VERSION ""

NS_ :

BS_:

BU_: WCM VPM VLM VKM UVM TIM TEST_TOOL_2 TEST_TOOL_1 TCP TCM TCCM3 TCCM STC SRR_SRR SRR_SLR SRR_RR SRR_RF SRR_LR_CR SRR_LF SIB SDM SCL SBZA_R SBZA_L SBM SADS RadioLow RSC RDCM PTM PDR PA NVM MTCM_R MTCM_L MSM_RR MSM_P MSM_LR MSM_D MSB2 MSB1 MRCM_R MRCM_L MFC LRR_HC LRR LIB1 IPC ICS_Info ICCM HVAC_FP_R HVAC_FP_F HUD_CAN HDLM FCM_LC FCM EPS EOCM_HCP2 EOCM_HCP1 EOCM ELM ECP_X1 ECP_MC ECP_E ECM EBCM DMS DEFC DCM CSM CMMb CMMa CGM BSM_MH BSM BCM ARS ARB APA AOS AMP ALC AHS AHL_AFL AGC
VAL_TABLE_ SRRSRRODPB1P_POTk1DynPrpAuth 0 "Has Never Moved" 1 "Has Moved But Currently Stopped" 2 "Moving In Same Direction As Host" 3 "Moving In Opposite Direction As Host" 4 "Crossing Path" ;
VAL_TABLE_ SRRSRRODPB1P_POTk1CnfdStsAuth 0 "Highly Speculative" 1 "Speculative" 2 "Confident" 3 "Highly Confident" ;
VAL_TABLE_ SRRSRRODPB1P_MdCmdStsAuth 0 "Not Radiating" 1 "Reporting Object Data" 2 "Not Reporting Object Data" ;
VAL_TABLE_ SRRSRRODPB1P_CnstrArDtnStsAuth 0 "Not Detected" 1 "Detected" 2 "Unknown" ;
VAL_TABLE_ SRRSRRODPB1P_POTk1MStsAuth 0 "No Object" 1 "New Object" 2 "Latent Track Not Detected this Cycle" 3 "Measured this Cycle" ;
VAL_TABLE_ SRRSRRODPB1P_POTk2CnfdStsAuth 0 "Highly Speculative" 1 "Speculative" 2 "Confident" 3 "Highly Confident" ;
VAL_TABLE_ SRRSRRODPB1P_POTk1TypCnfdAuth 0 "Highly Speculative" 1 "Speculative" 2 "Confident" 3 "Highly Confident" ;
VAL_TABLE_ SRRSRRODPB1P_POTk1TypAuth 0 "Unknown" 1 "Pedestrian" 2 "Bicycle" ;
VAL_TABLE_ SRRSRRODPB1P_POTk2DynPrpAuth 0 "Has Never Moved" 1 "Has Moved But Currently Stopped" 2 "Moving In Same Direction As Host" 3 "Moving In Opposite Direction As Host" 4 "Crossing Path" ;
VAL_TABLE_ SRRSRRODPB1P_POTk2MStsAuth 0 "No Object" 1 "New Object" 2 "Latent Track Not Detected this Cycle" 3 "Measured this Cycle" ;
VAL_TABLE_ SRRSRRODPB1P_POTk2TypCnfdAuth 0 "Highly Speculative" 1 "Speculative" 2 "Confident" 3 "Highly Confident" ;
VAL_TABLE_ SRRSRRODPB1P_POTk2TypAuth 0 "Unknown" 1 "Pedestrian" 2 "Bicycle" ;
VAL_TABLE_ SRRSRRODPB1P_SnsrUnvAuth 0 "FALSE" 1 "TRUE" ;
VAL_TABLE_ SRRSRRODPB1P_SnsrBlckdAuth 0 "FALSE" 1 "TRUE" ;
VAL_TABLE_ SRRSRRODPB1P_ServRqrdAuth 0 "FALSE" 1 "TRUE" ;
VAL_TABLE_ SRRSRRODPB1P_RdTypCnfdAuth 0 "Highly Speculative" 1 "Speculative" 2 "Confident" 3 "Highly Confident" ;
VAL_TABLE_ SRRSRRODPB1P_RdTypAuth 0 "Unknown" 1 "City" 2 "Secondary Road" 3 "Highway" 4 "Construction" 5 "Zone Entry" 6 "Construction" 7 "Zone Exit" ;
VAL_TABLE_ SRRSRRODPB1P_SwpBndwdthStsAuth 0 "Mode A" 1 "Mode B" 2 "Mode C" 3 "Mode D" ;
VAL_TABLE_ SRRSRRODPB1P_VOTk1DynPrpStsAuth 0 "Stopped" 1 "Not Stopped" ;
VAL_TABLE_ SRRSRRODPB1P_VOTk1DynPrpAuth 0 "Has Never Moved" 1 "Moving In Same Direction As Host" 2 "Moving In Opposite Direction As Host" 3 "Crossing From Left To Right" 4 "Crossing From Right To Left" ;
VAL_TABLE_ SRRSRRODPB1P_VOTk1CnfdStsAuth 0 "Highly Speculative" 1 "Speculative" 2 "Confident" 3 "Highly Confident" ;
VAL_TABLE_ SRRSRRODPB1P_VOTk1MStsAuth 0 "No Object" 1 "New Object" 2 "Latent Track Not Detected this Cycle" 3 "Measured this Cycle" ;
VAL_TABLE_ SRRSRRODPB1P_VOTk1TypCnfdAuth 0 "Highly Speculative" 1 "Speculative" 2 "Confident" 3 "Highly Confident" ;
VAL_TABLE_ SRRSRRODPB6P_REOTk1CnfdStsAuth 0 "Highly Speculative" 1 "Speculative" 2 "Confident" 3 "Highly Confident" ;
VAL_TABLE_ SRRSRRODPB6P_REOTk2CnfdStsAuth 0 "Highly Speculative" 1 "Speculative" 2 "Confident" 3 "Highly Confident" ;
VAL_TABLE_ SRRSRRODPB6P_REOTk1TypCnfdAuth 0 "Highly Speculative" 1 "Speculative" 2 "Confident" 3 "Highly Confident" ;
VAL_TABLE_ SRRSRRODPB6P_REOTk1TypAuth 0 "Unknown" 1 "Barriers" 2 "Guard Rails" 3 "Bridge Abutments" 4 "Edge of Road" 5 "Open Area" ;
VAL_TABLE_ SRRSRRODPB6P_REOTk3CnfdStsAuth 0 "Highly Speculative" 1 "Speculative" 2 "Confident" 3 "Highly Confident" ;
VAL_TABLE_ SRRSRRODPB6P_REOTk2TypCnfdAuth 0 "Highly Speculative" 1 "Speculative" 2 "Confident" 3 "Highly Confident" ;
VAL_TABLE_ SRRSRRODPB6P_REOTk2TypAuth 0 "Unknown" 1 "Barriers" 2 "Guard Rails" 3 "Bridge Abutments" 4 "Edge of Road" 5 "Open Area" ;
VAL_TABLE_ SRRSRRODPB6P_REOTk3TypCnfdAuth 0 "Highly Speculative" 1 "Speculative" 2 "Confident" 3 "Highly Confident" ;
VAL_TABLE_ SRRSRRODPB6P_REOTk3TypAuth 0 "Unknown" 1 "Barriers" 2 "Guard Rails" 3 "Bridge Abutments" 4 "Edge of Road" 5 "Open Area" ;
VAL_TABLE_ YRP_YawRateAuth_Inv 0 "FALSE" 1 "TRUE" ;
VAL_TABLE_ SWIP_StrgWhlAngAuth_Inv 0 "FALSE" 1 "TRUE" ;
VAL_TABLE_ SWIP_StrgWhlAngAuth_DuD 0 "FALSE" 1 "TRUE" ;
VAL_TABLE_ DRCDNDP_DRCAvgDrvnAuth_Inv 0 "FALSE" 1 "TRUE" ;
VAL_TABLE_ VODVP_VehOdoDispValAuth_Inv 0 "FALSE" 1 "TRUE" ;
VAL_TABLE_ OATP_OtsAirTmpCrValAuth_Inv 0 "FALSE" 1 "TRUE" ;
VAL_TABLE_ CldrMth 0 "Unknown" 1 "January" 2 "February" 3 "March" 4 "April" 5 "May" 6 "June" 7 "July" 8 "August" 9 "September" 10 "October" 11 "November" 12 "December" ;
VAL_TABLE_ ELWWIP_WprFrtFtrReqAuth 0 "Wiper Front Stop" 1 "Wiper Front Crank Suspend" 2 "Wiper Front Depressed Park" 3 "Wiper Front Park" 4 "Wiper Front Winter Park" 5 "Wiper Front Service Park" 6 "Wiper Front Intermittent 5" 7 "Wiper Front Intermittent 4" 8 "Wiper Front Intermittent 3" 9 "Wiper Front Intermittent 2" 10 "Wiper Front Intermittent 1" 11 "Wiper Front Low Wipe" 12 "Wiper Front High Wipe" ;
VAL_TABLE_ VMMP_VehMtnMvmtStatAuth 0 "Parked" 1 "Neutral" 2 "Forward" 3 "Reverse" 4 "Invalid" ;
VAL_TABLE_ SBZVisIndExtrnCktFltPrLtGtd 0 "FALSE" 1 "TRUE" ;
VAL_TABLE_ SBZVisIndExtrnCktFltPrLtGtd_Inv 0 "FALSE" 1 "TRUE" ;
VAL_TABLE_ DrSlctdSpdLmtAutMdSpdLmtStat 0 "No Set Speed Change" 1 "Proposed Speed Limit Change" 2 "Accepted Speed Limit Change" 3 "Declined Speed Limit Change" ;
VAL_TABLE_ AutoBmSlctAllwd 0 "FALSE" 1 "TRUE" ;
VAL_TABLE_ AutoBmSlctAllwd_Inv 0 "FALSE" 1 "TRUE" ;
VAL_TABLE_ TrlrHtchTyp 0 "Unknown" 1 "Conventional" 2 "5th Wheel" 3 "Gooseneck" ;
VAL_TABLE_ DrvrSeltdTrlrPrsnt 0 "Trailer Present" 1 "No Trailer" ;
VAL_TABLE_ FgLmpFrtRtCmd 0 "FALSE" 1 "TRUE" ;
VAL_TABLE_ FgLmpFrtLftCmd 0 "FALSE" 1 "TRUE" ;
VAL_TABLE_ LogisticModeStatus 0 "Off" 1 "Plant" 2 "Transport Mode" 3 "Storage Mode" ;
VAL_TABLE_ SBZVisIndExtrnCktFltPrRtGtd 0 "FALSE" 1 "TRUE" ;
VAL_TABLE_ SBZVisIndExtrnCktFltPrRtGtd_Inv 0 "FALSE" 1 "TRUE" ;
VAL_TABLE_ SBZAlrtCstChngSetReq 0 "NO_ACTION" 1 "OFF" 2 "ON" 3 "RESERVED_3" 4 "RESERVED_4" 5 "RESERVED_5" 6 "RESERVED_6" 7 "RESERVED_7" ;
VAL_TABLE_ LnChgAlrtCstChngSetReq 0 "NO_ACTION" 1 "OFF" 2 "ON" 3 "RESERVED_3" 4 "RESERVED_4" 5 "RESERVED_5" 6 "RESERVED_6" 7 "RESERVED_7" ;
VAL_TABLE_ APASP_APAStsAuth 0 "Off" 1 "Standby" 2 "Search_Phase" 3 "Exit_Park" 4 "Enabled" 5 "Guidance_Phase" 6 "Finished" 7 "Error" ;
VAL_TABLE_ HSP_DrvAlrtTypCstCurrSetValAuth 0 "SETTING_UNKNOWN" 1 "CHIME" 2 "SEAT" ;
VAL_TABLE_ HSP_HptcStOprtlStsAuth 0 "Normal Operation" 1 "Unknown" 2 "Failed" ;
VAL_TABLE_ TrffcLgtAsstCstChgSetReq 0 "NO_ACTION" 1 "OFF" 2 "ALERT" 3 "RESERVED_3" 4 "RESERVED_4" 5 "RESERVED_5" 6 "RESERVED_6" 7 "RESERVED_7" ;
VAL_TABLE_ RrCrsTrfcAlrtCstChngSetReq 0 "NO_ACTION" 1 "OFF" 2 "ALERT" 3 "ALERT AND BRAKE" 4 "RESERVED_4" 5 "RESERVED_5" 6 "RESERVED_6" 7 "RESERVED_7" ;
VAL_TABLE_ GlrFrHgBmRspTypCstChgSetReq 0 "NO_ACTION" 1 "AUTOMATIC_HIGH_BEAM" 2 "GLARE_FREE_HIGH_BEAM" 3 "RESERVED_3" 4 "RESERVED_4" 5 "RESERVED_5" 6 "RESERVED_6" 7 "RESERVED_7" ;
VAL_TABLE_ TSMWrngPopUpSts 0 "TSM Warning Off" 1 "TSM Warning On" ;
VAL_TABLE_ TSMSgnNtfnWrnDispd 0 "FALSE" 1 "TRUE" ;
VAL_TABLE_ TSMPageDispActv 0 "FALSE" 1 "TRUE" ;
VAL_TABLE_ TSMCustRstReq 0 "FALSE" 1 "TRUE" ;
VAL_TABLE_ RstrCstDfltReq 0 "FALSE" 1 "TRUE" ;
VAL_TABLE_ DispMeasSysExtnd 0 "US" 1 "IMPERIAL" 2 "Metric KM/L" 3 "Metric L/100KM" ;
VAL_TABLE_ BGI1P_OutsdAmbtLgtLvlStsAuth 0 "Unknown" 1 "Day" 2 "Night" ;
VAL_TABLE_ LowBmAct 0 "FALSE" 1 "TRUE" ;
VAL_TABLE_ HighBmAct 0 "FALSE" 1 "TRUE" ;
VAL_TABLE_ TrnSigSwRtActv 0 "FALSE" 1 "TRUE" ;
VAL_TABLE_ TrnSigSwLtActv 0 "FALSE" 1 "TRUE" ;
VAL_TABLE_ TrlrConnStat 0 "Not Connected" 1 "Connected" ;
VAL_TABLE_ TimeDispFormat 0 "12 Hour Mode" 1 "24 Hour Mode" ;
VAL_TABLE_ TDAP_TeenDrvrActvAuth 0 "FALSE" 1 "TRUE" ;
VAL_TABLE_ RrCrsTrfcBrkgSysSts 0 "Not Active" 1 "Active" 2 "Failed" ;
VAL_TABLE_ TDAP_DrvrIdfrAuth 0 "Driver 1" 1 "Driver 2" 2 "Driver 3" 3 "Driver 4" 4 "Driver 5" 5 "Driver 6" 6 "Driver 7" 7 "Unknown" ;
VAL_TABLE_ BkUpPwrMdRnCrnkOutSt 0 "FALSE" 1 "TRUE" ;
VAL_TABLE_ DTCI_EOCM_HCP2_CnfrmdDTC 0 "FALSE" 1 "TRUE" ;
VAL_TABLE_ DTCI_EOCM_HCP2_DTCFaultType 0 "Not Supported" 1 "Type A" 2 "Type B" 3 "Type C" ;
VAL_TABLE_ DTCI_EOCM_HCP2_TstNCmpltdOpCyc 0 "FALSE" 1 "TRUE" ;
VAL_TABLE_ DTCI_EOCM_HCP2_TstNCmpltdLstClr 0 "FALSE" 1 "TRUE" ;
VAL_TABLE_ DTCI_EOCM_HCP2_TstFldOpCyc 0 "FALSE" 1 "TRUE" ;
VAL_TABLE_ DTCI_EOCM_HCP2_TstFldLstClr 0 "FALSE" 1 "TRUE" ;
VAL_TABLE_ DTCI_EOCM_HCP2_TstFld 0 "FALSE" 1 "TRUE" ;
VAL_TABLE_ DTCI_EOCM_HCP2_PndngDTC 0 "FALSE" 1 "TRUE" ;
VAL_TABLE_ DTCI_EOCM_HCP2_DTCTriggered 0 "FALSE" 1 "TRUE" ;
VAL_TABLE_ DTCI_EOCM_HCP2_WrnIndTrggrd 0 "FALSE" 1 "TRUE" ;
VAL_TABLE_ DTCI_EOCM_HCP2_WrnIndRqd 0 "FALSE" 1 "TRUE" ;
VAL_TABLE_ DTCI_FCM_LC_CnfrmdDTC 0 "FALSE" 1 "TRUE" ;
VAL_TABLE_ DTCI_FCM_LC_DTCFaultType 0 "Not Supported" 1 "Type A" 2 "Type B" 3 "Type C" ;
VAL_TABLE_ DTCI_FCM_LC_TstNCmpltdOpCyc 0 "FALSE" 1 "TRUE" ;
VAL_TABLE_ DTCI_FCM_LC_TstNCmpltdLstClr 0 "FALSE" 1 "TRUE" ;
VAL_TABLE_ DTCI_FCM_LC_TstFldOpCyc 0 "FALSE" 1 "TRUE" ;
VAL_TABLE_ DTCI_FCM_LC_TstFldLstClr 0 "FALSE" 1 "TRUE" ;
VAL_TABLE_ DTCI_FCM_LC_TstFld 0 "FALSE" 1 "TRUE" ;
VAL_TABLE_ DTCI_FCM_LC_PndngDTC 0 "FALSE" 1 "TRUE" ;
VAL_TABLE_ DTCI_FCM_LC_DTCTriggered 0 "FALSE" 1 "TRUE" ;
VAL_TABLE_ DTCI_FCM_LC_WrnIndTrggrd 0 "FALSE" 1 "TRUE" ;
VAL_TABLE_ DTCI_FCM_LC_WrnIndRqd 0 "FALSE" 1 "TRUE" ;
VAL_TABLE_ DTCI_HDLM_CnfrmdDTC 0 "FALSE" 1 "TRUE" ;
VAL_TABLE_ DTCI_HDLM_DTCFaultType 0 "Not Supported" 1 "Type A" 2 "Type B" 3 "Type C" ;
VAL_TABLE_ DTCI_HDLM_TstNCmpltdOpCyc 0 "FALSE" 1 "TRUE" ;
VAL_TABLE_ DTCI_HDLM_TstNCmpltdLstClr 0 "FALSE" 1 "TRUE" ;
VAL_TABLE_ DTCI_HDLM_TstFldOpCyc 0 "FALSE" 1 "TRUE" ;
VAL_TABLE_ DTCI_HDLM_TstFldLstClr 0 "FALSE" 1 "TRUE" ;
VAL_TABLE_ DTCI_HDLM_TstFld 0 "FALSE" 1 "TRUE" ;
VAL_TABLE_ DTCI_HDLM_PndngDTC 0 "FALSE" 1 "TRUE" ;
VAL_TABLE_ DTCI_HDLM_DTCTriggered 0 "FALSE" 1 "TRUE" ;
VAL_TABLE_ DTCI_HDLM_WrnIndTrggrd 0 "FALSE" 1 "TRUE" ;
VAL_TABLE_ DTCI_HDLM_WrnIndRqd 0 "FALSE" 1 "TRUE" ;
VAL_TABLE_ DTCI_LRR_HC_CnfrmdDTC 0 "FALSE" 1 "TRUE" ;
VAL_TABLE_ DTCI_LRR_HC_DTCFaultType 0 "Not Supported" 1 "Type A" 2 "Type B" 3 "Type C" ;
VAL_TABLE_ DTCI_LRR_HC_TstNCmpltdOpCyc 0 "FALSE" 1 "TRUE" ;
VAL_TABLE_ DTCI_LRR_HC_TstNCmpltdLstClr 0 "FALSE" 1 "TRUE" ;
VAL_TABLE_ DTCI_LRR_HC_TstFldOpCyc 0 "FALSE" 1 "TRUE" ;
VAL_TABLE_ DTCI_LRR_HC_TstFldLstClr 0 "FALSE" 1 "TRUE" ;
VAL_TABLE_ DTCI_LRR_HC_TstFld 0 "FALSE" 1 "TRUE" ;
VAL_TABLE_ DTCI_LRR_HC_PndngDTC 0 "FALSE" 1 "TRUE" ;
VAL_TABLE_ DTCI_LRR_HC_DTCTriggered 0 "FALSE" 1 "TRUE" ;
VAL_TABLE_ DTCI_LRR_HC_WrnIndTrggrd 0 "FALSE" 1 "TRUE" ;
VAL_TABLE_ DTCI_LRR_HC_WrnIndRqd 0 "FALSE" 1 "TRUE" ;
VAL_TABLE_ DTCI_LRR_CnfrmdDTC 0 "FALSE" 1 "TRUE" ;
VAL_TABLE_ DTCI_LRR_DTCFaultType 0 "Not Supported" 1 "Type A" 2 "Type B" 3 "Type C" ;
VAL_TABLE_ DTCI_LRR_TstNCmpltdOpCyc 0 "FALSE" 1 "TRUE" ;
VAL_TABLE_ DTCI_LRR_TstNCmpltdLstClr 0 "FALSE" 1 "TRUE" ;
VAL_TABLE_ DTCI_LRR_TstFldOpCyc 0 "FALSE" 1 "TRUE" ;
VAL_TABLE_ DTCI_LRR_TstFldLstClr 0 "FALSE" 1 "TRUE" ;
VAL_TABLE_ DTCI_LRR_TstFld 0 "FALSE" 1 "TRUE" ;
VAL_TABLE_ DTCI_LRR_PndngDTC 0 "FALSE" 1 "TRUE" ;
VAL_TABLE_ DTCI_LRR_DTCTriggered 0 "FALSE" 1 "TRUE" ;
VAL_TABLE_ DTCI_LRR_WrnIndTrggrd 0 "FALSE" 1 "TRUE" ;
VAL_TABLE_ DTCI_LRR_WrnIndRqd 0 "FALSE" 1 "TRUE" ;
VAL_TABLE_ DTCI_SRR_LF_CnfrmdDTC 0 "FALSE" 1 "TRUE" ;
VAL_TABLE_ DTCI_SRR_LF_DTCFaultType 0 "Not Supported" 1 "Type A" 2 "Type B" 3 "Type C" ;
VAL_TABLE_ DTCI_SRR_LF_TstNCmpltdOpCyc 0 "FALSE" 1 "TRUE" ;
VAL_TABLE_ DTCI_SRR_LF_TstNCmpltdLstClr 0 "FALSE" 1 "TRUE" ;
VAL_TABLE_ DTCI_SRR_LF_TstFldOpCyc 0 "FALSE" 1 "TRUE" ;
VAL_TABLE_ DTCI_SRR_LF_TstFldLstClr 0 "FALSE" 1 "TRUE" ;
VAL_TABLE_ DTCI_SRR_LF_TstFld 0 "FALSE" 1 "TRUE" ;
VAL_TABLE_ DTCI_SRR_LF_PndngDTC 0 "FALSE" 1 "TRUE" ;
VAL_TABLE_ DTCI_SRR_LF_DTCTriggered 0 "FALSE" 1 "TRUE" ;
VAL_TABLE_ DTCI_SRR_LF_WrnIndTrggrd 0 "FALSE" 1 "TRUE" ;
VAL_TABLE_ DTCI_SRR_LF_WrnIndRqd 0 "FALSE" 1 "TRUE" ;
VAL_TABLE_ DTCI_SRR_LR_CR_CnfrmdDTC 0 "FALSE" 1 "TRUE" ;
VAL_TABLE_ DTCI_SRR_LR_CR_DTCFaultType 0 "Not Supported" 1 "Type A" 2 "Type B" 3 "Type C" ;
VAL_TABLE_ DTCI_SRR_LR_CR_TstNCmpltdOpCyc 0 "FALSE" 1 "TRUE" ;
VAL_TABLE_ DTCI_SRR_LR_CR_TstNCmpltdLstClr 0 "FALSE" 1 "TRUE" ;
VAL_TABLE_ DTCI_SRR_LR_CR_TstFldOpCyc 0 "FALSE" 1 "TRUE" ;
VAL_TABLE_ DTCI_SRR_LR_CR_TstFldLstClr 0 "FALSE" 1 "TRUE" ;
VAL_TABLE_ DTCI_SRR_LR_CR_TstFld 0 "FALSE" 1 "TRUE" ;
VAL_TABLE_ DTCI_SRR_LR_CR_PndngDTC 0 "FALSE" 1 "TRUE" ;
VAL_TABLE_ DTCI_SRR_LR_CR_DTCTriggered 0 "FALSE" 1 "TRUE" ;
VAL_TABLE_ DTCI_SRR_LR_CR_WrnIndTrggrd 0 "FALSE" 1 "TRUE" ;
VAL_TABLE_ DTCI_SRR_LR_CR_WrnIndRqd 0 "FALSE" 1 "TRUE" ;
VAL_TABLE_ DTCI_SRR_RF_CnfrmdDTC 0 "FALSE" 1 "TRUE" ;
VAL_TABLE_ DTCI_SRR_RF_DTCFaultType 0 "Not Supported" 1 "Type A" 2 "Type B" 3 "Type C" ;
VAL_TABLE_ DTCI_SRR_RF_TstNCmpltdOpCyc 0 "FALSE" 1 "TRUE" ;
VAL_TABLE_ DTCI_SRR_RF_TstNCmpltdLstClr 0 "FALSE" 1 "TRUE" ;
VAL_TABLE_ DTCI_SRR_RF_TstFldOpCyc 0 "FALSE" 1 "TRUE" ;
VAL_TABLE_ DTCI_SRR_RF_TstFldLstClr 0 "FALSE" 1 "TRUE" ;
VAL_TABLE_ DTCI_SRR_RF_TstFld 0 "FALSE" 1 "TRUE" ;
VAL_TABLE_ DTCI_SRR_RF_PndngDTC 0 "FALSE" 1 "TRUE" ;
VAL_TABLE_ DTCI_SRR_RF_DTCTriggered 0 "FALSE" 1 "TRUE" ;
VAL_TABLE_ DTCI_SRR_RF_WrnIndTrggrd 0 "FALSE" 1 "TRUE" ;
VAL_TABLE_ DTCI_SRR_RF_WrnIndRqd 0 "FALSE" 1 "TRUE" ;
VAL_TABLE_ DTCI_SRR_RR_CnfrmdDTC 0 "FALSE" 1 "TRUE" ;
VAL_TABLE_ DTCI_SRR_RR_DTCFaultType 0 "Not Supported" 1 "Type A" 2 "Type B" 3 "Type C" ;
VAL_TABLE_ DTCI_SRR_RR_TstNCmpltdOpCyc 0 "FALSE" 1 "TRUE" ;
VAL_TABLE_ DTCI_SRR_RR_TstNCmpltdLstClr 0 "FALSE" 1 "TRUE" ;
VAL_TABLE_ DTCI_SRR_RR_TstFldOpCyc 0 "FALSE" 1 "TRUE" ;
VAL_TABLE_ DTCI_SRR_RR_TstFldLstClr 0 "FALSE" 1 "TRUE" ;
VAL_TABLE_ DTCI_SRR_RR_TstFld 0 "FALSE" 1 "TRUE" ;
VAL_TABLE_ DTCI_SRR_RR_PndngDTC 0 "FALSE" 1 "TRUE" ;
VAL_TABLE_ DTCI_SRR_RR_DTCTriggered 0 "FALSE" 1 "TRUE" ;
VAL_TABLE_ DTCI_SRR_RR_WrnIndTrggrd 0 "FALSE" 1 "TRUE" ;
VAL_TABLE_ DTCI_SRR_RR_WrnIndRqd 0 "FALSE" 1 "TRUE" ;
VAL_TABLE_ DTCI_SRR_SLR_CnfrmdDTC 0 "FALSE" 1 "TRUE" ;
VAL_TABLE_ DTCI_SRR_SLR_DTCFaultType 0 "Not Supported" 1 "Type A" 2 "Type B" 3 "Type C" ;
VAL_TABLE_ DTCI_SRR_SLR_TstNCmpltdOpCyc 0 "FALSE" 1 "TRUE" ;
VAL_TABLE_ DTCI_SRR_SLR_TstNCmpltdLstClr 0 "FALSE" 1 "TRUE" ;
VAL_TABLE_ DTCI_SRR_SLR_TstFldOpCyc 0 "FALSE" 1 "TRUE" ;
VAL_TABLE_ DTCI_SRR_SLR_TstFldLstClr 0 "FALSE" 1 "TRUE" ;
VAL_TABLE_ DTCI_SRR_SLR_TstFld 0 "FALSE" 1 "TRUE" ;
VAL_TABLE_ DTCI_SRR_SLR_PndngDTC 0 "FALSE" 1 "TRUE" ;
VAL_TABLE_ DTCI_SRR_SLR_DTCTriggered 0 "FALSE" 1 "TRUE" ;
VAL_TABLE_ DTCI_SRR_SLR_WrnIndTrggrd 0 "FALSE" 1 "TRUE" ;
VAL_TABLE_ DTCI_SRR_SLR_WrnIndRqd 0 "FALSE" 1 "TRUE" ;
VAL_TABLE_ DTCI_SRR_SRR_CnfrmdDTC 0 "FALSE" 1 "TRUE" ;
VAL_TABLE_ DTCI_SRR_SRR_DTCFaultType 0 "Not Supported" 1 "Type A" 2 "Type B" 3 "Type C" ;
VAL_TABLE_ DTCI_SRR_SRR_TstNCmpltdOpCyc 0 "FALSE" 1 "TRUE" ;
VAL_TABLE_ DTCI_SRR_SRR_TstNCmpltdLstClr 0 "FALSE" 1 "TRUE" ;
VAL_TABLE_ DTCI_SRR_SRR_TstFldOpCyc 0 "FALSE" 1 "TRUE" ;
VAL_TABLE_ DTCI_SRR_SRR_TstFldLstClr 0 "FALSE" 1 "TRUE" ;
VAL_TABLE_ DTCI_SRR_SRR_TstFld 0 "FALSE" 1 "TRUE" ;
VAL_TABLE_ DTCI_SRR_SRR_PndngDTC 0 "FALSE" 1 "TRUE" ;
VAL_TABLE_ DTCI_SRR_SRR_DTCTriggered 0 "FALSE" 1 "TRUE" ;
VAL_TABLE_ DTCI_SRR_SRR_WrnIndTrggrd 0 "FALSE" 1 "TRUE" ;
VAL_TABLE_ DTCI_SRR_SRR_WrnIndRqd 0 "FALSE" 1 "TRUE" ;
VAL_TABLE_ ACCAutoStSpStat 0 "No_Set_Speed_Change" 1 "Proposed_Speed_Limit_Change" 2 "Accepted_Speed_Limit_Change" 3 "Declined_Speed_Limit_Change" ;
VAL_TABLE_ ACCBRP_ACCActvAuth 0 "FALSE" 1 "TRUE" ;
VAL_TABLE_ LnDprtrWrnCtlSdThrtRtMirIndReq 0 "Off" 1 "Solid" 2 "Flashing" 3 "No Action" ;
VAL_TABLE_ LnDprtrWrnCtlSdThrtLtMirIndReq 0 "Off" 1 "Solid" 2 "Flashing" 3 "No Action" ;
VAL_TABLE_ EPBSP_ElecPrkBrkApplStsAuth 0 "Unknown" 1 "Applied" 2 "Released" 3 "Dynamic Apply" 4 "In-Progress" ;
VAL_TABLE_ TrffcLgtAsstCstAvlFlg1 0 "FALSE" 1 "TRUE" ;
VAL_TABLE_ GlrFrHgBmRspTypCstAvlFlg7 0 "FALSE" 1 "TRUE" ;
VAL_TABLE_ GlrFrHgBmRspTypCstAvlFlg6 0 "FALSE" 1 "TRUE" ;
VAL_TABLE_ GlrFrHgBmRspTypCstAvlFlg5 0 "FALSE" 1 "TRUE" ;
VAL_TABLE_ GlrFrHgBmRspTypCstAvlFlg4 0 "FALSE" 1 "TRUE" ;
VAL_TABLE_ GlrFrHgBmRspTypCstAvlFlg3 0 "FALSE" 1 "TRUE" ;
VAL_TABLE_ GlrFrHgBmRspTypCstAvlFlg2 0 "FALSE" 1 "TRUE" ;
VAL_TABLE_ GlrFrHgBmRspTypCstAvlFlg1 0 "FALSE" 1 "TRUE" ;
VAL_TABLE_ TrffcLgtAsstCstAvlFlg7 0 "FALSE" 1 "TRUE" ;
VAL_TABLE_ TrffcLgtAsstCstAvlFlg6 0 "FALSE" 1 "TRUE" ;
VAL_TABLE_ TrffcLgtAsstCstAvlFlg5 0 "FALSE" 1 "TRUE" ;
VAL_TABLE_ TrffcLgtAsstCstAvlFlg4 0 "FALSE" 1 "TRUE" ;
VAL_TABLE_ TrffcLgtAsstCstAvlFlg3 0 "FALSE" 1 "TRUE" ;
VAL_TABLE_ TrffcLgtAsstCstAvlFlg2 0 "FALSE" 1 "TRUE" ;
VAL_TABLE_ TrffcLgtAsstWrnChmEvntStat 0 "NO_ACTION" 1 "ACTIVE" 2 "CANCEL_CHIME" 3 "RESERVED_1" ;
VAL_TABLE_ AutoHgBmCtrlIO 0 "FALSE" 1 "TRUE" ;
VAL_TABLE_ TrffcLgtAsstCstSetAval 0 "FALSE" 1 "TRUE" ;
VAL_TABLE_ GlrFrHgBmRspTypCstStAvl 0 "FALSE" 1 "TRUE" ;
VAL_TABLE_ TrffcLgtAsstCstCurrSetVal 0 "SETTING_UNKNOWN" 1 "OFF" 2 "ALERT" 3 "RESERVED_3" 4 "RESERVED_4" 5 "RESERVED_5" 6 "RESERVED_6" 7 "RESERVED_7" ;
VAL_TABLE_ GlrFrHgBmRspTypCstCurSetVal 0 "SETTING_UNKNOWN" 1 "AUTOMATIC_HIGH_BEAM" 2 "GLARE_FREE_HIGH_BEAM" 3 "RESERVED_3" 4 "\?? RESERVED_4" 5 "RESERVED_5" 6 "RESERVED_6" 7 "RESERVED_7" ;
VAL_TABLE_ FsdLoclzdRdTyp 0 "Unknown" 1 "Limited Access Road" 2 "Not Limited Access Road" ;
VAL_TABLE_ GPSC_PPSLat_Inv 0 "FALSE" 1 "TRUE" ;
VAL_TABLE_ GPSC_PPSLong_Inv 0 "FALSE" 1 "TRUE" ;
VAL_TABLE_ TSMEurDispSgn2Mn 0 "UnKnown" 1 "No Sign Detected" 2 "End of Speed Limit" 3 "End of All Restrictions" 4 "Begin of Motorway" 5 "End of Motorway" 6 "Begin of Expressway" 7 "End of Expressway" 8 "Begin of Play Street Zone" 9 "End of Play Street Zone" 10 "Begin of Passing Restriction" 11 "End of Passing Restriction" 12 "No Entry" 13 "Begin of City Limits" 14 "End of City Limits" 15 "Speed Limit 5" 16 "Speed Limit 10" 17 "Speed Limit 15" 18 "Speed Limit 20" 19 "Speed Limit 25" 20 "Speed Limit 30" 21 "Speed Limit 35" 22 "Speed Limit 40" 23 "Speed Limit 45" 24 "Speed Limit 50" 25 "Speed Limit 55" 26 "Speed Limit 60" 27 "Speed Limit 65" 28 "Speed Limit 70" 29 "Speed Limit 75" 30 "Speed Limit 80" 31 "Speed Limit 85" 32 "Speed Limit 90" 33 "Speed Limit 95" 34 "Speed Limit 100" 35 "Speed Limit 105" 36 "Speed Limit 110" 37 "Speed Limit 115" 38 "Speed Limit 120" 39 "Speed Limit 125" 40 "Speed Limit 130" 41 "Speed Limit 135" 42 "Speed Limit 140" 43 "Speed Limit 145" 44 "Speed Limit 150" 45 "Speed Limit 155" 46 "Speed Limit 160" 47 "Speed Limit 165" 48 "Speed Limit 170" 49 "Speed Limit 175" 50 "Speed Limit 180" 51 "Speed Limit 185" 52 "Speed Limit 190" 53 "Speed Limit 195" 54 "Speed Limit 200" ;
VAL_TABLE_ TSMEurDispSgn1Mn 0 "UnKnown" 1 "No Sign Detected" 2 "End of Speed Limit" 3 "End of All Restrictions" 4 "Begin of Motorway" 5 "End of Motorway" 6 "Begin of Expressway" 7 "End of Expressway" 8 "Begin of Play Street Zone" 9 "End of Play Street Zone" 10 "Begin of Passing Restriction" 11 "End of Passing Restriction" 12 "No Entry" 13 "Begin of City Limits" 14 "End of City Limits" 15 "Speed Limit 5" 16 "Speed Limit 10" 17 "Speed Limit 15" 18 "Speed Limit 20" 19 "Speed Limit 25" 20 "Speed Limit 30" 21 "Speed Limit 35" 22 "Speed Limit 40" 23 "Speed Limit 45" 24 "Speed Limit 50" 25 "Speed Limit 55" 26 "Speed Limit 60" 27 "Speed Limit 65" 28 "Speed Limit 70" 29 "Speed Limit 75" 30 "Speed Limit 80" 31 "Speed Limit 85" 32 "Speed Limit 90" 33 "Speed Limit 95" 34 "Speed Limit 100" 35 "Speed Limit 105" 36 "Speed Limit 110" 37 "Speed Limit 115" 38 "Speed Limit 120" 39 "Speed Limit 125" 40 "Speed Limit 130" 41 "Speed Limit 135" 42 "Speed Limit 140" 43 "Speed Limit 145" 44 "Speed Limit 150" 45 "Speed Limit 155" 46 "Speed Limit 160" 47 "Speed Limit 165" 48 "Speed Limit 170" 49 "Speed Limit 175" 50 "Speed Limit 180" 51 "Speed Limit 185" 52 "Speed Limit 190" 53 "Speed Limit 195" 54 "Speed Limit 200" ;
VAL_TABLE_ TSMUSAndCADispSgn1Mn 0 "UnKnown" 1 "No Sign Detected" 2 "Begin of Passing Restriction US" 3 "End of Passing Restriction US" 4 "Begin of Passing Restriction Canada" 5 "End of Passing Restriction Canada" 6 "Speed Limit 5" 7 "Speed Limit 10" 8 "Speed Limit 15" 9 "Speed Limit 20" 10 "Speed Limit 25" 11 "Speed Limit 30" 12 "Speed Limit 35" 13 "Speed Limit 40" 14 "Speed Limit 45" 15 "Speed Limit 50" 16 "Speed Limit 55" 17 "Speed Limit 60" 18 "Speed Limit 65" 19 "Speed Limit 70" 20 "Speed Limit 75" 21 "Speed Limit 80" 22 "Speed Limit 85" 23 "Speed Limit 90" 24 "Speed Limit 95" 25 "Speed Limit 100" 26 "Speed Limit 105" 27 "Speed Limit 110" 28 "Speed Limit 115" 29 "Speed Limit 120" 30 "Speed Limit 125" 31 "Speed Limit 130" 32 "Speed Limit 135" 33 "Speed Limit 140" 34 "Speed Limit 145" 35 "Speed Limit 150" 36 "Speed Limit 155" 37 "Speed Limit 160" 38 "Speed Limit 165" 39 "Speed Limit 170" 40 "Speed Limit 175" 41 "Speed Limit 180" 42 "Speed Limit 185" 43 "Speed Limit 190" 44 "Speed Limit 195" 45 "Speed Limit 200" ;
VAL_TABLE_ TSMUSAndCADispSgn2Mn 0 "UnKnown" 1 "No Sign Detected" 2 "Begin of Passing Restriction US" 3 "End of Passing Restriction US" 4 "Begin of Passing Restriction Canada" 5 "End of Passing Restriction Canada" 6 "Speed Limit 5" 7 "Speed Limit 10" 8 "Speed Limit 15" 9 "Speed Limit 20" 10 "Speed Limit 25" 11 "Speed Limit 30" 12 "Speed Limit 35" 13 "Speed Limit 40" 14 "Speed Limit 45" 15 "Speed Limit 50" 16 "Speed Limit 55" 17 "Speed Limit 60" 18 "Speed Limit 65" 19 "Speed Limit 70" 20 "Speed Limit 75" 21 "Speed Limit 80" 22 "Speed Limit 85" 23 "Speed Limit 90" 24 "Speed Limit 95" 25 "Speed Limit 100" 26 "Speed Limit 105" 27 "Speed Limit 110" 28 "Speed Limit 115" 29 "Speed Limit 120" 30 "Speed Limit 125" 31 "Speed Limit 130" 32 "Speed Limit 135" 33 "Speed Limit 140" 34 "Speed Limit 145" 35 "Speed Limit 150" 36 "Speed Limit 155" 37 "Speed Limit 160" 38 "Speed Limit 165" 39 "Speed Limit 170" 40 "Speed Limit 175" 41 "Speed Limit 180" 42 "Speed Limit 185" 43 "Speed Limit 190" 44 "Speed Limit 195" 45 "Speed Limit 200" ;
VAL_TABLE_ TSMEurDispSgn2AddOn 0 "UnKnown" 1 "None" 2 "Supp Sign Generic" 3 "Rain" 4 "Snow" 5 "Snow Rain" 6 "Rain Cloud" 7 "Fog" 8 "Time" 9 "Wet Conditions" 10 "Trailer" 11 "Tractor Passable" 12 "Arrow Left" 13 "Arrow Right" 14 "Distance Arrow" 15 "School" ;
VAL_TABLE_ TSMEurDispSgn1AddOn 0 "UnKnown" 1 "None" 2 "Supp Sign Generic" 3 "Rain" 4 "Snow" 5 "Snow Rain" 6 "Rain Cloud" 7 "Fog" 8 "Time" 9 "Wet Conditions" 10 "Trailer" 11 "Tractor Passable" 12 "Arrow Left" 13 "Arrow Right" 14 "Distance Arrow" 15 "School" ;
VAL_TABLE_ FrwdVsFlDtcnIndOn 0 "FALSE" 1 "TRUE" ;
VAL_TABLE_ FrwdVsAdvWthrIndOn 0 "FALSE" 1 "TRUE" ;
VAL_TABLE_ TSMUSAndCADispSgn2AddOn 0 "None" 1 "Supp Sign Generic" 2 "School" 3 "School When Flashing" 4 "End of Speed Limit" 5 "Where Workers Present" ;
VAL_TABLE_ TSMUSAndCADispSgn1AddOn 0 "None" 1 "Supp Sign Generic" 2 "School" 3 "School When Flashing" 4 "End of Speed Limit" 5 "Where Workers Present" ;
VAL_TABLE_ TrffcLgtAsstHUDWrnIndOn 0 "FALSE" 1 "TRUE" ;
VAL_TABLE_ TrffcLgtAsstClstrWrnIndOn 0 "FALSE" 1 "TRUE" ;
VAL_TABLE_ TSMSgnNtfnIndOn 0 "FALSE" 1 "TRUE" ;
VAL_TABLE_ TSMPDAMnSgnFlshgReq 0 "FALSE" 1 "TRUE" ;
VAL_TABLE_ TSMNoEntryIndOn 0 "FALSE" 1 "TRUE" ;
VAL_TABLE_ TSMIcePsblIndOn 0 "FALSE" 1 "TRUE" ;
VAL_TABLE_ TSMAddTrfSgnAvIndOn 0 "FALSE" 1 "TRUE" ;
VAL_TABLE_ FrwdVsFllBlckIndOn 0 "FALSE" 1 "TRUE" ;
VAL_TABLE_ TrffcLgtAsstRLADWrnIndOn 0 "FALSE" 1 "TRUE" ;
VAL_TABLE_ ADASIS_NAVILINK_DgtlMpEfSpdLm 0 "UNKNOWN" 1 "<= 5 KM/H [MPH]" 2 "7 KM/H [MPH]" 3 "10 KM/H [MPH]" 4 "15 KM/H [MPH]" 5 "20 KM/H [MPH]" 6 "25 KM/H [MPH]" 7 "30 KM/H [MPH]" 8 "35 KM/H [MPH]" 9 "40 KM/H [MPH]" 10 "45 KM/H [MPH]" 11 "50 KM/H [MPH]" 12 "55 KM/H [MPH]" 13 "60 KM/H" 14 "MPH]65 KM/H [MPH]" 15 "70 KM/H [MPH]" 16 "75 KM/H [MPH]" 17 "80 KM/H [MPH]" 18 "85 KM/H [MPH]" 19 "90 KM/H [MPH]" 20 "95 KM/H [MPH]" 21 "100 KM/H [MPH]" 22 "105 KM/H [MPH]" 23 "110 KM/H [MPH]" 24 "115 KM/H [MPH]" 25 "120 KM/H[MPH]" 26 "130 KM/H [MPH]" 27 "140 KM/H [MPH]" 28 "150 KM/H [MPH]" 29 "160 KM/H [MPH]" 30 "UNLIMITED" 31 "NOT AVAILABLE" ;
VAL_TABLE_ ADASIS_NAVILINK_CntryCd 0 "AD" 1 "AT" 2 "BE" 3 "CZ" 4 "DK" 5 "EE" 6 "FR" 7 "DE" 8 "GR" 9 "HU" 10 "IE" 11 "IT" 12 "BY" 13 "BG" 14 "CY" 15 "MT" 16 "HR" 17 "TR" 18 "RS" 19 "ME" 20 "LV" 21 "LT" 22 "LU" 23 "NL" 24 "NO" 25 "PL" 26 "PT" 27 "UK" 28 "SK" 29 "SI" 30 "ES" 31 "SE" 32 "CH" 33 "RO" 34 "RU" 35 "UA" 36 "BA" 37 "AL" 38 "MD" 39 "IS" 40 "MK" 41 "US" 42 "ZA" 43 "AU" 44 "NZ" 45 "KR" 46 "CN" ;
VAL_TABLE_ ADASIS_NAVILINK_DigMpCndlSpdLmt 0 "UNKNOWN" 1 "<= 5 KM/H [MPH]" 2 "7 KM/H [MPH]" 3 "10 KM/H [MPH]" 4 "15 KM/H [MPH]" 5 "20 KM/H [MPH]" 6 "25 KM/H [MPH]" 7 "30 KM/H [MPH]" 8 "35 KM/H [MPH]" 9 "40 KM/H [MPH]" 10 "45 KM/H [MPH]" 11 "50 KM/H [MPH]" 12 "55 KM/H [MPH]" 13 "60 KM/H" 14 "MPH]65 KM/H [MPH]" 15 "70 KM/H [MPH]" 16 "75 KM/H [MPH]" 17 "80 KM/H [MPH]" 18 "85 KM/H [MPH]" 19 "90 KM/H [MPH]" 20 "95 KM/H [MPH]" 21 "100 KM/H [MPH]" 22 "105 KM/H [MPH]" 23 "110 KM/H [MPH]" 24 "115 KM/H [MPH]" 25 "120 KM/H[MPH]" 26 "130 KM/H [MPH]" 27 "140 KM/H [MPH]" 28 "150 KM/H [MPH]" 29 "160 KM/H [MPH]" 30 "UNLIMITED" 31 "NOT AVAILABLE" ;
VAL_TABLE_ ADASIS_NAVILINK_DgtlMpSpdCtgry 0 "> 130 KPH OR > 80 MPH" 1 "101-130 KPH OR 65\???80 MPH" 2 "91-100 KPH OR 55\???64 MPH" 3 "71-90 KPH OR 41\???54 MPH" 4 "51-70 KPH OR 31\???40 MPH" 5 "31-50 KPH OR 21\???30 MPH" 6 "11-30 KPH OR 6 \???20 MPH" 7 "<11 KPH OR < 6 MPH" 8 "UNKNOWN" ;
VAL_TABLE_ ADASIS_NAVILINK_DgtlMpPsngRst 0 "NO PASSING RESTRICTIONS" 1 "GENERAL NO OVERTAKE" 2 "FLUCTUATING (E.G. LED SIGNS)" 3 "CONDITIONAL PASSENGER CAR WITH TRAILER" 4 "CONDITIONAL TRACTORS ARE ALLOWED TO OVERTAKE" 5 "CONDITIONAL WHEN WET" 6 "CONDITIONAL WHEN SNOW" 7 "UNKNOWN CONDITION" ;
VAL_TABLE_ ADASIS_NAVILINK_DigMpEfSpdLmTyp 0 "IMPLICIT" 1 "ON TRAFFIC SIGN" 2 "ONLY BY NIGHT" 3 "ONLY BY DAY" 4 "TIME OF DAY" 5 "ONLY BY RAIN" 6 "ONLY BY SNOW OR FOG" 7 "UNKOWN" ;
VAL_TABLE_ ADASIS_NAVILINK_DgMpCnSpdLmTyp 0 "LANE DEPENDENT" 1 "ONLY BY FOG" 2 "ONLY BY NIGHT" 3 "ONLY BY DAY" 4 "BY TIME OF DAY" 5 "ONLY BY RAIN" 6 "ONLY BY SNOW" 7 "UNKNOWN" ;
VAL_TABLE_ ADASIS_NAVILINK_DigMpPstSpdLmAs 0 "NOT ASSURED" 1 "ASSURED" ;
VAL_TABLE_ ADASIS_NAVILINK_DigMpDrvngSd 0 "DRIVING SIDE LEFT" 1 "DRIVING SIDE RIGHT" ;
VAL_TABLE_ ADASIS_NAVILINK_CntrldAccssRd 0 "ROAD IS NOT CONTROLLED ACCESS ROAD" 1 "ROAD IS CONTROLLED ACCESS ROAD" ;
VAL_TABLE_ ADASIS_NAVILINK_BldUpFlg 0 "NOT VALID" 1 "VALID" ;
VAL_TABLE_ ADASIS_NAVILINK_FncRdClss 0 "LOCAL" 1 "SFREEWAY" 2 "FREEWAY" 3 "PED-MALL" 4 "HIGHWAY" 5 "ARTERIAL" 6 "ALLEY" 7 "COLLECTOR" ;
VAL_TABLE_ ADASIS_NAVILINK_DigMpVerYr 0 "2000" 1 "2001" 2 "2002" 3 "2003" 4 "2004" 5 "2005" 6 "2006" 7 "2007" 8 "2008" 9 "2009" 10 "2010" 11 "2011" 12 "2012" 13 "2013" 14 "2014" 15 "2015" 16 "2016" 17 "2017" 18 "2018" 19 "2019" 20 "2020" 21 "2021" 22 "2022" 23 "2023" 24 "2024" 25 "2025" 26 "2026" 27 "2027" 28 "2028" 29 "2029" 30 "2030" 31 "2031" 32 "2032" 33 "2033" 34 "2034" 35 "2035" 36 "2036" 37 "2037" 38 "2038" 39 "2039" 40 "2040" 41 "2041" 42 "2042" 43 "2043" 44 "2044" 45 "2045" 46 "2046" 47 "2047" 48 "2048" 49 "2049" 50 "2050" 51 "2051" 52 "2052" 53 "2053" 54 "2054" 55 "2055" 56 "2056" 57 "2057" 58 "2058" 59 "2059" 60 "2060" 61 "2061" 62 "2062" 63 "NOT APPLICABLE" ;
VAL_TABLE_ ADASIS_NAVILINK_SpdLmtUnt 0 "MILES/H" 1 "KM/H" ;
VAL_TABLE_ ADASIS_NAVILINK_SpdLmtPsdSpd_DuD 0 "FALSE" 1 "TRUE" ;
VAL_TABLE_ ADASIS_NAVILINK_MpDtAv 0 "NOT VALID" 1 "VALID" ;
VAL_TABLE_ ADASIS_NAVILINK_LnCtgry 0 "NO INFO AVAILABLE" 1 "ONE LANE" 2 "TWO OR THREE LANES" 3 "FOUR OR MORE LANES" ;
VAL_TABLE_ ADASIS_NAVILINK_DigMpVerQtr 0 "QUARTER 1" 1 "QUARTER 2" 2 "QUARTER 3" 3 "QUARTER 4" ;
VAL_TABLE_ ADASIS_NAVILINK_SprtdLnRd 0 "ROAD IS NOT CONTROLLED ACCESS ROAD" 1 "ROAD IS CONTROLLED ACCESS ROAD" ;
VAL_TABLE_ EASSI_StrtStpSt 0 "Engine Off" 1 "Engine Running" 2 "Engine Starting" 3 "Engine Stopping" ;
VAL_TABLE_ HVPPP_ShrtRngRadarModeCmdAuth 0 "Not Radiating" 1 "Not Reporting Object Data" 2 "Reporting Object Data" ;
VAL_TABLE_ HVPPP_LngRngRadarModeCmdAuth 0 "Not Radiating" 1 "Not Reporting Object Data" 2 "Reporting" ;
VAL_TABLE_ HVPPP_HstVehLatVelAuth_Inv 0 "FALSE" 1 "TRUE" ;
VAL_TABLE_ HVPPP_HstVehVelAuth_Inv 0 "FALSE" 1 "TRUE" ;
VAL_TABLE_ HVPPP_ObjsRetndRrwdSnsrsAuth 0 "Unknown" 1 "Objects Reported" 2 "No Objects Reported" ;
VAL_TABLE_ HVPPP_HstVehLngVelAuth_Inv 0 "FALSE" 1 "TRUE" ;
VAL_TABLE_ HVPPP_ObjsRetndFrwdSnsrsAuth 0 "Unknown" 1 "Objects Reported" 2 "No Objects Reported" ;
VAL_TABLE_ HVPPP_HstVehPathModeAuth 0 "Disabled" 1 "Low Speed" 2 "High Speed" ;
VAL_TABLE_ HVPPP_HstVehYawRateAuth_Inv 0 "FALSE" 1 "TRUE" ;
VAL_TABLE_ HVPPP_HstVehTrvlDirAuth 0 "Unknown" 1 "Forward or Stopped on a Forward Gear" 2 "Reversed or Stopped in a Reverse Gear" 3 "Other" ;
VAL_TABLE_ HVPPP_FrwdVsnModeCmdAuth 0 "Not Reporting Object Data" 1 "Reporting Object Data" ;
VAL_TABLE_ LLDP_LatAccelSnsrCorrStsAuth 0 "Unknown" 1 "NA" 2 "Correlated" 3 "Uncorellated" ;
VAL_TABLE_ LLDP_LatAccelAuth_Inv 0 "FALSE" 1 "TRUE" ;
VAL_TABLE_ LLDP_LongAccelAuth_Inv 0 "FALSE" 1 "TRUE" ;
VAL_TABLE_ LLDP_VehAccelCalAuth 0 "FALSE" 1 "TRUE" ;
VAL_TABLE_ LLDP_VehAccelAuth_DuD 0 "FALSE" 1 "TRUE" ;
VAL_TABLE_ LLDP_LongAccelSnsrCorrStsAuth 0 "Unknown" 1 "NA" 2 "Correlated" 3 "Uncorellated" ;
VAL_TABLE_ NodeStsAPA_CAN_2_LcFA 0 "FALSE" 1 "TRUE" ;
VAL_TABLE_ NodeStsAPA_CAN_1_LcFA 0 "FALSE" 1 "TRUE" ;
VAL_TABLE_ NodeStsAOS_LcFA 0 "FALSE" 1 "TRUE" ;
VAL_TABLE_ NodeStsAMP_LcFA 0 "FALSE" 1 "TRUE" ;
VAL_TABLE_ NodeStsALC_LcFA 0 "FALSE" 1 "TRUE" ;
VAL_TABLE_ NodeStsAHL_AFL_LcFA 0 "FALSE" 1 "TRUE" ;
VAL_TABLE_ NodeStsAGC_LcFA 0 "FALSE" 1 "TRUE" ;
VAL_TABLE_ NodeStsDMS_LcFA 0 "FALSE" 1 "TRUE" ;
VAL_TABLE_ NodeStsDEFC_LcFA 0 "FALSE" 1 "TRUE" ;
VAL_TABLE_ NodeStsDCM_LcFA 0 "FALSE" 1 "TRUE" ;
VAL_TABLE_ NodeStsCSM_LcFA 0 "FALSE" 1 "TRUE" ;
VAL_TABLE_ NodeStsBSM_CAN_3_LcFA 0 "FALSE" 1 "TRUE" ;
VAL_TABLE_ NodeStsBSM_CAN_2_LcFA 0 "FALSE" 1 "TRUE" ;
VAL_TABLE_ NodeStsBCM_LcFA 0 "FALSE" 1 "TRUE" ;
VAL_TABLE_ NodeStsARB_LcFA 0 "FALSE" 1 "TRUE" ;
VAL_TABLE_ NodeStsELM_LcFA 0 "FALSE" 1 "TRUE" ;
VAL_TABLE_ NodeStsECP_X1_CAN_3_LcFA 0 "FALSE" 1 "TRUE" ;
VAL_TABLE_ NodeStsECP_X1_CAN_2_LcFA 0 "FALSE" 1 "TRUE" ;
VAL_TABLE_ NodeStsECM_CAN_3_LcFA 0 "FALSE" 1 "TRUE" ;
VAL_TABLE_ NodeStsECM_CAN_2_LcFA 0 "FALSE" 1 "TRUE" ;
VAL_TABLE_ NodeStsEBCM_CAN_2_LcFA 0 "FALSE" 1 "TRUE" ;
VAL_TABLE_ NodeStsEBCM_CAN_1_LcFA 0 "FALSE" 1 "TRUE" ;
VAL_TABLE_ NodeStsEPS_LcFA 0 "FALSE" 1 "TRUE" ;
VAL_TABLE_ NodeStsEOCM_HCP2_LcFA 0 "FALSE" 1 "TRUE" ;
VAL_TABLE_ NodeStsEOCM_HCP1_CAN_8_LcFA 0 "FALSE" 1 "TRUE" ;
VAL_TABLE_ NodeStsEOCM_HCP1_CAN_2_LcFA 0 "FALSE" 1 "TRUE" ;
VAL_TABLE_ NodeStsEOCM_HCP1_CAN_1_LcFA 0 "FALSE" 1 "TRUE" ;
VAL_TABLE_ NodeStsEOCM_CAN_8_LcFA 0 "FALSE" 1 "TRUE" ;
VAL_TABLE_ NodeStsEOCM_CAN_2_LcFA 0 "FALSE" 1 "TRUE" ;
VAL_TABLE_ NodeStsEOCM_CAN_1_LcFA 0 "FALSE" 1 "TRUE" ;
VAL_TABLE_ NodeStsIPC_LcFA 0 "FALSE" 1 "TRUE" ;
VAL_TABLE_ NodeStsICS_Info_LcFA 0 "FALSE" 1 "TRUE" ;
VAL_TABLE_ NodeStsICCM_LcFA 0 "FALSE" 1 "TRUE" ;
VAL_TABLE_ NodeStsHVAC_FP_R_LcFA 0 "FALSE" 1 "TRUE" ;
VAL_TABLE_ NodeStsHVAC_FP_F_LcFA 0 "FALSE" 1 "TRUE" ;
VAL_TABLE_ NodeStsHUD_CAN_LcFA 0 "FALSE" 1 "TRUE" ;
VAL_TABLE_ NodeStsFCM_LcFA 0 "FALSE" 1 "TRUE" ;
VAL_TABLE_ NodeStsFCM_LC_LcFA 0 "FALSE" 1 "TRUE" ;
VAL_TABLE_ NodeStsMSM_D_LcFA 0 "FALSE" 1 "TRUE" ;
VAL_TABLE_ NodeStsMSB2_LcFA 0 "FALSE" 1 "TRUE" ;
VAL_TABLE_ NodeStsMSB1_LcFA 0 "FALSE" 1 "TRUE" ;
VAL_TABLE_ NodeStsMRCM_R_LcFA 0 "FALSE" 1 "TRUE" ;
VAL_TABLE_ NodeStsMRCM_L_LcFA 0 "FALSE" 1 "TRUE" ;
VAL_TABLE_ NodeStsMFC_LcFA 0 "FALSE" 1 "TRUE" ;
VAL_TABLE_ NodeStsLRR_LcFA 0 "FALSE" 1 "TRUE" ;
VAL_TABLE_ NodeStsLRR_HC_LcFA 0 "FALSE" 1 "TRUE" ;
VAL_TABLE_ NodeStsPDR_LcFA 0 "FALSE" 1 "TRUE" ;
VAL_TABLE_ NodeStsPA_LcFA 0 "FALSE" 1 "TRUE" ;
VAL_TABLE_ NodeStsNVM_LcFA 0 "FALSE" 1 "TRUE" ;
VAL_TABLE_ NodeStsMTCM_R_LcFA 0 "FALSE" 1 "TRUE" ;
VAL_TABLE_ NodeStsMTCM_L_LcFA 0 "FALSE" 1 "TRUE" ;
VAL_TABLE_ NodeStsMSM_RR_LcFA 0 "FALSE" 1 "TRUE" ;
VAL_TABLE_ NodeStsMSM_P_LcFA 0 "FALSE" 1 "TRUE" ;
VAL_TABLE_ NodeStsMSM_LR_LcFA 0 "FALSE" 1 "TRUE" ;
VAL_TABLE_ NodeStsSBZA_R_LcFA 0 "FALSE" 1 "TRUE" ;
VAL_TABLE_ NodeStsSBZA_L_LcFA 0 "FALSE" 1 "TRUE" ;
VAL_TABLE_ NodeStsSADS_LcFA 0 "FALSE" 1 "TRUE" ;
VAL_TABLE_ NodeStsAHS_LcFA 0 "FALSE" 1 "TRUE" ;
VAL_TABLE_ NodeStsRSC_LcFA 0 "FALSE" 1 "TRUE" ;
VAL_TABLE_ NodeStsRDCM_LcFA 0 "FALSE" 1 "TRUE" ;
VAL_TABLE_ NodeStsRadioLow_LcFA 0 "FALSE" 1 "TRUE" ;
VAL_TABLE_ NodeStsPTM_LcFA 0 "FALSE" 1 "TRUE" ;
VAL_TABLE_ NodeStsSRR_SLR_LcFA 0 "FALSE" 1 "TRUE" ;
VAL_TABLE_ NodeStsSRR_RR_LcFA 0 "FALSE" 1 "TRUE" ;
VAL_TABLE_ NodeStsSRR_RF_LcFA 0 "FALSE" 1 "TRUE" ;
VAL_TABLE_ NodeStsSRR_LR_CR_LcFA 0 "FALSE" 1 "TRUE" ;
VAL_TABLE_ NodeStsSRR_LF_LcFA 0 "FALSE" 1 "TRUE" ;
VAL_TABLE_ NodeStsSIB_LcFA 0 "FALSE" 1 "TRUE" ;
VAL_TABLE_ NodeStsSDM_LcFA 0 "FALSE" 1 "TRUE" ;
VAL_TABLE_ NodeStsSCL_LcFA 0 "FALSE" 1 "TRUE" ;
VAL_TABLE_ NodeStsTIM_LcFA 0 "FALSE" 1 "TRUE" ;
VAL_TABLE_ NodeStsTCP_LcFA 0 "FALSE" 1 "TRUE" ;
VAL_TABLE_ NodeStsTCM_LcFA 0 "FALSE" 1 "TRUE" ;
VAL_TABLE_ NodeStsTCCM3_LcFA 0 "FALSE" 1 "TRUE" ;
VAL_TABLE_ NodeStsTCCM_LcFA 0 "FALSE" 1 "TRUE" ;
VAL_TABLE_ NodeStsSTC_LcFA 0 "FALSE" 1 "TRUE" ;
VAL_TABLE_ NodeStsSRR_SRR_LcFA 0 "FALSE" 1 "TRUE" ;
VAL_TABLE_ NodeStsECP_E_CAN_9_LcFA 0 "FALSE" 1 "TRUE" ;
VAL_TABLE_ NodeStsCMMb_CAN_2_LcFA 0 "FALSE" 1 "TRUE" ;
VAL_TABLE_ NodeStsCMMa_CAN_2_LcFA 0 "FALSE" 1 "TRUE" ;
VAL_TABLE_ NodeStsARS_LcFA 0 "FALSE" 1 "TRUE" ;
VAL_TABLE_ NodeStsVLM_LcFA 0 "FALSE" 1 "TRUE" ;
VAL_TABLE_ NodeStsWCM_LcFA 0 "FALSE" 1 "TRUE" ;
VAL_TABLE_ NodeStsVPM_LcFA 0 "FALSE" 1 "TRUE" ;
VAL_TABLE_ NodeStsVKM_LcFA 0 "FALSE" 1 "TRUE" ;
VAL_TABLE_ NodeStsECP_E_CAN_2_LcFA 0 "FALSE" 1 "TRUE" ;
VAL_TABLE_ NodeStsECP_MC_LcFA 0 "FALSE" 1 "TRUE" ;
VAL_TABLE_ NodeStsCMMb_CAN_9_LcFA 0 "FALSE" 1 "TRUE" ;
VAL_TABLE_ NodeStsCMMa_CAN_9_LcFA 0 "FALSE" 1 "TRUE" ;
VAL_TABLE_ NodeStsBSM_MH_LcFA 0 "FALSE" 1 "TRUE" ;
VAL_TABLE_ NodeStsSBM_CAN_9_LcFA 0 "FALSE" 1 "TRUE" ;
VAL_TABLE_ NodeStsSBM_CAN_10_LcFA 0 "FALSE" 1 "TRUE" ;
VAL_TABLE_ NodeStsLIB1_LcFA 0 "FALSE" 1 "TRUE" ;
VAL_TABLE_ NodeStsHDLM_LcFA 0 "FALSE" 1 "TRUE" ;
VAL_TABLE_ PSP_VehTheftImbChlgRespStsAuth 0 "Undetermined" 1 "Pass" 2 "Fail" ;
VAL_TABLE_ PSP_RmtVehStrtEngRnngAuth 0 "FALSE" 1 "TRUE" ;
VAL_TABLE_ PSP_PwrtrnCrnkAbrtdAuth 0 "FALSE" 1 "TRUE" ;
VAL_TABLE_ PSP_PrplSysStlActvAuth 0 "FALSE" 1 "TRUE" ;
VAL_TABLE_ PSP_PrplSysActvAuth 0 "FALSE" 1 "TRUE" ;
VAL_TABLE_ PSP_EngRnngAuth 0 "FALSE" 1 "TRUE" ;
VAL_TABLE_ PSP_ClchBtmTrvlAchvdAuth_Inv 0 "FALSE" 1 "TRUE" ;
VAL_TABLE_ PSP_ClchBtmTrvlAchvdAuth 0 "FALSE" 1 "TRUE" ;
VAL_TABLE_ PSP_PrkNeutSwStatAuth_Inv 0 "FALSE" 1 "TRUE" ;
VAL_TABLE_ PSP_PrkNeutSwStatAuth 0 "Park/Neutral" 1 "Not Park/Neutral" ;
VAL_TABLE_ RrCrsTrfcBrkgAutoBrkgRelIndOn 0 "FALSE" 1 "TRUE" ;
VAL_TABLE_ RrCrsTrfcBrkgAutoBrkgReqdRt 0 "FALSE" 1 "TRUE" ;
VAL_TABLE_ RCTBAD_BrkgReqd 0 "FALSE" 1 "TRUE" ;
VAL_TABLE_ RCTBAD_BrkgReqTyp 0 "None" 1 "Hold" ;
VAL_TABLE_ LtFstAprchgVehObjDtd 0 "FALSE" 1 "TRUE" ;
VAL_TABLE_ RtFstAprchgVehObjDtd 0 "FALSE" 1 "TRUE" ;
VAL_TABLE_ RtSdObjDtdAdjTrlr 0 "FALSE" 1 "TRUE" ;
VAL_TABLE_ SRRLRCODPGI1P_TrlrDtdAuth 0 "FALSE" 1 "TRUE" ;
VAL_TABLE_ SRRRRODPGI1P_TrlrDtdAuth 0 "FALSE" 1 "TRUE" ;
VAL_TABLE_ SRRSLRODPGI1P_TrlrDtdAuth 0 "FALSE" 1 "TRUE" ;
VAL_TABLE_ SRRSRRODPGI1P_TrlrDtdAuth 0 "FALSE" 1 "TRUE" ;
VAL_TABLE_ SBZALCACRrActv 0 "FALSE" 1 "TRUE" ;
VAL_TABLE_ SBZALCACRrOprtlSts 0 "Normal Operation" 1 "Needs Service" 2 "Temporary Unavailable" ;
VAL_TABLE_ LtSdObjDtdAdjTrlr 0 "FALSE" 1 "TRUE" ;
VAL_TABLE_ SBZALCARRActv 0 "FALSE" 1 "TRUE" ;
VAL_TABLE_ SBZALCARROprtlSts 0 "Normal Operation" 1 "Needs Service" 2 "Temporary Unavailable" ;
VAL_TABLE_ RrCrsTrfcAlrtCstAvlFlg1 0 "FALSE" 1 "TRUE" ;
VAL_TABLE_ LnChgAlrtCstAvlFlg7 0 "FALSE" 1 "TRUE" ;
VAL_TABLE_ LnChgAlrtCstAvlFlg6 0 "FALSE" 1 "TRUE" ;
VAL_TABLE_ LnChgAlrtCstAvlFlg5 0 "FALSE" 1 "TRUE" ;
VAL_TABLE_ LnChgAlrtCstAvlFlg4 0 "FALSE" 1 "TRUE" ;
VAL_TABLE_ LnChgAlrtCstAvlFlg3 0 "FALSE" 1 "TRUE" ;
VAL_TABLE_ LnChgAlrtCstAvlFlg2 0 "FALSE" 1 "TRUE" ;
VAL_TABLE_ LnChgAlrtCstAvlFlg1 0 "FALSE" 1 "TRUE" ;
VAL_TABLE_ RrCrsTrfcAlrtCstAvlFlg7 0 "FALSE" 1 "TRUE" ;
VAL_TABLE_ RrCrsTrfcAlrtCstAvlFlg6 0 "FALSE" 1 "TRUE" ;
VAL_TABLE_ RrCrsTrfcAlrtCstAvlFlg5 0 "FALSE" 1 "TRUE" ;
VAL_TABLE_ RrCrsTrfcAlrtCstAvlFlg4 0 "FALSE" 1 "TRUE" ;
VAL_TABLE_ RrCrsTrfcAlrtCstAvlFlg3 0 "FALSE" 1 "TRUE" ;
VAL_TABLE_ RrCrsTrfcAlrtCstAvlFlg2 0 "FALSE" 1 "TRUE" ;
VAL_TABLE_ RrCrsTrfcAlrtLtSdChmEvntStat 0 "NO_ACTION" 1 "ACTIVE" 2 "CANCEL_CHIME" ;
VAL_TABLE_ RrCrsTrfcAlrtLftIndCtrl 0 "ON" 1 "OFF" 2 "FLASH" ;
VAL_TABLE_ RrCrsTrfcAutoBrkgOffIndOn 0 "FALSE" 1 "TRUE" ;
VAL_TABLE_ SBZALCAOvrllSts 0 "FALSE" 1 "TRUE" ;
VAL_TABLE_ RrCrsTrfcAlrtOffIndOn 0 "FALSE" 1 "TRUE" ;
VAL_TABLE_ RCTAOvrllSts 0 "FALSE" 1 "TRUE" ;
VAL_TABLE_ LtSdVehObjDtd 0 "FALSE" 1 "TRUE" ;
VAL_TABLE_ RrCrsTrfcAlrtCstStAvl 0 "FALSE" 1 "TRUE" ;
VAL_TABLE_ LnChgAlrtCstStAvl 0 "FALSE" 1 "TRUE" ;
VAL_TABLE_ RrCrsTrfcAlrtCstCrStVal 0 "SETTING_UNKNOWN" 1 "OFF" 2 "ALERT" 3 "ALERT and BRAKE" 4 "RESERVED_4" 5 "RESERVED_5" 6 "RESERVED_6" 7 "RESERVED_7" ;
VAL_TABLE_ LnChgAlrtCstCrStVal 0 "SETTING_UNKNOWN" 1 "OFF" 2 "ON" 3 "RESERVED_3" 4 "RESERVED_4" 5 "RESERVED_5" 6 "RESERVED_6" 7 "RESERVED_7" ;
VAL_TABLE_ RrCrsTrfcAlrtRtSdChmEvntStat 0 "NO_ACTION" 1 "ACTIVE" 2 "CANCEL_CHIME" ;
VAL_TABLE_ RrCrsTrfcAlrtRgIndCtrl 0 "ON" 1 "OFF" 2 "FLASH" ;
VAL_TABLE_ SBZALCARtSts 0 "FALSE" 1 "TRUE" ;
VAL_TABLE_ RtSdVehObjDtd 0 "FALSE" 1 "TRUE" ;
VAL_TABLE_ RCTARtSts 0 "FALSE" 1 "TRUE" ;
VAL_TABLE_ SBZALCAROpStat 0 "NORMAL OPERATION" 1 "NEEDS SERVICE" 2 "TEMPORARY UNAVAILABLE" ;
VAL_TABLE_ SBZALCAOvrllOplSts 0 "NORMAL OPERATION" 1 "NEEDS SERVICE" 2 "TEMPORARY UNAVAILABLE" ;
VAL_TABLE_ SBZAlrtCstAvlFlg1 0 "FALSE" 1 "TRUE" ;
VAL_TABLE_ LnChgAlrtSysOffIndOn 0 "FALSE" 1 "TRUE" ;
VAL_TABLE_ LnChgAlrtLmtdTrlrIndOn 0 "FALSE" 1 "TRUE" ;
VAL_TABLE_ SBZALCAVisIndStatLt 0 "FLASHING" 1 "SOLID" 2 "OFF" ;
VAL_TABLE_ SBZAlrtCstCrStVal 0 "SETTING_UNKNOWN" 1 "OFF" 2 "ON" 3 "RESERVED_3" 4 "RESERVED_4" 5 "RESERVED_5" 6 "RESERVED_6" 7 "RESERVED_7" ;
VAL_TABLE_ SBZAlrtOffIndOn 0 "FALSE" 1 "TRUE" ;
VAL_TABLE_ SBZAlrtCstStAvl 0 "FALSE" 1 "TRUE" ;
VAL_TABLE_ SBZAlrtCstAvlFlg7 0 "FALSE" 1 "TRUE" ;
VAL_TABLE_ SBZAlrtCstAvlFlg6 0 "FALSE" 1 "TRUE" ;
VAL_TABLE_ SBZAlrtCstAvlFlg5 0 "FALSE" 1 "TRUE" ;
VAL_TABLE_ SBZAlrtCstAvlFlg4 0 "FALSE" 1 "TRUE" ;
VAL_TABLE_ SBZAlrtCstAvlFlg3 0 "FALSE" 1 "TRUE" ;
VAL_TABLE_ SBZAlrtCstAvlFlg2 0 "FALSE" 1 "TRUE" ;
VAL_TABLE_ ServSdDtcSysIndOn 0 "FALSE" 1 "TRUE" ;
VAL_TABLE_ SdDtcTempUnvIndOn 0 "FALSE" 1 "TRUE" ;
VAL_TABLE_ SBZALCAVisIndStatRt 0 "FLASHING" 1 "SOLID" 2 "OFF" ;
VAL_TABLE_ SLVFSP_SpdLimVsnFsdSpdUntAuth 0 "km/h" 1 "mph" ;
VAL_TABLE_ SLVFSP_SpdLimVsnFsdSpdNwDtdAuth 0 "FALSE" 1 "TRUE" ;
VAL_TABLE_ SLVFSP_SpdLimVsnFsdSpdAuth_DuD 0 "FALSE" 1 "TRUE" ;
VAL_TABLE_ SGI2P_AirSpnsnRdHghtLwrActnAuth 0 "None" 1 "Slow" 2 "Medium (Exhaust)" 3 "Fast" ;
VAL_TABLE_ SGI2P_AirSpnsnRdHghtActvAxlAuth 0 "None" 1 "Front" 2 "Rear" 3 "Both" 4 "Pending" ;
VAL_TABLE_ SGI2P_AirSpnsnRdHghtActlStsAuth 0 "Faulted" 1 "Entry/Exit" 2 "Lowered 3(Stability)" 3 "Lowered 2 (Sport)" 4 "Lowered 1 (Aero)" 5 "Showroom" 6 "Normal" 7 "Raised 1" 8 "Raised 2" 9 "Raised 3" ;
VAL_TABLE_ SGI2P_AirSpnsnRdHghtTgtStsAuth 0 "Faulted" 1 "Entry/Exit" 2 "Lowered 3(Stability)" 3 "Lowered 2 (Sport)" 4 "Lowered 1 (Aero)" 5 "Showroom" 6 "Normal" 7 "Raised 1" 8 "Raised 2" 9 "Raised 3" ;
VAL_TABLE_ SGI2P_AirSpnsnRdHghtRseActnAuth 0 "None" 1 "Slow(i.e. compressor)" 2 "Medium (i.e. Boost)" 3 "Fast (i.e. Reservoir)" ;
VAL_TABLE_ SPMP_SysPwrModeAuth_Inv 0 "FALSE" 1 "TRUE" ;
VAL_TABLE_ SPMP_SysPwrModeAuth 0 "Off" 1 "Accessory" 2 "Run" 3 "Start Request" 4 "Propulsion" ;
VAL_TABLE_ SPMP_PriRunCrnkCmdActvAuth_Inv 0 "FALSE" 1 "TRUE" ;
VAL_TABLE_ SPMP_PriRunCrnkCmdActvAuth 0 "FALSE" 1 "TRUE" ;
VAL_TABLE_ TEGP_TrnsEstGrAuth 0 "Not Supported" 1 "First Gear" 2 "Second Gear" 3 "Third Gear" 4 "Fourth Gear" 5 "Fifth Gear" 6 "Sixth Gear" 7 "Seventh Gear" 8 "Eighth Gear" 9 "Ninth Gear" 10 "Tenth Gear" 11 "Unused and Reserved" 12 "CVT Forward Gear" 13 "Neutral Gear" 14 "Reverse Gear" 15 "Park Gear" ;
VAL_TABLE_ TEGP_TransCmndGrAuth 0 "Not Supported" 1 "First Gear" 2 "Second Gear" 3 "Third Gear" 4 "Fourth Gear" 5 "Fifth Gear" 6 "Sixth Gear" 7 "Seventh Gear" 8 "Eighth Gear" 9 "Ninth Gear" 10 "Tenth Gear" 11 "Unused and Reserved" 12 "CVT Forward Gear" 13 "Neutral Gear" 14 "Reverse Gear" 15 "Park Gear" ;
VAL_TABLE_ TEGP_TrnsEngdStAuth_Inv 0 "FALSE" 1 "TRUE" ;
VAL_TABLE_ TEGP_TrnsShftLvrPstnAuth 0 "Between Ranges" 1 "Park Range" 2 "Reverse Range" 3 "Neutral Range" 4 "Forward Range A" 5 "Forward Range B" 6 "Forward Range C" 7 "Forward Range D" 8 "Forward Range E" 9 "Forward Range F" 10 "Forward Range G" 11 "Forward Range H" 12 "Forward Range I" 13 "Forward Range J" 14 "Lever Position Unknown" ;
VAL_TABLE_ TEGP_TrnsEngdStAuth 0 "Transmission Not Engaged" 1 "Transmission Engaged in Forward" 2 "Transmission Engaged in Reverse" 3 "Operating State Not Reached" ;
VAL_TABLE_ TEGP_TrnsEstGrAuth_Inv 0 "FALSE" 1 "TRUE" ;
VAL_TABLE_ TEGP_TrnsShftLvrPstnAuth_Inv 0 "FALSE" 1 "TRUE" ;
VAL_TABLE_ VMI1P_AccelPedOvrrdActvAuth 0 "FALSE" 1 "TRUE" ;
VAL_TABLE_ VMI1P_VehTopSpdLimModeActvAuth 0 "FALSE" 1 "TRUE" ;
VAL_TABLE_ VMI1P_AccelActlPstnAuth_Inv 0 "FALSE" 1 "TRUE" ;
VAL_TABLE_ VSADP_VehSpdAvgDrvnAuth_Inv 0 "FALSE" 1 "TRUE" ;
VAL_TABLE_ VSADP_FuelModeStsAuth 0 "Unknown" 1 "Gasoline Mode" 2 "Natural Gas Mode" 3 "Liquified Petroleum Gas Mode" 4 "Alternative Fuel Cut-off Active" ;
VAL_TABLE_ VSADP_RdcdPwrIndOnAuth 0 "FALSE" 1 "TRUE" ;
VAL_TABLE_ VSADP_VehSpdAvgDrvnSrcAuth 0 "Transmission Output Speed" 1 "Wheel Speed" ;

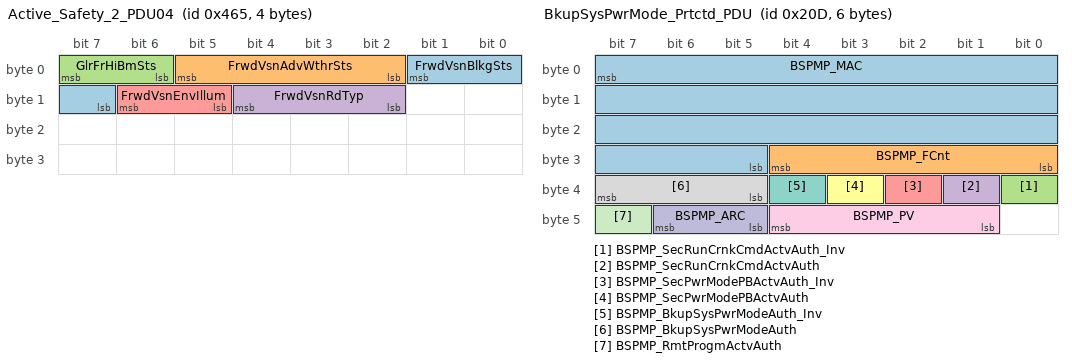
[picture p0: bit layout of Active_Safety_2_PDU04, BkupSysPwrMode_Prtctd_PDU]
BO_ 1125 Active_Safety_2_PDU04: 4 FCM_LC
 SG_ FrwdVsnBlkgSts : 1|3@0+ (1,0) [0|7] "" CGM
 SG_ FrwdVsnAdvWthrSts : 5|4@0+ (1,0) [0|9] "" CGM
 SG_ GlrFrHiBmSts : 7|2@0+ (1,0) [0|2] "" CGM
 SG_ FrwdVsnRdTyp : 12|3@0+ (1,0) [0|7] "" CGM
 SG_ FrwdVsnEnvIllum : 14|2@0+ (1,0) [0|3] "" CGM

BO_ 1127 Active_Safety_2_PDU05: 4 FCM_LC
 SG_ AutoHgBmActReq : 7|1@0+ (1,0) [0|1] "" CGM

BO_ 1130 Active_Safety_2_PDU06: 4 FCM_LC
 SG_ TLAHSR_HptcStRqstPls : 5|6@0+ (1,0) [0|63] "pulses" CGM
 SG_ TLAHSR_HptcStRqstSeqNmb : 7|2@0+ (1,0) [0|3] "counts" CGM

BO_ 131 AdpLgtObjInfo_PDU01: 64 FCM_LC
 SG_ ALOI1_PV : 7|136@0+ (1,0) [0|1.3938e+042] "" Vector__XXX
 SG_ ALOI1_RngTk1 : 139|16@0+ (0.02,0) [0|1310.7] "m" Vector__XXX
 SG_ ALOI1_RngTk2 : 155|16@0+ (0.02,0) [0|1310.7] "m" Vector__XXX
 SG_ ALOI1_RngTk3 : 171|16@0+ (0.02,0) [0|1310.7] "m" Vector__XXX
 SG_ ALOI1_RngTk4 : 187|16@0+ (0.02,0) [0|1310.7] "m" Vector__XXX
 SG_ ALOI1_AcqTmStm : 203|11@0+ (1,0) [0|2047] "ms" Vector__XXX
 SG_ ALOI1_AzmRateTk1 : 208|11@0+ (0.125,-128) [-128|127.875] "deg/s" Vector__XXX
 SG_ ALOI1_AzmRateTk2 : 229|11@0+ (0.125,-128) [-128|127.875] "deg/s" Vector__XXX
 SG_ ALOI1_AzmRateTk3 : 234|11@0+ (0.125,-128) [-128|127.875] "deg/s" Vector__XXX
 SG_ ALOI1_AzmRateTk4 : 255|11@0+ (0.125,-128) [-128|127.875] "deg/s" Vector__XXX
 SG_ ALOI1_AzmTk1 : 260|11@0+ (0.05,-51.2) [-51.2|51.15] "deg" Vector__XXX
 SG_ ALOI1_AzmTk2 : 265|11@0+ (0.05,-51.2) [-51.2|51.15] "deg" Vector__XXX
 SG_ ALOI1_AzmTk3 : 286|11@0+ (0.05,-51.2) [-51.2|51.15] "deg" Vector__XXX
 SG_ ALOI1_AzmTk4 : 291|11@0+ (0.05,-51.2) [-51.2|51.15] "deg" Vector__XXX
 SG_ ALOI1_WdthTk1 : 296|11@0+ (0.1,0) [0|204.7] "deg" Vector__XXX
 SG_ ALOI1_WdthTk2 : 317|11@0+ (0.1,0) [0|204.7] "deg" Vector__XXX
 SG_ ALOI1_WdthTk3 : 322|11@0+ (0.1,0) [0|204.7] "deg" Vector__XXX
 SG_ ALOI1_WdthTk4 : 343|11@0+ (0.1,0) [0|204.7] "deg" Vector__XXX
 SG_ ALOI1_RdSigGlrngTk1 : 348|7@0+ (1,0) [0|127] "%" Vector__XXX
 SG_ ALOI1_RdSigGlrngTk2 : 357|7@0+ (1,0) [0|127] "%" Vector__XXX
 SG_ ALOI1_RdSigGlrngTk3 : 366|7@0+ (1,0) [0|127] "%" Vector__XXX
 SG_ ALOI1_IDTk1 : 368|6@0+ (1,0) [0|63] "" Vector__XXX
 SG_ ALOI1_RdSigGlrngTk4 : 375|7@0+ (1,0) [0|127] "%" Vector__XXX
 SG_ ALOI1_IDTk2 : 378|6@0+ (1,0) [0|63] "" Vector__XXX
 SG_ ALOI1_IDTk3 : 388|6@0+ (1,0) [0|63] "" Vector__XXX
 SG_ ALOI1_VertPstnTk1 : 392|6@0+ (0.25,-3) [-3|12.75] "deg" Vector__XXX
 SG_ ALOI1_IDTk4 : 398|6@0+ (1,0) [0|63] "" Vector__XXX
 SG_ ALOI1_VertPstnTk2 : 402|6@0+ (0.25,-3) [-3|12.75] "deg" Vector__XXX
 SG_ ALOI1_VertPstnTk3 : 412|6@0+ (0.25,-3) [-3|12.75] "deg" Vector__XXX
 SG_ ALOI1_TypTk1 : 416|4@0+ (1,0) [0|12] "" Vector__XXX
 SG_ ALOI1_VertPstnTk4 : 422|6@0+ (0.25,-3) [-3|12.75] "deg" Vector__XXX
 SG_ ALOI1_TypTk3 : 424|4@0+ (1,0) [0|12] "" Vector__XXX
 SG_ ALOI1_TypTk2 : 428|4@0+ (1,0) [0|12] "" Vector__XXX
 SG_ ALOI1_DirTk1 : 432|3@0+ (1,0) [0|4] "" Vector__XXX
 SG_ ALOI1_TypTk4 : 436|4@0+ (1,0) [0|12] "" Vector__XXX
 SG_ ALOI1_DirTk3 : 442|3@0+ (1,0) [0|4] "" Vector__XXX
 SG_ ALOI1_DirTk2 : 445|3@0+ (1,0) [0|4] "" Vector__XXX
 SG_ ALOI1_CnfdTk2 : 448|2@0+ (1,0) [0|3] "" Vector__XXX
 SG_ ALOI1_CnfdTk1 : 450|2@0+ (1,0) [0|3] "" Vector__XXX
 SG_ ALOI1_ARC : 452|2@0+ (1,0) [0|3] "" Vector__XXX
 SG_ ALOI1_DirTk4 : 455|3@0+ (1,0) [0|4] "" Vector__XXX
 SG_ ALOI1_MeasStsTk2 : 456|2@0+ (1,0) [0|3] "" Vector__XXX
 SG_ ALOI1_MeasStsTk1 : 458|2@0+ (1,0) [0|3] "" Vector__XXX
 SG_ ALOI1_CnfdTk4 : 460|2@0+ (1,0) [0|3] "" Vector__XXX
 SG_ ALOI1_CnfdTk3 : 462|2@0+ (1,0) [0|3] "" Vector__XXX
 SG_ ALOI1_RltvLnTk2 : 464|2@0+ (1,0) [0|3] "" Vector__XXX
 SG_ ALOI1_RltvLnTk1 : 466|2@0+ (1,0) [0|3] "" Vector__XXX
 SG_ ALOI1_MeasStsTk4 : 468|2@0+ (1,0) [0|3] "" Vector__XXX
 SG_ ALOI1_MeasStsTk3 : 470|2@0+ (1,0) [0|3] "" Vector__XXX
 SG_ ALOI1_RngTk2_Inv : 472|1@0+ (1,0) [0|1] "" Vector__XXX
 SG_ ALOI1_RngTk1_Inv : 473|1@0+ (1,0) [0|1] "" Vector__XXX
 SG_ ALOI1_AcqTmStm_Inv : 474|1@0+ (1,0) [0|1] "" Vector__XXX
 SG_ ALOI1_RltvLnTk4 : 476|2@0+ (1,0) [0|3] "" Vector__XXX
 SG_ ALOI1_RltvLnTk3 : 478|2@0+ (1,0) [0|3] "" Vector__XXX
 SG_ ALOI1_RngTk4_Inv : 486|1@0+ (1,0) [0|1] "" Vector__XXX
 SG_ ALOI1_RngTk3_Inv : 487|1@0+ (1,0) [0|1] "" Vector__XXX

BO_ 136 AdpLgtObjInfo_PDU02: 64 FCM_LC
 SG_ ALOI2_PV : 7|136@0+ (1,0) [0|1.3938e+042] "" Vector__XXX
 SG_ ALOI2_RngTk5 : 139|16@0+ (0.02,0) [0|1310.7] "m" Vector__XXX
 SG_ ALOI2_RngTk6 : 155|16@0+ (0.02,0) [0|1310.7] "m" Vector__XXX
 SG_ ALOI2_RngTk7 : 171|16@0+ (0.02,0) [0|1310.7] "m" Vector__XXX
 SG_ ALOI2_RngTk8 : 187|16@0+ (0.02,0) [0|1310.7] "m" Vector__XXX
 SG_ ALOI2_AcqTmStm : 203|11@0+ (1,0) [0|2047] "ms" Vector__XXX
 SG_ ALOI2_AzmRateTk5 : 208|11@0+ (0.125,-128) [-128|127.875] "deg/s" Vector__XXX
 SG_ ALOI2_AzmRateTk6 : 229|11@0+ (0.125,-128) [-128|127.875] "deg/s" Vector__XXX
 SG_ ALOI2_AzmRateTk7 : 234|11@0+ (0.125,-128) [-128|127.875] "deg/s" Vector__XXX
 SG_ ALOI2_AzmRateTk8 : 255|11@0+ (0.125,-128) [-128|127.875] "deg/s" Vector__XXX
 SG_ ALOI2_AzmTk5 : 260|11@0+ (0.05,-51.2) [-51.2|51.15] "deg" Vector__XXX
 SG_ ALOI2_AzmTk6 : 265|11@0+ (0.05,-51.2) [-51.2|51.15] "deg" Vector__XXX
 SG_ ALOI2_AzmTk7 : 286|11@0+ (0.05,-51.2) [-51.2|51.15] "deg" Vector__XXX
 SG_ ALOI2_AzmTk8 : 291|11@0+ (0.05,-51.2) [-51.2|51.15] "deg" Vector__XXX
 SG_ ALOI2_WdthTk5 : 296|11@0+ (0.1,0) [0|204.7] "deg" Vector__XXX
 SG_ ALOI2_WdthTk6 : 317|11@0+ (0.1,0) [0|204.7] "deg" Vector__XXX
 SG_ ALOI2_WdthTk7 : 322|11@0+ (0.1,0) [0|204.7] "deg" Vector__XXX
 SG_ ALOI2_WdthTk8 : 343|11@0+ (0.1,0) [0|204.7] "deg" Vector__XXX
 SG_ ALOI2_RdSigGlrngTk5 : 348|7@0+ (1,0) [0|127] "%" Vector__XXX
 SG_ ALOI2_RdSigGlrngTk6 : 357|7@0+ (1,0) [0|127] "%" Vector__XXX
 SG_ ALOI2_RdSigGlrngTk7 : 366|7@0+ (1,0) [0|127] "%" Vector__XXX
 SG_ ALOI2_IDTk5 : 368|6@0+ (1,0) [0|63] "" Vector__XXX
 SG_ ALOI2_RdSigGlrngTk8 : 375|7@0+ (1,0) [0|127] "%" Vector__XXX
 SG_ ALOI2_IDTk6 : 378|6@0+ (1,0) [0|63] "" Vector__XXX
 SG_ ALOI2_IDTk7 : 388|6@0+ (1,0) [0|63] "" Vector__XXX
 SG_ ALOI2_VertPstnTk5 : 392|6@0+ (0.25,-3) [-3|12.75] "deg" Vector__XXX
 SG_ ALOI2_IDTk8 : 398|6@0+ (1,0) [0|63] "" Vector__XXX
 SG_ ALOI2_VertPstnTk6 : 402|6@0+ (0.25,-3) [-3|12.75] "deg" Vector__XXX
 SG_ ALOI2_VertPstnTk7 : 412|6@0+ (0.25,-3) [-3|12.75] "deg" Vector__XXX
 SG_ ALOI2_TypTk5 : 416|4@0+ (1,0) [0|12] "" Vector__XXX
 SG_ ALOI2_VertPstnTk8 : 422|6@0+ (0.25,-3) [-3|12.75] "deg" Vector__XXX
 SG_ ALOI2_TypTk7 : 424|4@0+ (1,0) [0|12] "" Vector__XXX
 SG_ ALOI2_TypTk6 : 428|4@0+ (1,0) [0|12] "" Vector__XXX
 SG_ ALOI2_DirTk5 : 432|3@0+ (1,0) [0|4] "" Vector__XXX
 SG_ ALOI2_TypTk8 : 436|4@0+ (1,0) [0|12] "" Vector__XXX
 SG_ ALOI2_DirTk7 : 442|3@0+ (1,0) [0|4] "" Vector__XXX
 SG_ ALOI2_DirTk6 : 445|3@0+ (1,0) [0|4] "" Vector__XXX
 SG_ ALOI2_CnfdTk6 : 448|2@0+ (1,0) [0|3] "" Vector__XXX
 SG_ ALOI2_CnfdTk5 : 450|2@0+ (1,0) [0|3] "" Vector__XXX
 SG_ ALOI2_ARC : 452|2@0+ (1,0) [0|3] "" Vector__XXX
 SG_ ALOI2_DirTk8 : 455|3@0+ (1,0) [0|4] "" Vector__XXX
 SG_ ALOI2_MeasStsTk6 : 456|2@0+ (1,0) [0|3] "" Vector__XXX
 SG_ ALOI2_MeasStsTk5 : 458|2@0+ (1,0) [0|3] "" Vector__XXX
 SG_ ALOI2_CnfdTk8 : 460|2@0+ (1,0) [0|3] "" Vector__XXX
 SG_ ALOI2_CnfdTk7 : 462|2@0+ (1,0) [0|3] "" Vector__XXX
 SG_ ALOI2_RltvLnTk6 : 464|2@0+ (1,0) [0|3] "" Vector__XXX
 SG_ ALOI2_RltvLnTk5 : 466|2@0+ (1,0) [0|3] "" Vector__XXX
 SG_ ALOI2_MeasStsTk8 : 468|2@0+ (1,0) [0|3] "" Vector__XXX
 SG_ ALOI2_MeasStsTk7 : 470|2@0+ (1,0) [0|3] "" Vector__XXX
 SG_ ALOI2_RngTk6_Inv : 472|1@0+ (1,0) [0|1] "" Vector__XXX
 SG_ ALOI2_RngTk5_Inv : 473|1@0+ (1,0) [0|1] "" Vector__XXX
 SG_ ALOI2_AcqTmStm_Inv : 474|1@0+ (1,0) [0|1] "" Vector__XXX
 SG_ ALOI2_RltvLnTk8 : 476|2@0+ (1,0) [0|3] "" Vector__XXX
 SG_ ALOI2_RltvLnTk7 : 478|2@0+ (1,0) [0|3] "" Vector__XXX
 SG_ ALOI2_RngTk8_Inv : 486|1@0+ (1,0) [0|1] "" Vector__XXX
 SG_ ALOI2_RngTk7_Inv : 487|1@0+ (1,0) [0|1] "" Vector__XXX

BO_ 41 AugRltyDatGrp_PDU01: 64 FCM_LC
 SG_ ARDG1_FrmTmStm1 : 5|32@0+ (1,0) [0|4.29497e+009] "msec" Vector__XXX
 SG_ ARDG1_ARC : 7|2@0+ (1,0) [0|3] "" Vector__XXX
 SG_ ARDG1_HstLnLtCrv : 37|16@0- (9.77e-07,0) [-0.0320143|0.0320134] "1/m" Vector__XXX
 SG_ ARDG1_HstLnLtCrvDrvt : 53|16@0- (3.73e-09,0) [-0.000122225|0.000122221] "1/m^2" Vector__XXX
 SG_ ARDG1_HstLnLtHdg : 69|10@0- (0.000977,0) [-0.500224|0.499247] "rad" Vector__XXX
 SG_ ARDG1_HstLnLtOfst : 75|13@0- (0.003906,0) [-15.999|15.9951] "m" Vector__XXX
 SG_ ARDG1_HstLnLtVwRngLngDist : 89|7@0+ (1,0) [0|127] "m" Vector__XXX
 SG_ ARDG1_HstLnLtTyp : 92|3@0+ (1,0) [0|7] "" Vector__XXX
 SG_ ARDG1_HstLnLtQlty : 94|2@0+ (1,0) [0|3] "" Vector__XXX
 SG_ ARDG1_HstLnLtVwStrtLngDist : 98|7@0+ (1,0) [0|127] "m" Vector__XXX
 SG_ ARDG1_HstLnLtWdth : 107|6@0+ (0.01,0) [0|0.63] "m" Vector__XXX
 SG_ ARDG1_HstNxtLnLtCrv : 117|16@0- (9.77e-07,0) [-0.0320143|0.0320134] "1/m" Vector__XXX
 SG_ ARDG1_HstNxtLnLtCrvDrvt : 133|16@0- (3.73e-09,0) [-0.000122225|0.000122221] "1/m^2" Vector__XXX
 SG_ ARDG1_HstNxtLnLtHdg : 149|10@0- (0.000977,0) [-0.500224|0.499247] "rad" Vector__XXX
 SG_ ARDG1_HstNxtLnLtOfst : 155|13@0- (0.003906,0) [-15.999|15.9951] "m" Vector__XXX
 SG_ ARDG1_HstNxtLnLtVwRngLngDist : 169|7@0+ (1,0) [0|127] "m" Vector__XXX
 SG_ ARDG1_HstNxtLnLtTyp : 172|3@0+ (1,0) [0|7] "" Vector__XXX
 SG_ ARDG1_HstNxtLnLtQlty : 174|2@0+ (1,0) [0|3] "" Vector__XXX
 SG_ ARDG1_HstNxtLnLtVwStrtLngDist : 178|7@0+ (1,0) [0|127] "m" Vector__XXX
 SG_ ARDG1_HstNxtLnLtWdth : 187|6@0+ (0.01,0) [0|0.63] "m" Vector__XXX
 SG_ ARDG1_LtVehAhdPoILatAccel : 195|9@0- (0.125,0) [-32|31.875] "m/s^2" Vector__XXX
 SG_ ARDG1_LtVehAhdMeasSts : 197|2@0+ (1,0) [0|3] "" Vector__XXX
 SG_ ARDG1_LtVehAhdPoILatPstn : 202|10@0- (0.125,0) [-64|63.875] "m" Vector__XXX
 SG_ ARDG1_LtVehAhdPoILatVel : 208|9@0- (0.125,0) [-32|31.875] "m/s" Vector__XXX
 SG_ ARDG1_LtVehAhdPoILngAccel : 231|9@0- (0.125,0) [-32|31.875] "m/s^2" Vector__XXX
 SG_ ARDG1_LtVehAhdPoILngPstn : 238|11@0+ (0.125,0) [0|255.875] "m" Vector__XXX
 SG_ ARDG1_LtVehAhdPoILngVel : 243|11@0- (0.125,0) [-128|127.875] "m/s" Vector__XXX
 SG_ ARDG1_LtVehAhdPoIWdth : 248|7@0+ (0.125,0) [0|15.875] "m" Vector__XXX
 SG_ ARDG2_ARC : 257|2@0+ (1,0) [0|3] "" Vector__XXX
 SG_ ARDG2_AutfxOutOfCal : 264|2@0+ (1,0) [0|3] "" Vector__XXX
 SG_ ARDG2_AutfxHrzn : 271|7@0- (1,0) [-64|63] "pixel" Vector__XXX
 SG_ ARDG2_AutfxYaw : 278|7@0- (1,0) [-64|63] "pixel" Vector__XXX
 SG_ ARDG2_FrmTmStm2 : 287|32@0+ (1,0) [0|4.29497e+009] "msec" Vector__XXX
 SG_ ARDG2_FrwdCamAlgnLivePtch : 312|12@0- (0.0001,0) [-0.2048|0.2047] "radians" Vector__XXX
 SG_ ARDG2_FrwdCamAlgnHrzn : 319|7@0+ (1,-40) [-40|87] "pixel" Vector__XXX
 SG_ ARDG2_FrwdCamAlgnRoll : 332|7@0- (0.001,0) [-0.064|0.063] "radians" Vector__XXX
 SG_ ARDG2_FrwdCamAlgnYaw : 341|7@0- (1,0) [-64|63] "pixel" Vector__XXX
 SG_ ARDG2_FrwdVsnTmStm : 347|32@0+ (1,0) [0|4.29497e+009] "ms" Vector__XXX
 SG_ ARDG2_FrwdCamSysOprtgSts : 350|3@0+ (1,0) [0|7] "" Vector__XXX
 SG_ ARDG2_HstVehAhdMeasSts : 377|2@0+ (1,0) [0|3] "" Vector__XXX
 SG_ ARDG2_FrwdVsnUnv : 378|1@0+ (1,0) [0|1] "" Vector__XXX
 SG_ ARDG2_FrwdVsnTmStm_Inv : 379|1@0+ (1,0) [0|1] "" Vector__XXX
 SG_ ARDG2_HstVehAhdPoILatAccel : 391|9@0- (0.125,0) [-32|31.875] "m/s^2" Vector__XXX
 SG_ ARDG2_HstVehAhdPoILatPstn : 398|10@0- (0.125,0) [-64|63.875] "m" Vector__XXX
 SG_ ARDG2_HstVehAhdPoILatVel : 404|9@0- (0.125,0) [-32|31.875] "m/s" Vector__XXX
 SG_ ARDG2_HstVehAhdPoILngAccel : 411|9@0- (0.125,0) [-32|31.875] "m/s^2" Vector__XXX
 SG_ ARDG2_HstVehAhdPoILngPstn : 418|11@0+ (0.125,0) [0|255.875] "m" Vector__XXX
 SG_ ARDG2_HstVehAhdPoILngVel : 439|11@0- (0.125,0) [-128|127.875] "m/s" Vector__XXX
 SG_ ARDG2_HstVehAhdPoIWdth : 444|7@0+ (0.125,0) [0|15.875] "m" Vector__XXX

BO_ 42 AugRltyDatGrp_PDU02: 48 FCM_LC
 SG_ ARDG3_FrmTmStm3 : 5|32@0+ (1,0) [0|4.29497e+009] "msec" Vector__XXX
 SG_ ARDG3_ARC : 7|2@0+ (1,0) [0|3] "" Vector__XXX
 SG_ ARDG3_HstLnRtCrv : 37|16@0- (9.77e-07,0) [-0.0320143|0.0320134] "1/m" Vector__XXX
 SG_ ARDG3_HstLnRtCrvDrvt : 53|16@0- (3.73e-09,0) [-0.000122225|0.000122221] "1/m^2" Vector__XXX
 SG_ ARDG3_HstLnRtHdg : 69|10@0- (0.000977,0) [-0.500224|0.499247] "rad" Vector__XXX
 SG_ ARDG3_HstLnRtOfst : 75|13@0- (0.003906,0) [-15.999|15.9951] "m" Vector__XXX
 SG_ ARDG3_HstLnRtVwRngLngDist : 89|7@0+ (1,0) [0|127] "m" Vector__XXX
 SG_ ARDG3_HstLnRtTyp : 92|3@0+ (1,0) [0|7] "" Vector__XXX
 SG_ ARDG3_HstLnRtQlty : 94|2@0+ (1,0) [0|3] "" Vector__XXX
 SG_ ARDG3_HstLnRtVwStrtLngDist : 98|7@0+ (1,0) [0|127] "m" Vector__XXX
 SG_ ARDG3_HstLnRtWdth : 107|6@0+ (0.01,0) [0|0.63] "m" Vector__XXX
 SG_ ARDG3_HstNxtLnRtCrv : 117|16@0- (9.77e-07,0) [-0.0320143|0.0320134] "1/m" Vector__XXX
 SG_ ARDG3_HstNxtLnRtCrvDrvt : 133|16@0- (3.73e-09,0) [-0.000122225|0.000122221] "1/m^2" Vector__XXX
 SG_ ARDG3_HstNxtLnRtHdg : 149|10@0- (0.000977,0) [-0.500224|0.499247] "rad" Vector__XXX
 SG_ ARDG3_HstNxtLnRtOfst : 155|13@0- (0.003906,0) [-15.999|15.9951] "m" Vector__XXX
 SG_ ARDG3_HstNxtLnRtVwRngLngDist : 169|7@0+ (1,0) [0|127] "m" Vector__XXX
 SG_ ARDG3_HstNxtLnRtTyp : 172|3@0+ (1,0) [0|7] "" Vector__XXX
 SG_ ARDG3_HstNxtLnRtQlty : 174|2@0+ (1,0) [0|3] "" Vector__XXX
 SG_ ARDG3_HstNxtLnRtVwStrtLngDist : 178|7@0+ (1,0) [0|127] "m" Vector__XXX
 SG_ ARDG3_HstNxtLnRtWdth : 187|6@0+ (0.01,0) [0|0.63] "m" Vector__XXX
 SG_ ARDG3_RtVehAhdPoILatAccel : 195|9@0- (0.125,0) [-32|31.875] "m/s^2" Vector__XXX
 SG_ ARDG3_RtVehAhdMeasSts : 197|2@0+ (1,0) [0|3] "" Vector__XXX
 SG_ ARDG3_RtVehAhdPoILatPstn : 202|10@0- (0.125,0) [-64|63.875] "m" Vector__XXX
 SG_ ARDG3_RtVehAhdPoILatVel : 208|9@0- (0.125,0) [-32|31.875] "m/s" Vector__XXX
 SG_ ARDG3_RtVehAhdPoILngAccel : 231|9@0- (0.125,0) [-32|31.875] "m/s^2" Vector__XXX
 SG_ ARDG3_RtVehAhdPoILngPstn : 238|11@0+ (0.125,0) [0|255.875] "m" Vector__XXX
 SG_ ARDG3_RtVehAhdPoILngVel : 243|11@0- (0.125,0) [-128|127.875] "m/s" Vector__XXX
 SG_ ARDG3_RtVehAhdPoIWdth : 248|7@0+ (0.125,0) [0|15.875] "m" Vector__XXX

BO_ 526 BkupSysPwrMode_PCSM_PDU: 8 CGM
 SG_ BkupSysPwrMode_PCSM : 0|64@1+ (1,0) [0|1.84467e+019] "" EOCM_HCP2,FCM_LC,HDLM,LRR,LRR_HC,SRR_LF,SRR_LR_CR,SRR_RF,SRR_RR,SRR_SLR,SRR_SRR

BO_ 525 BkupSysPwrMode_Prtctd_PDU: 6 CGM
 SG_ BSPMP_MAC : 7|27@0+ (1,0) [0|1.34218e+008] "" EOCM_HCP2,FCM_LC,HDLM,LRR,LRR_HC,SRR_LF,SRR_LR_CR,SRR_RF,SRR_RR,SRR_SLR,SRR_SRR
 SG_ BSPMP_FCnt : 28|5@0+ (1,0) [0|31] "" EOCM_HCP2,FCM_LC,HDLM,LRR,LRR_HC,SRR_LF,SRR_LR_CR,SRR_RF,SRR_RR,SRR_SLR,SRR_SRR
 SG_ BSPMP_SecRunCrnkCmdActvAuth_Inv : 32|1@0+ (1,0) [0|1] "" EOCM_HCP2,FCM_LC,HDLM,LRR,LRR_HC,SRR_LF,SRR_LR_CR,SRR_RF,SRR_RR,SRR_SLR,SRR_SRR
 SG_ BSPMP_SecRunCrnkCmdActvAuth : 33|1@0+ (1,0) [0|1] "" EOCM_HCP2,FCM_LC,HDLM,LRR,LRR_HC,SRR_LF,SRR_LR_CR,SRR_RF,SRR_RR,SRR_SLR,SRR_SRR
 SG_ BSPMP_SecPwrModePBActvAuth_Inv : 34|1@0+ (1,0) [0|1] "" EOCM_HCP2,FCM_LC,HDLM,LRR,LRR_HC,SRR_LF,SRR_LR_CR,SRR_RF,SRR_RR,SRR_SLR,SRR_SRR
 SG_ BSPMP_SecPwrModePBActvAuth : 35|1@0+ (1,0) [0|1] "" EOCM_HCP2,FCM_LC,HDLM,LRR,LRR_HC,SRR_LF,SRR_LR_CR,SRR_RF,SRR_RR,SRR_SLR,SRR_SRR
 SG_ BSPMP_BkupSysPwrModeAuth_Inv : 36|1@0+ (1,0) [0|1] "" EOCM_HCP2,FCM_LC,HDLM,LRR,LRR_HC,SRR_LF,SRR_LR_CR,SRR_RF,SRR_RR,SRR_SLR,SRR_SRR
 SG_ BSPMP_BkupSysPwrModeAuth : 39|3@0+ (1,0) [0|4] "" EOCM_HCP2,FCM_LC,HDLM,LRR,LRR_HC,SRR_LF,SRR_LR_CR,SRR_RF,SRR_RR,SRR_SLR,SRR_SRR
 SG_ BSPMP_PV : 44|4@0+ (1,0) [0|15] "" EOCM_HCP2,FCM_LC,HDLM,LRR,LRR_HC,SRR_LF,SRR_LR_CR,SRR_RF,SRR_RR,SRR_SLR,SRR_SRR
 SG_ BSPMP_ARC : 46|2@0+ (1,0) [0|3] "" EOCM_HCP2,FCM_LC,HDLM,LRR,LRR_HC,SRR_LF,SRR_LR_CR,SRR_RF,SRR_RR,SRR_SLR,SRR_SRR
 SG_ BSPMP_RmtProgmActvAuth : 47|1@0+ (1,0) [0|1] "" EOCM_HCP2,FCM_LC,HDLM,LRR,LRR_HC,SRR_LF,SRR_LR_CR,SRR_RF,SRR_RR,SRR_SLR,SRR_SRR

BO_ 227 C8_FCODP_Consecutive_Frame_Numbe: 64 FCM_LC
 SG_ FCODPB11P_FVVOTk10PoI4LgPsAuth : 5|11@0+ (0.125,0) [0|255.875] "m" EOCM,EOCM_HCP1,EOCM_HCP2,HDLM
 SG_ FCODPB11P_BrstID : 7|2@0+ (1,0) [0|3] "" EOCM,EOCM_HCP1,EOCM_HCP2,HDLM
 SG_ FCODPB11P_FVVOTk10PoI4LPsAuth : 10|10@0+ (0.125,-64) [-64|63.875] "m" EOCM,EOCM_HCP1,EOCM_HCP2,HDLM
 SG_ FCODPB11P_FVVOTk10PoI4PsVisAuth : 16|2@0+ (1,0) [0|2] "" EOCM,EOCM_HCP1,EOCM_HCP2,HDLM
 SG_ FCODPB11P_FVVOTk1PoI4LgPsAuth : 30|11@0+ (0.125,0) [0|255.875] "m" EOCM,EOCM_HCP1,EOCM_HCP2,HDLM
 SG_ FCODPB11P_FVVOTk1PoI4LPsAuth : 35|10@0+ (0.125,-64) [-64|63.875] "m" EOCM,EOCM_HCP1,EOCM_HCP2,HDLM
 SG_ FCODPB11P_FVVOTk1PoI4PsVisAuth : 41|2@0+ (1,0) [0|2] "" EOCM,EOCM_HCP1,EOCM_HCP2,HDLM
 SG_ FCODPB11P_FVVOTk2PoI4LgPsAuth : 55|11@0+ (0.125,0) [0|255.875] "m" EOCM,EOCM_HCP1,EOCM_HCP2,HDLM
 SG_ FCODPB11P_FVVOTk2PoI4LPsAuth : 60|10@0+ (0.125,-64) [-64|63.875] "m" EOCM,EOCM_HCP1,EOCM_HCP2,HDLM
 SG_ FCODPB11P_FVVOTk3PoI4LgPsAuth : 64|11@0+ (0.125,0) [0|255.875] "m" EOCM,EOCM_HCP1,EOCM_HCP2,HDLM
 SG_ FCODPB11P_FVVOTk2PoI4PsVisAuth : 66|2@0+ (1,0) [0|2] "" EOCM,EOCM_HCP1,EOCM_HCP2,HDLM
 SG_ FCODPB11P_FVVOTk3PoI4LPsAuth : 85|10@0+ (0.125,-64) [-64|63.875] "m" EOCM,EOCM_HCP1,EOCM_HCP2,HDLM
 SG_ FCODPB11P_FVVOTk4PoI4LgPsAuth : 89|11@0+ (0.125,0) [0|255.875] "m" EOCM,EOCM_HCP1,EOCM_HCP2,HDLM
 SG_ FCODPB11P_FVVOTk3PoI4PsVisAuth : 91|2@0+ (1,0) [0|2] "" EOCM,EOCM_HCP1,EOCM_HCP2,HDLM
 SG_ FCODPB11P_FVVOTk4PoI4LPsAuth : 110|10@0+ (0.125,-64) [-64|63.875] "m" EOCM,EOCM_HCP1,EOCM_HCP2,HDLM
 SG_ FCODPB11P_FVVOTk5PoI4LgPsAuth : 114|11@0+ (0.125,0) [0|255.875] "m" EOCM,EOCM_HCP1,EOCM_HCP2,HDLM
 SG_ FCODPB11P_FVVOTk4PoI4PsVisAuth : 116|2@0+ (1,0) [0|2] "" EOCM,EOCM_HCP1,EOCM_HCP2,HDLM
 SG_ FCODPB11P_FVVOTk5PoI4LPsAuth : 135|10@0+ (0.125,-64) [-64|63.875] "m" EOCM,EOCM_HCP1,EOCM_HCP2,HDLM
 SG_ FCODPB11P_FVVOTk6PoI4LgPsAuth : 139|11@0+ (0.125,0) [0|255.875] "m" EOCM,EOCM_HCP1,EOCM_HCP2,HDLM
 SG_ FCODPB11P_FVVOTk5PoI4PsVisAuth : 141|2@0+ (1,0) [0|2] "" EOCM,EOCM_HCP1,EOCM_HCP2,HDLM
 SG_ FCODPB11P_FVVOTk6PoI4LPsAuth : 144|10@0+ (0.125,-64) [-64|63.875] "m" EOCM,EOCM_HCP1,EOCM_HCP2,HDLM
 SG_ FCODPB11P_FVVOTk7PoI4LgPsAuth : 164|11@0+ (0.125,0) [0|255.875] "m" EOCM,EOCM_HCP1,EOCM_HCP2,HDLM
 SG_ FCODPB11P_FVVOTk6PoI4PsVisAuth : 166|2@0+ (1,0) [0|2] "" EOCM,EOCM_HCP1,EOCM_HCP2,HDLM
 SG_ FCODPB11P_FVVOTk7PoI4LPsAuth : 169|10@0+ (0.125,-64) [-64|63.875] "m" EOCM,EOCM_HCP1,EOCM_HCP2,HDLM
 SG_ FCODPB11P_FVVOTk8PoI4LgPsAuth : 189|11@0+ (0.125,0) [0|255.875] "m" EOCM,EOCM_HCP1,EOCM_HCP2,HDLM
 SG_ FCODPB11P_FVVOTk7PoI4PsVisAuth : 191|2@0+ (1,0) [0|2] "" EOCM,EOCM_HCP1,EOCM_HCP2,HDLM
 SG_ FCODPB11P_FVVOTk8PoI4LPsAuth : 194|10@0+ (0.125,-64) [-64|63.875] "m" EOCM,EOCM_HCP1,EOCM_HCP2,HDLM
 SG_ FCODPB11P_FVVOTk8PoI4PsVisAuth : 200|2@0+ (1,0) [0|2] "" EOCM,EOCM_HCP1,EOCM_HCP2,HDLM
 SG_ FCODPB11P_FVVOTk9PoI4LgPsAuth : 214|11@0+ (0.125,0) [0|255.875] "m" EOCM,EOCM_HCP1,EOCM_HCP2,HDLM
 SG_ FCODPB11P_FVVOTk9PoI4LPsAuth : 219|10@0+ (0.125,-64) [-64|63.875] "m" EOCM,EOCM_HCP1,EOCM_HCP2,HDLM
 SG_ FCODPB11P_FVVOTk9PoI4PsVisAuth : 225|2@0+ (1,0) [0|2] "" EOCM,EOCM_HCP1,EOCM_HCP2,HDLM
 SG_ FCODPB11P_LnTrPtEndLatDistAuth : 239|12@0- (0.01,0) [-20.48|20.47] "m" EOCM,EOCM_HCP1,EOCM_HCP2,HDLM
 SG_ FCODPB11P_LnTrPtEndLngDistAuth : 243|14@0+ (0.01,0) [0|163.83] "m" EOCM,EOCM_HCP1,EOCM_HCP2,HDLM
 SG_ FCODPB11P_LnTrPtStrtLatDistAuth : 259|12@0- (0.01,0) [-20.48|20.47] "m" EOCM,EOCM_HCP1,EOCM_HCP2,HDLM
 SG_ FCODPB11P_LnTrPtEndTypAuth : 261|2@0+ (1,0) [0|2] "" EOCM,EOCM_HCP1,EOCM_HCP2,HDLM
 SG_ FCODPB11P_LnTrPtStrtLngDistAuth : 279|14@0+ (0.01,0) [0|163.83] "m" EOCM,EOCM_HCP1,EOCM_HCP2,HDLM
 SG_ FCODPB11P_LnTrPtStrtTypAuth : 281|2@0+ (1,0) [0|2] "" EOCM,EOCM_HCP1,EOCM_HCP2,HDLM
 SG_ FCODPB11P_RdVertPP10LngDistAuth : 292|10@0+ (0.125,0) [0|127.875] "m" EOCM,EOCM_HCP1,EOCM_HCP2,HDLM
 SG_ FCODPB11P_FrwdVsnModeCmdStsAuth : 293|1@0+ (1,0) [0|1] "" EOCM,EOCM_HCP1,EOCM_HCP2,HDLM
 SG_ FCODPB11P_LnTrPtSyncIdxAuth : 295|2@0+ (1,0) [0|3] "" EOCM,EOCM_HCP1,EOCM_HCP2,HDLM
 SG_ FCODPB11P_RdVertPP11LngDistAuth : 298|10@0+ (0.125,0) [0|127.875] "m" EOCM,EOCM_HCP1,EOCM_HCP2,HDLM
 SG_ FCODPB11P_RdVertPP12LngDistAuth : 304|10@0+ (0.125,0) [0|127.875] "m" EOCM,EOCM_HCP1,EOCM_HCP2,HDLM
 SG_ FCODPB11P_RdVertPP13LngDistAuth : 326|10@0+ (0.125,0) [0|127.875] "m" EOCM,EOCM_HCP1,EOCM_HCP2,HDLM
 SG_ FCODPB11P_RdVertPP14LngDistAuth : 332|10@0+ (0.125,0) [0|127.875] "m" EOCM,EOCM_HCP1,EOCM_HCP2,HDLM
 SG_ FCODPB11P_RdVertPP15LngDistAuth : 338|10@0+ (0.125,0) [0|127.875] "m" EOCM,EOCM_HCP1,EOCM_HCP2,HDLM
 SG_ FCODPB11P_RdVertPP1LngDistAuth : 344|10@0+ (0.125,0) [0|127.875] "m" EOCM,EOCM_HCP1,EOCM_HCP2,HDLM
 SG_ FCODPB11P_RdVertPP2LngDistAuth : 366|10@0+ (0.125,0) [0|127.875] "m" EOCM,EOCM_HCP1,EOCM_HCP2,HDLM
 SG_ FCODPB11P_RdVertPP3LngDistAuth : 372|10@0+ (0.125,0) [0|127.875] "m" EOCM,EOCM_HCP1,EOCM_HCP2,HDLM
 SG_ FCODPB11P_RdVertPP4LngDistAuth : 378|10@0+ (0.125,0) [0|127.875] "m" EOCM,EOCM_HCP1,EOCM_HCP2,HDLM
 SG_ FCODPB11P_RdVertPP5LngDistAuth : 384|10@0+ (0.125,0) [0|127.875] "m" EOCM,EOCM_HCP1,EOCM_HCP2,HDLM
 SG_ FCODPB11P_RdVertPP6LngDistAuth : 406|10@0+ (0.125,0) [0|127.875] "m" EOCM,EOCM_HCP1,EOCM_HCP2,HDLM
 SG_ FCODPB11P_RdVertPP7LngDistAuth : 412|10@0+ (0.125,0) [0|127.875] "m" EOCM,EOCM_HCP1,EOCM_HCP2,HDLM
 SG_ FCODPB11P_RdVertPP8LngDistAuth : 418|10@0+ (0.125,0) [0|127.875] "m" EOCM,EOCM_HCP1,EOCM_HCP2,HDLM
 SG_ FCODPB11P_RdVertPP9LngDistAuth : 424|10@0+ (0.125,0) [0|127.875] "m" EOCM,EOCM_HCP1,EOCM_HCP2,HDLM
 SG_ FCODPB11P_ShldrDtnRtofVehAuth : 444|2@0+ (1,0) [0|3] "" EOCM,EOCM_HCP1,EOCM_HCP2,HDLM
 SG_ FCODPB11P_ShldrDtnLtofVehAuth : 446|2@0+ (1,0) [0|3] "" EOCM,EOCM_HCP1,EOCM_HCP2,HDLM

BO_ 236 C8_FCODP_Consecutive_Frame_Num01: 64 FCM_LC
 SG_ FCODPB12P_FVTS1AgeAuth : 5|8@0+ (1,0) [0|255] "Frames" EOCM,EOCM_HCP1,EOCM_HCP2,HDLM
 SG_ FCODPB12P_BrstID : 7|2@0+ (1,0) [0|3] "" EOCM,EOCM_HCP1,EOCM_HCP2,HDLM
 SG_ FCODPB12P_FVTS1PsdbyHstVehAuth : 8|1@0+ (1,0) [0|1] "" EOCM,EOCM_HCP1,EOCM_HCP2,HDLM
 SG_ FCODPB12P_FVTS1PhysTypAuth : 10|2@0+ (1,0) [0|2] "" EOCM,EOCM_HCP1,EOCM_HCP2,HDLM
 SG_ FCODPB12P_FVTS1MeasVldAuth : 11|1@0+ (1,0) [0|1] "" EOCM,EOCM_HCP1,EOCM_HCP2,HDLM
 SG_ FCODPB12P_FVTS1FiltTypAuth : 13|2@0+ (1,0) [0|3] "" EOCM,EOCM_HCP1,EOCM_HCP2,HDLM
 SG_ FCODPB12P_FVTS2AgeAuth : 22|8@0+ (1,0) [0|255] "Frames" EOCM,EOCM_HCP1,EOCM_HCP2,HDLM
 SG_ FCODPB12P_FVTS1ZnDtdAuth : 23|1@0+ (1,0) [0|1] "" EOCM,EOCM_HCP1,EOCM_HCP2,HDLM
 SG_ FCODPB12P_FVTS2ZnDtdAuth : 24|1@0+ (1,0) [0|1] "" EOCM,EOCM_HCP1,EOCM_HCP2,HDLM
 SG_ FCODPB12P_FVTS2PsdbyHstVehAuth : 25|1@0+ (1,0) [0|1] "" EOCM,EOCM_HCP1,EOCM_HCP2,HDLM
 SG_ FCODPB12P_FVTS2PhysTypAuth : 27|2@0+ (1,0) [0|2] "" EOCM,EOCM_HCP1,EOCM_HCP2,HDLM
 SG_ FCODPB12P_FVTS2MeasVldAuth : 28|1@0+ (1,0) [0|1] "" EOCM,EOCM_HCP1,EOCM_HCP2,HDLM
 SG_ FCODPB12P_FVTS2FiltTypAuth : 30|2@0+ (1,0) [0|3] "" EOCM,EOCM_HCP1,EOCM_HCP2,HDLM
 SG_ FCODPB12P_FVTS3AgeAuth : 39|8@0+ (1,0) [0|255] "Frames" EOCM,EOCM_HCP1,EOCM_HCP2,HDLM
 SG_ FCODPB12P_FVTS4AgeAuth : 40|8@0+ (1,0) [0|255] "Frames" EOCM,EOCM_HCP1,EOCM_HCP2,HDLM
 SG_ FCODPB12P_FVTS3ZnDtdAuth : 41|1@0+ (1,0) [0|1] "" EOCM,EOCM_HCP1,EOCM_HCP2,HDLM
 SG_ FCODPB12P_FVTS3PsdbyHstVehAuth : 42|1@0+ (1,0) [0|1] "" EOCM,EOCM_HCP1,EOCM_HCP2,HDLM
 SG_ FCODPB12P_FVTS3PhysTypAuth : 44|2@0+ (1,0) [0|2] "" EOCM,EOCM_HCP1,EOCM_HCP2,HDLM
 SG_ FCODPB12P_FVTS3MeasVldAuth : 45|1@0+ (1,0) [0|1] "" EOCM,EOCM_HCP1,EOCM_HCP2,HDLM
 SG_ FCODPB12P_FVTS3FiltTypAuth : 47|2@0+ (1,0) [0|3] "" EOCM,EOCM_HCP1,EOCM_HCP2,HDLM
 SG_ FCODPB12P_FVTS4FiltTypAuth : 48|2@0+ (1,0) [0|3] "" EOCM,EOCM_HCP1,EOCM_HCP2,HDLM
 SG_ FCODPB12P_FVTS5AgeAuth : 57|8@0+ (1,0) [0|255] "Frames" EOCM,EOCM_HCP1,EOCM_HCP2,HDLM
 SG_ FCODPB12P_FVTS4ZnDtdAuth : 58|1@0+ (1,0) [0|1] "" EOCM,EOCM_HCP1,EOCM_HCP2,HDLM
 SG_ FCODPB12P_FVTS4PsdbyHstVehAuth : 59|1@0+ (1,0) [0|1] "" EOCM,EOCM_HCP1,EOCM_HCP2,HDLM
 SG_ FCODPB12P_FVTS4PhysTypAuth : 61|2@0+ (1,0) [0|2] "" EOCM,EOCM_HCP1,EOCM_HCP2,HDLM
 SG_ FCODPB12P_FVTS4MeasVldAuth : 62|1@0+ (1,0) [0|1] "" EOCM,EOCM_HCP1,EOCM_HCP2,HDLM
 SG_ FCODPB12P_FVTS5FiltTypAuth : 65|2@0+ (1,0) [0|3] "" EOCM,EOCM_HCP1,EOCM_HCP2,HDLM
 SG_ FCODPB12P_FVTS6AgeAuth : 74|8@0+ (1,0) [0|255] "Frames" EOCM,EOCM_HCP1,EOCM_HCP2,HDLM
 SG_ FCODPB12P_FVTS5ZnDtdAuth : 75|1@0+ (1,0) [0|1] "" EOCM,EOCM_HCP1,EOCM_HCP2,HDLM
 SG_ FCODPB12P_FVTS5PsdbyHstVehAuth : 76|1@0+ (1,0) [0|1] "" EOCM,EOCM_HCP1,EOCM_HCP2,HDLM
 SG_ FCODPB12P_FVTS5PhysTypAuth : 78|2@0+ (1,0) [0|2] "" EOCM,EOCM_HCP1,EOCM_HCP2,HDLM
 SG_ FCODPB12P_FVTS5MeasVldAuth : 79|1@0+ (1,0) [0|1] "" EOCM,EOCM_HCP1,EOCM_HCP2,HDLM
 SG_ FCODPB12P_FVTS6MeasVldAuth : 80|1@0+ (1,0) [0|1] "" EOCM,EOCM_HCP1,EOCM_HCP2,HDLM
 SG_ FCODPB12P_FVTS6FiltTypAuth : 82|2@0+ (1,0) [0|3] "" EOCM,EOCM_HCP1,EOCM_HCP2,HDLM
 SG_ FCODPB12P_RdBnkCrv1CrvAuth : 89|16@0- (9.77e-07,0) [-0.0320143|0.0320134] "1/m" EOCM,EOCM_HCP1,EOCM_HCP2,HDLM
 SG_ FCODPB12P_RdBnkCrv1CnfdStsAuth : 91|2@0+ (1,0) [0|3] "" EOCM,EOCM_HCP1,EOCM_HCP2,HDLM
 SG_ FCODPB12P_FVTS6ZnDtdAuth : 92|1@0+ (1,0) [0|1] "" EOCM,EOCM_HCP1,EOCM_HCP2,HDLM
 SG_ FCODPB12P_FVTS6PsdbyHstVehAuth : 93|1@0+ (1,0) [0|1] "" EOCM,EOCM_HCP1,EOCM_HCP2,HDLM
 SG_ FCODPB12P_FVTS6PhysTypAuth : 95|2@0+ (1,0) [0|2] "" EOCM,EOCM_HCP1,EOCM_HCP2,HDLM
 SG_ FCODPB12P_RdBnkCrv1CrvDrvtAuth : 105|16@0- (3.73e-09,0) [-0.000122225|0.000122221] "1/m2" EOCM,EOCM_HCP1,EOCM_HCP2,HDLM
 SG_ FCODPB12P_RdBnkCrv1HdgAuth : 121|10@0- (0.000977,0) [-0.500224|0.499247] "rad" EOCM,EOCM_HCP1,EOCM_HCP2,HDLM
 SG_ FCODPB12P_RdBnkCrv1LatOfstAuth : 143|8@0- (0.125,0) [-16|15.875] "m" EOCM,EOCM_HCP1,EOCM_HCP2,HDLM
 SG_ FCODPB12P_RdBnkCrv1LngOfstAuth : 151|10@0+ (0.125,0) [0|127.875] "m" EOCM,EOCM_HCP1,EOCM_HCP2,HDLM
 SG_ FCODPB12P_RdBnkCrv1PsEndAuth : 157|8@0- (0.125,0) [-16|15.875] "m" EOCM,EOCM_HCP1,EOCM_HCP2,HDLM
 SG_ FCODPB12P_RdBnkCrv1PsStrtAuth : 165|8@0- (0.125,0) [-16|15.875] "m" EOCM,EOCM_HCP1,EOCM_HCP2,HDLM
 SG_ FCODPB12P_RdBnkCrv2CrvAuth : 171|16@0- (9.77e-07,0) [-0.0320143|0.0320134] "1/m" EOCM,EOCM_HCP1,EOCM_HCP2,HDLM
 SG_ FCODPB12P_RdBnkCrv2CnfdStsAuth : 173|2@0+ (1,0) [0|3] "" EOCM,EOCM_HCP1,EOCM_HCP2,HDLM
 SG_ FCODPB12P_RdBnkCrv2CrvDrvtAuth : 187|16@0- (3.73e-09,0) [-0.000122225|0.000122221] "1/m2" EOCM,EOCM_HCP1,EOCM_HCP2,HDLM
 SG_ FCODPB12P_RdBnkCrv2HdgAuth : 203|10@0- (0.000977,0) [-0.500224|0.499247] "rad" EOCM,EOCM_HCP1,EOCM_HCP2,HDLM
 SG_ FCODPB12P_RdBnkCrv2LatOfstAuth : 209|8@0- (0.125,0) [-16|15.875] "m" EOCM,EOCM_HCP1,EOCM_HCP2,HDLM
 SG_ FCODPB12P_RdBnkCrv2LngOfstAuth : 217|10@0+ (0.125,0) [0|127.875] "m" EOCM,EOCM_HCP1,EOCM_HCP2,HDLM
 SG_ FCODPB12P_RdBnkCrv2PsEndAuth : 239|8@0- (0.125,0) [-16|15.875] "m" EOCM,EOCM_HCP1,EOCM_HCP2,HDLM
 SG_ FCODPB12P_RdBnkCrv2PsStrtAuth : 247|8@0- (0.125,0) [-16|15.875] "m" EOCM,EOCM_HCP1,EOCM_HCP2,HDLM
 SG_ FCODPB12P_RdBnkCrv3CrvAuth : 253|16@0- (9.77e-07,0) [-0.0320143|0.0320134] "1/m" EOCM,EOCM_HCP1,EOCM_HCP2,HDLM
 SG_ FCODPB12P_RdBnkCrv3CnfdStsAuth : 255|2@0+ (1,0) [0|3] "" EOCM,EOCM_HCP1,EOCM_HCP2,HDLM
 SG_ FCODPB12P_RdBnkCrv3CrvDrvtAuth : 269|16@0- (3.73e-09,0) [-0.000122225|0.000122221] "1/m2" EOCM,EOCM_HCP1,EOCM_HCP2,HDLM
 SG_ FCODPB12P_RdBnkCrv3HdgAuth : 285|10@0- (0.000977,0) [-0.500224|0.499247] "rad" EOCM,EOCM_HCP1,EOCM_HCP2,HDLM
 SG_ FCODPB12P_RdBnkCrv3LatOfstAuth : 291|8@0- (0.125,0) [-16|15.875] "m" EOCM,EOCM_HCP1,EOCM_HCP2,HDLM
 SG_ FCODPB12P_RdBnkCrv3LngOfstAuth : 299|10@0+ (0.125,0) [0|127.875] "m" EOCM,EOCM_HCP1,EOCM_HCP2,HDLM
 SG_ FCODPB12P_RdBnkCrv3PsEndAuth : 305|8@0- (0.125,0) [-16|15.875] "m" EOCM,EOCM_HCP1,EOCM_HCP2,HDLM
 SG_ FCODPB12P_RdBnkCrv3PsStrtAuth : 313|8@0- (0.125,0) [-16|15.875] "m" EOCM,EOCM_HCP1,EOCM_HCP2,HDLM
 SG_ FCODPB12P_RdVertPP10ElvtnAuth : 321|10@0- (0.125,0) [-64|63.875] "m" EOCM,EOCM_HCP1,EOCM_HCP2,HDLM
 SG_ FCODPB12P_RdVertPP11ElvtnAuth : 343|10@0- (0.125,0) [-64|63.875] "m" EOCM,EOCM_HCP1,EOCM_HCP2,HDLM
 SG_ FCODPB12P_RdVertPP12ElvtnAuth : 349|10@0- (0.125,0) [-64|63.875] "m" EOCM,EOCM_HCP1,EOCM_HCP2,HDLM
 SG_ FCODPB12P_RdVertPP13ElvtnAuth : 355|10@0- (0.125,0) [-64|63.875] "m" EOCM,EOCM_HCP1,EOCM_HCP2,HDLM
 SG_ FCODPB12P_RdVertPP14ElvtnAuth : 361|10@0- (0.125,0) [-64|63.875] "m" EOCM,EOCM_HCP1,EOCM_HCP2,HDLM
 SG_ FCODPB12P_RdVertPP15ElvtnAuth : 383|10@0- (0.125,0) [-64|63.875] "m" EOCM,EOCM_HCP1,EOCM_HCP2,HDLM
 SG_ FCODPB12P_RdVertPP1ElvtnAuth : 389|10@0- (0.125,0) [-64|63.875] "m" EOCM,EOCM_HCP1,EOCM_HCP2,HDLM
 SG_ FCODPB12P_RdVertPP2ElvtnAuth : 395|10@0- (0.125,0) [-64|63.875] "m" EOCM,EOCM_HCP1,EOCM_HCP2,HDLM
 SG_ FCODPB12P_RdVertPP3ElvtnAuth : 401|10@0- (0.125,0) [-64|63.875] "m" EOCM,EOCM_HCP1,EOCM_HCP2,HDLM
 SG_ FCODPB12P_RdVertPP4ElvtnAuth : 423|10@0- (0.125,0) [-64|63.875] "m" EOCM,EOCM_HCP1,EOCM_HCP2,HDLM
 SG_ FCODPB12P_RdVertPP5ElvtnAuth : 429|10@0- (0.125,0) [-64|63.875] "m" EOCM,EOCM_HCP1,EOCM_HCP2,HDLM
 SG_ FCODPB12P_RdVertPP6ElvtnAuth : 435|10@0- (0.125,0) [-64|63.875] "m" EOCM,EOCM_HCP1,EOCM_HCP2,HDLM
 SG_ FCODPB12P_RdVertPP7ElvtnAuth : 441|10@0- (0.125,0) [-64|63.875] "m" EOCM,EOCM_HCP1,EOCM_HCP2,HDLM
 SG_ FCODPB12P_RdVertPP8ElvtnAuth : 463|10@0- (0.125,0) [-64|63.875] "m" EOCM,EOCM_HCP1,EOCM_HCP2,HDLM
 SG_ FCODPB12P_RdVertPP9ElvtnAuth : 469|10@0- (0.125,0) [-64|63.875] "m" EOCM,EOCM_HCP1,EOCM_HCP2,HDLM

BO_ 237 C8_FCODP_Consecutive_Frame_Num02: 64 FCM_LC
 SG_ FCODPB13P_FVTS10AgeAuth : 5|8@0+ (1,0) [0|255] "Frames" EOCM,EOCM_HCP1,EOCM_HCP2,HDLM
 SG_ FCODPB13P_BrstID : 7|2@0+ (1,0) [0|3] "" EOCM,EOCM_HCP1,EOCM_HCP2,HDLM
 SG_ FCODPB13P_FVTS10PsdbyHstVehAuth : 8|1@0+ (1,0) [0|1] "" EOCM,EOCM_HCP1,EOCM_HCP2,HDLM
 SG_ FCODPB13P_FVTS10PhysTypAuth : 10|2@0+ (1,0) [0|2] "" EOCM,EOCM_HCP1,EOCM_HCP2,HDLM
 SG_ FCODPB13P_FVTS10MeasVldAuth : 11|1@0+ (1,0) [0|1] "" EOCM,EOCM_HCP1,EOCM_HCP2,HDLM
 SG_ FCODPB13P_FVTS10FiltTypAuth : 13|2@0+ (1,0) [0|3] "" EOCM,EOCM_HCP1,EOCM_HCP2,HDLM
 SG_ FCODPB13P_FVTS7AgeAuth : 22|8@0+ (1,0) [0|255] "Frames" EOCM,EOCM_HCP1,EOCM_HCP2,HDLM
 SG_ FCODPB13P_FVTS10ZnDtdAuth : 23|1@0+ (1,0) [0|1] "" EOCM,EOCM_HCP1,EOCM_HCP2,HDLM
 SG_ FCODPB13P_FVTS7ZnDtdAuth : 24|1@0+ (1,0) [0|1] "" EOCM,EOCM_HCP1,EOCM_HCP2,HDLM
 SG_ FCODPB13P_FVTS7PsdbyHstVehAuth : 25|1@0+ (1,0) [0|1] "" EOCM,EOCM_HCP1,EOCM_HCP2,HDLM
 SG_ FCODPB13P_FVTS7PhysTypAuth : 27|2@0+ (1,0) [0|2] "" EOCM,EOCM_HCP1,EOCM_HCP2,HDLM
 SG_ FCODPB13P_FVTS7MeasVldAuth : 28|1@0+ (1,0) [0|1] "" EOCM,EOCM_HCP1,EOCM_HCP2,HDLM
 SG_ FCODPB13P_FVTS7FiltTypAuth : 30|2@0+ (1,0) [0|3] "" EOCM,EOCM_HCP1,EOCM_HCP2,HDLM
 SG_ FCODPB13P_FVTS8AgeAuth : 39|8@0+ (1,0) [0|255] "Frames" EOCM,EOCM_HCP1,EOCM_HCP2,HDLM
 SG_ FCODPB13P_FVTS9AgeAuth : 40|8@0+ (1,0) [0|255] "Frames" EOCM,EOCM_HCP1,EOCM_HCP2,HDLM
 SG_ FCODPB13P_FVTS8ZnDtdAuth : 41|1@0+ (1,0) [0|1] "" EOCM,EOCM_HCP1,EOCM_HCP2,HDLM
 SG_ FCODPB13P_FVTS8PsdbyHstVehAuth : 42|1@0+ (1,0) [0|1] "" EOCM,EOCM_HCP1,EOCM_HCP2,HDLM
 SG_ FCODPB13P_FVTS8PhysTypAuth : 44|2@0+ (1,0) [0|2] "" EOCM,EOCM_HCP1,EOCM_HCP2,HDLM
 SG_ FCODPB13P_FVTS8MeasVldAuth : 45|1@0+ (1,0) [0|1] "" EOCM,EOCM_HCP1,EOCM_HCP2,HDLM
 SG_ FCODPB13P_FVTS8FiltTypAuth : 47|2@0+ (1,0) [0|3] "" EOCM,EOCM_HCP1,EOCM_HCP2,HDLM
 SG_ FCODPB13P_FVTS9FiltTypAuth : 48|2@0+ (1,0) [0|3] "" EOCM,EOCM_HCP1,EOCM_HCP2,HDLM
 SG_ FCODPB13P_FVTSTk10CnfdStsAuth : 57|2@0+ (1,0) [0|3] "" EOCM,EOCM_HCP1,EOCM_HCP2,HDLM
 SG_ FCODPB13P_FVTS9ZnDtdAuth : 58|1@0+ (1,0) [0|1] "" EOCM,EOCM_HCP1,EOCM_HCP2,HDLM
 SG_ FCODPB13P_FVTS9PsdbyHstVehAuth : 59|1@0+ (1,0) [0|1] "" EOCM,EOCM_HCP1,EOCM_HCP2,HDLM
 SG_ FCODPB13P_FVTS9PhysTypAuth : 61|2@0+ (1,0) [0|2] "" EOCM,EOCM_HCP1,EOCM_HCP2,HDLM
 SG_ FCODPB13P_FVTS9MeasVldAuth : 62|1@0+ (1,0) [0|1] "" EOCM,EOCM_HCP1,EOCM_HCP2,HDLM
 SG_ FCODPB13P_FVTSTk10LatPsAuth : 65|9@0- (0.125,0) [-32|31.875] "m" EOCM,EOCM_HCP1,EOCM_HCP2,HDLM
 SG_ FCODPB13P_FVTSTk10IDAuth : 71|6@0+ (1,0) [0|63] "" EOCM,EOCM_HCP1,EOCM_HCP2,HDLM
 SG_ FCODPB13P_FVTSTk10LngPsAuth : 72|11@0- (0.125,0) [-128|127.875] "m" EOCM,EOCM_HCP1,EOCM_HCP2,HDLM
 SG_ FCODPB13P_FVTSTk10SupTypAuth : 91|6@0+ (1,0) [0|39] "" EOCM,EOCM_HCP1,EOCM_HCP2,HDLM
 SG_ FCODPB13P_FVTSTk10MeasStsAuth : 93|2@0+ (1,0) [0|3] "" EOCM,EOCM_HCP1,EOCM_HCP2,HDLM
 SG_ FCODPB13P_FVTSTk10TypAuth : 101|7@0+ (1,0) [0|75] "" EOCM,EOCM_HCP1,EOCM_HCP2,HDLM
 SG_ FCODPB13P_FVTSTk10VertPsAuth : 108|8@0+ (0.125,0) [0|31.875] "m" EOCM,EOCM_HCP1,EOCM_HCP2,HDLM
 SG_ FCODPB13P_FVTSTk10TypCnfdAuth : 110|2@0+ (1,0) [0|3] "" EOCM,EOCM_HCP1,EOCM_HCP2,HDLM
 SG_ FCODPB13P_FVTSTk1IDAuth : 114|6@0+ (1,0) [0|63] "" EOCM,EOCM_HCP1,EOCM_HCP2,HDLM
 SG_ FCODPB13P_FVTSTk1CnfdStsAuth : 116|2@0+ (1,0) [0|3] "" EOCM,EOCM_HCP1,EOCM_HCP2,HDLM
 SG_ FCODPB13P_FVTSTk1LatPsAuth : 124|9@0- (0.125,0) [-32|31.875] "m" EOCM,EOCM_HCP1,EOCM_HCP2,HDLM
 SG_ FCODPB13P_FVTSTk1LngPsAuth : 131|11@0- (0.125,0) [-128|127.875] "m" EOCM,EOCM_HCP1,EOCM_HCP2,HDLM
 SG_ FCODPB13P_FVTSTk1MeasStsAuth : 136|2@0+ (1,0) [0|3] "" EOCM,EOCM_HCP1,EOCM_HCP2,HDLM
 SG_ FCODPB13P_FVTSTk1TypAuth : 144|7@0+ (1,0) [0|75] "" EOCM,EOCM_HCP1,EOCM_HCP2,HDLM
 SG_ FCODPB13P_FVTSTk1SupTypAuth : 150|6@0+ (1,0) [0|39] "" EOCM,EOCM_HCP1,EOCM_HCP2,HDLM
 SG_ FCODPB13P_FVTSTk1TypCnfdAuth : 153|2@0+ (1,0) [0|3] "" EOCM,EOCM_HCP1,EOCM_HCP2,HDLM
 SG_ FCODPB13P_FVTSTk1VertPsAuth : 167|8@0+ (0.125,0) [0|31.875] "m" EOCM,EOCM_HCP1,EOCM_HCP2,HDLM
 SG_ FCODPB13P_FVTSTk2IDAuth : 173|6@0+ (1,0) [0|63] "" EOCM,EOCM_HCP1,EOCM_HCP2,HDLM
 SG_ FCODPB13P_FVTSTk2CnfdStsAuth : 175|2@0+ (1,0) [0|3] "" EOCM,EOCM_HCP1,EOCM_HCP2,HDLM
 SG_ FCODPB13P_FVTSTk2LatPsAuth : 183|9@0- (0.125,0) [-32|31.875] "m" EOCM,EOCM_HCP1,EOCM_HCP2,HDLM
 SG_ FCODPB13P_FVTSTk2LngPsAuth : 190|11@0- (0.125,0) [-128|127.875] "m" EOCM,EOCM_HCP1,EOCM_HCP2,HDLM
 SG_ FCODPB13P_FVTSTk2SupTypAuth : 193|6@0+ (1,0) [0|39] "" EOCM,EOCM_HCP1,EOCM_HCP2,HDLM
 SG_ FCODPB13P_FVTSTk2MeasStsAuth : 195|2@0+ (1,0) [0|3] "" EOCM,EOCM_HCP1,EOCM_HCP2,HDLM
 SG_ FCODPB13P_FVTSTk2TypAuth : 203|7@0+ (1,0) [0|75] "" EOCM,EOCM_HCP1,EOCM_HCP2,HDLM
 SG_ FCODPB13P_FVTSTk2VertPsAuth : 210|8@0+ (0.125,0) [0|31.875] "m" EOCM,EOCM_HCP1,EOCM_HCP2,HDLM
 SG_ FCODPB13P_FVTSTk2TypCnfdAuth : 212|2@0+ (1,0) [0|3] "" EOCM,EOCM_HCP1,EOCM_HCP2,HDLM
 SG_ FCODPB13P_FVTSTk3IDAuth : 216|6@0+ (1,0) [0|63] "" EOCM,EOCM_HCP1,EOCM_HCP2,HDLM
 SG_ FCODPB13P_FVTSTk3CnfdStsAuth : 218|2@0+ (1,0) [0|3] "" EOCM,EOCM_HCP1,EOCM_HCP2,HDLM
 SG_ FCODPB13P_FVTSTk3LatPsAuth : 226|9@0- (0.125,0) [-32|31.875] "m" EOCM,EOCM_HCP1,EOCM_HCP2,HDLM
 SG_ FCODPB13P_FVTSTk3LngPsAuth : 233|11@0- (0.125,0) [-128|127.875] "m" EOCM,EOCM_HCP1,EOCM_HCP2,HDLM
 SG_ FCODPB13P_FVTSTk3SupTypAuth : 252|6@0+ (1,0) [0|39] "" EOCM,EOCM_HCP1,EOCM_HCP2,HDLM
 SG_ FCODPB13P_FVTSTk3MeasStsAuth : 254|2@0+ (1,0) [0|3] "" EOCM,EOCM_HCP1,EOCM_HCP2,HDLM
 SG_ FCODPB13P_FVTSTk3TypAuth : 262|7@0+ (1,0) [0|75] "" EOCM,EOCM_HCP1,EOCM_HCP2,HDLM
 SG_ FCODPB13P_FVTSTk3VertPsAuth : 269|8@0+ (0.125,0) [0|31.875] "m" EOCM,EOCM_HCP1,EOCM_HCP2,HDLM
 SG_ FCODPB13P_FVTSTk3TypCnfdAuth : 271|2@0+ (1,0) [0|3] "" EOCM,EOCM_HCP1,EOCM_HCP2,HDLM
 SG_ FCODPB13P_FVTSTk4IDAuth : 275|6@0+ (1,0) [0|63] "" EOCM,EOCM_HCP1,EOCM_HCP2,HDLM
 SG_ FCODPB13P_FVTSTk4CnfdStsAuth : 277|2@0+ (1,0) [0|3] "" EOCM,EOCM_HCP1,EOCM_HCP2,HDLM
 SG_ FCODPB13P_FVTSTk4LatPsAuth : 285|9@0- (0.125,0) [-32|31.875] "m" EOCM,EOCM_HCP1,EOCM_HCP2,HDLM
 SG_ FCODPB13P_FVTSTk4LngPsAuth : 292|11@0- (0.125,0) [-128|127.875] "m" EOCM,EOCM_HCP1,EOCM_HCP2,HDLM
 SG_ FCODPB13P_FVTSTk4MeasStsAuth : 297|2@0+ (1,0) [0|3] "" EOCM,EOCM_HCP1,EOCM_HCP2,HDLM
 SG_ FCODPB13P_FVTSTk4TypAuth : 305|7@0+ (1,0) [0|75] "" EOCM,EOCM_HCP1,EOCM_HCP2,HDLM
 SG_ FCODPB13P_FVTSTk4SupTypAuth : 311|6@0+ (1,0) [0|39] "" EOCM,EOCM_HCP1,EOCM_HCP2,HDLM
 SG_ FCODPB13P_FVTSTk4VertPsAuth : 312|8@0+ (0.125,0) [0|31.875] "m" EOCM,EOCM_HCP1,EOCM_HCP2,HDLM
 SG_ FCODPB13P_FVTSTk4TypCnfdAuth : 314|2@0+ (1,0) [0|3] "" EOCM,EOCM_HCP1,EOCM_HCP2,HDLM
 SG_ FCODPB13P_FVTSTk5CnfdStsAuth : 320|2@0+ (1,0) [0|3] "" EOCM,EOCM_HCP1,EOCM_HCP2,HDLM
 SG_ FCODPB13P_FVTSTk5LatPsAuth : 328|9@0- (0.125,0) [-32|31.875] "m" EOCM,EOCM_HCP1,EOCM_HCP2,HDLM
 SG_ FCODPB13P_FVTSTk5IDAuth : 334|6@0+ (1,0) [0|63] "" EOCM,EOCM_HCP1,EOCM_HCP2,HDLM
 SG_ FCODPB13P_FVTSTk5LngPsAuth : 351|11@0- (0.125,0) [-128|127.875] "m" EOCM,EOCM_HCP1,EOCM_HCP2,HDLM
 SG_ FCODPB13P_FVTSTk5SupTypAuth : 354|6@0+ (1,0) [0|39] "" EOCM,EOCM_HCP1,EOCM_HCP2,HDLM
 SG_ FCODPB13P_FVTSTk5MeasStsAuth : 356|2@0+ (1,0) [0|3] "" EOCM,EOCM_HCP1,EOCM_HCP2,HDLM
 SG_ FCODPB13P_FVTSTk5TypAuth : 364|7@0+ (1,0) [0|75] "" EOCM,EOCM_HCP1,EOCM_HCP2,HDLM
 SG_ FCODPB13P_FVTSTk5VertPsAuth : 371|8@0+ (0.125,0) [0|31.875] "m" EOCM,EOCM_HCP1,EOCM_HCP2,HDLM
 SG_ FCODPB13P_FVTSTk5TypCnfdAuth : 373|2@0+ (1,0) [0|3] "" EOCM,EOCM_HCP1,EOCM_HCP2,HDLM
 SG_ FCODPB13P_FVTSTk6IDAuth : 377|6@0+ (1,0) [0|63] "" EOCM,EOCM_HCP1,EOCM_HCP2,HDLM
 SG_ FCODPB13P_FVTSTk6CnfdStsAuth : 379|2@0+ (1,0) [0|3] "" EOCM,EOCM_HCP1,EOCM_HCP2,HDLM
 SG_ FCODPB13P_FVTSTk6LatPsAuth : 387|9@0- (0.125,0) [-32|31.875] "m" EOCM,EOCM_HCP1,EOCM_HCP2,HDLM
 SG_ FCODPB13P_FVTSTk6LngPsAuth : 394|11@0- (0.125,0) [-128|127.875] "m" EOCM,EOCM_HCP1,EOCM_HCP2,HDLM
 SG_ FCODPB13P_FVTSTk6SupTypAuth : 413|6@0+ (1,0) [0|39] "" EOCM,EOCM_HCP1,EOCM_HCP2,HDLM
 SG_ FCODPB13P_FVTSTk6MeasStsAuth : 415|2@0+ (1,0) [0|3] "" EOCM,EOCM_HCP1,EOCM_HCP2,HDLM
 SG_ FCODPB13P_FVTSTk6TypCnfdAuth : 416|2@0+ (1,0) [0|3] "" EOCM,EOCM_HCP1,EOCM_HCP2,HDLM
 SG_ FCODPB13P_FVTSTk6TypAuth : 423|7@0+ (1,0) [0|75] "" EOCM,EOCM_HCP1,EOCM_HCP2,HDLM
 SG_ FCODPB13P_FVTSTk6VertPsAuth : 430|8@0+ (0.125,0) [0|31.875] "m" EOCM,EOCM_HCP1,EOCM_HCP2,HDLM
 SG_ FCODPB13P_FVTSTk7IDAuth : 436|6@0+ (1,0) [0|63] "" EOCM,EOCM_HCP1,EOCM_HCP2,HDLM
 SG_ FCODPB13P_FVTSTk7CnfdStsAuth : 438|2@0+ (1,0) [0|3] "" EOCM,EOCM_HCP1,EOCM_HCP2,HDLM
 SG_ FCODPB13P_FVTSTk7LatPsAuth : 446|9@0- (0.125,0) [-32|31.875] "m" EOCM,EOCM_HCP1,EOCM_HCP2,HDLM
 SG_ FCODPB13P_FVTSTk7LngPsAuth : 453|11@0- (0.125,0) [-128|127.875] "m" EOCM,EOCM_HCP1,EOCM_HCP2,HDLM
 SG_ FCODPB13P_FVTSTk7SupTypAuth : 456|6@0+ (1,0) [0|39] "" EOCM,EOCM_HCP1,EOCM_HCP2,HDLM
 SG_ FCODPB13P_FVTSTk7MeasStsAuth : 458|2@0+ (1,0) [0|3] "" EOCM,EOCM_HCP1,EOCM_HCP2,HDLM
 SG_ FCODPB13P_FVTSTk7TypAuth : 466|7@0+ (1,0) [0|75] "" EOCM,EOCM_HCP1,EOCM_HCP2,HDLM
 SG_ FCODPB13P_FVTSTk7VertPsAuth : 473|8@0+ (0.125,0) [0|31.875] "m" EOCM,EOCM_HCP1,EOCM_HCP2,HDLM
 SG_ FCODPB13P_FVTSTk7TypCnfdAuth : 475|2@0+ (1,0) [0|3] "" EOCM,EOCM_HCP1,EOCM_HCP2,HDLM

BA_DEF_ SG_  "SignalType" STRING ;
BA_DEF_ SG_  "SignalLongName" STRING ;
BA_DEF_ BO_  "GenMsgCycleTime" INT 0 10000;
BA_DEF_ BO_  "GenMsgSendType" ENUM "cyclicX","spontanX","cyclicIfActiveX","spontanWithDelay","cyclicAndSpontanX","cyclicAndSpontanWithDelay","spontanWithRepetition","cyclicIfActiveAndSpontanWD";
BA_DEF_ BO_  "VFrameFormat" ENUM  "StandardCAN","ExtendedCAN","reserved","reserved","reserved","reserved","reserved","reserved","reserved","reserved","reserved","reserved","reserved","reserved","StandardCAN_FD","ExtendedCAN_FD";
BA_DEF_DEF_  "SignalType" "";
BA_DEF_DEF_  "SignalLongName" "";
BA_DEF_DEF_  "GenMsgCycleTime" 0;
BA_DEF_DEF_  "GenMsgSendType" "cyclicX";
BA_DEF_DEF_  "VFrameFormat" "StandardCAN";
BA_ "GenMsgCycleTime" BO_ 1125 1000;
BA_ "VFrameFormat" BO_ 1125 14;
BA_ "GenMsgCycleTime" BO_ 1127 1000;
BA_ "VFrameFormat" BO_ 1127 14;
BA_ "GenMsgCycleTime" BO_ 1130 1000;
BA_ "VFrameFormat" BO_ 1130 14;
BA_ "GenMsgCycleTime" BO_ 131 40;
BA_ "VFrameFormat" BO_ 131 14;
BA_ "GenMsgCycleTime" BO_ 136 40;
BA_ "VFrameFormat" BO_ 136 14;
BA_ "VFrameFormat" BO_ 41 14;
BA_ "VFrameFormat" BO_ 42 14;
BA_ "VFrameFormat" BO_ 526 14;
BA_ "GenMsgCycleTime" BO_ 525 250;
BA_ "VFrameFormat" BO_ 525 14;
BA_ "VFrameFormat" BO_ 227 14;
BA_ "VFrameFormat" BO_ 236 14;
BA_ "VFrameFormat" BO_ 237 14;
BA_ "SignalType" SG_ 1125 FrwdVsnBlkgSts "ENM";
BA_ "SignalLongName" SG_ 1125 FrwdVsnBlkgSts "Forward Vision Blockage Status";
BA_ "SignalType" SG_ 1125 FrwdVsnAdvWthrSts "ENM";
BA_ "SignalLongName" SG_ 1125 FrwdVsnAdvWthrSts "Forward Vision Adverse Weather Status";
BA_ "SignalType" SG_ 1125 GlrFrHiBmSts "ENM";
BA_ "SignalLongName" SG_ 1125 GlrFrHiBmSts "Glare Free High Beam Status";
BA_ "SignalType" SG_ 1125 FrwdVsnRdTyp "ENM";
BA_ "SignalLongName" SG_ 1125 FrwdVsnRdTyp "Forward Vision Road Type";
BA_ "SignalType" SG_ 1125 FrwdVsnEnvIllum "ENM";
BA_ "SignalLongName" SG_ 1125 FrwdVsnEnvIllum "Forward Vision Environment Illumination";
BA_ "SignalType" SG_ 1127 AutoHgBmActReq "ENM";
BA_ "SignalLongName" SG_ 1127 AutoHgBmActReq "Auto High Beam Activation Request";
BA_ "SignalLongName" SG_ 1130 TLAHSR_HptcStRqstPls "Traffic Light Assist Haptic Seat Request : Traffic Light Assist Haptic Seat Request Pulses";
BA_ "SignalLongName" SG_ 1130 TLAHSR_HptcStRqstSeqNmb "Traffic Light Assist Haptic Seat Request : Traffic Light Assist Haptic Seat Request Sequence Number";
BA_ "SignalLongName" SG_ 131 ALOI1_PV "Adaptive Lighting Objects Information 1 : Protection Value";
BA_ "SignalLongName" SG_ 131 ALOI1_RngTk1 "Adaptive Lighting Objects Information 1 : Range Track 1";
BA_ "SignalLongName" SG_ 131 ALOI1_RngTk2 "Adaptive Lighting Objects Information 1 : Range Track 2";
BA_ "SignalLongName" SG_ 131 ALOI1_RngTk3 "Adaptive Lighting Objects Information 1 : Range Track 3";
BA_ "SignalLongName" SG_ 131 ALOI1_RngTk4 "Adaptive Lighting Objects Information 1 : Range Track 4";
BA_ "SignalLongName" SG_ 131 ALOI1_AcqTmStm "Adaptive Lighting Objects Information 1 : Acquisition Time Stamp";
BA_ "SignalLongName" SG_ 131 ALOI1_AzmRateTk1 "Adaptive Lighting Objects Information 1 : Azimuth Rate Track1";
BA_ "SignalLongName" SG_ 131 ALOI1_AzmRateTk2 "Adaptive Lighting Objects Information 1 : Azimuth Rate Track 2";
BA_ "SignalLongName" SG_ 131 ALOI1_AzmRateTk3 "Adaptive Lighting Objects Information 1 : Azimuth Rate Track 3";
BA_ "SignalLongName" SG_ 131 ALOI1_AzmRateTk4 "Adaptive Lighting Objects Information 1 : Azimuth Rate Track 4";
BA_ "SignalLongName" SG_ 131 ALOI1_AzmTk1 "Adaptive Lighting Objects Information 1 : Azimuth Track 1";
BA_ "SignalLongName" SG_ 131 ALOI1_AzmTk2 "Adaptive Lighting Objects Information 1 : Azimuth Track 2";
BA_ "SignalLongName" SG_ 131 ALOI1_AzmTk3 "Adaptive Lighting Objects Information 1 : Azimuth Track 3";
BA_ "SignalLongName" SG_ 131 ALOI1_AzmTk4 "Adaptive Lighting Objects Information 1 : Azimuth Track 4";
BA_ "SignalLongName" SG_ 131 ALOI1_WdthTk1 "Adaptive Lighting Objects Information 1 : Width Track 1";
BA_ "SignalLongName" SG_ 131 ALOI1_WdthTk2 "Adaptive Lighting Objects Information 1 : Width Track 2";
BA_ "SignalLongName" SG_ 131 ALOI1_WdthTk3 "Adaptive Lighting Objects Information 1 : Width Track 3";
BA_ "SignalLongName" SG_ 131 ALOI1_WdthTk4 "Adaptive Lighting Objects Information 1 : Width Track 4";
BA_ "SignalLongName" SG_ 131 ALOI1_RdSigGlrngTk1 "Adaptive Lighting Objects Information 1 : Road Signal Glaring Track 1";
BA_ "SignalLongName" SG_ 131 ALOI1_RdSigGlrngTk2 "Adaptive Lighting Objects Information 1 : Road Signal Glaring Track 2";
BA_ "SignalLongName" SG_ 131 ALOI1_RdSigGlrngTk3 "Adaptive Lighting Objects Information 1 : Road Signal Glaring Track 3";
BA_ "SignalLongName" SG_ 131 ALOI1_IDTk1 "Adaptive Lighting Objects Information 1 : ID Track 1";
BA_ "SignalLongName" SG_ 131 ALOI1_RdSigGlrngTk4 "Adaptive Lighting Objects Information 1 : Road Signal Glaring Track 4";
BA_ "SignalLongName" SG_ 131 ALOI1_IDTk2 "Adaptive Lighting Objects Information 1 : ID Track 2";
BA_ "SignalLongName" SG_ 131 ALOI1_IDTk3 "Adaptive Lighting Objects Information 1 : ID Track 3";
BA_ "SignalLongName" SG_ 131 ALOI1_VertPstnTk1 "Adaptive Lighting Objects Information 1 : Vertical Position Track 1";
BA_ "SignalLongName" SG_ 131 ALOI1_IDTk4 "Adaptive Lighting Objects Information 1 : ID Track 4";
BA_ "SignalLongName" SG_ 131 ALOI1_VertPstnTk2 "Adaptive Lighting Objects Information 1 : Vertical Position Track 2";
BA_ "SignalLongName" SG_ 131 ALOI1_VertPstnTk3 "Adaptive Lighting Objects Information 1 : Vertical Position Track 3";
BA_ "SignalType" SG_ 131 ALOI1_TypTk1 "ENM";
BA_ "SignalLongName" SG_ 131 ALOI1_TypTk1 "Adaptive Lighting Objects Information 1 : Type Track 1";
BA_ "SignalLongName" SG_ 131 ALOI1_VertPstnTk4 "Adaptive Lighting Objects Information 1 : Vertical Position Track 4";
BA_ "SignalType" SG_ 131 ALOI1_TypTk3 "ENM";
BA_ "SignalLongName" SG_ 131 ALOI1_TypTk3 "Adaptive Lighting Objects Information 1 : Type Track 3";
BA_ "SignalType" SG_ 131 ALOI1_TypTk2 "ENM";
BA_ "SignalLongName" SG_ 131 ALOI1_TypTk2 "Adaptive Lighting Objects Information 1 : Type Track 2";
BA_ "SignalType" SG_ 131 ALOI1_DirTk1 "ENM";
BA_ "SignalLongName" SG_ 131 ALOI1_DirTk1 "Adaptive Lighting Objects Information 1 : Direction Track 1";
BA_ "SignalType" SG_ 131 ALOI1_TypTk4 "ENM";
BA_ "SignalLongName" SG_ 131 ALOI1_TypTk4 "Adaptive Lighting Objects Information 1 : Type Track 4";
BA_ "SignalType" SG_ 131 ALOI1_DirTk3 "ENM";
BA_ "SignalLongName" SG_ 131 ALOI1_DirTk3 "Adaptive Lighting Objects Information 1 : Direction Track 3";
BA_ "SignalType" SG_ 131 ALOI1_DirTk2 "ENM";
BA_ "SignalLongName" SG_ 131 ALOI1_DirTk2 "Adaptive Lighting Objects Information 1 : Direction Track 2";
BA_ "SignalType" SG_ 131 ALOI1_CnfdTk2 "ENM";
BA_ "SignalLongName" SG_ 131 ALOI1_CnfdTk2 "Adaptive Lighting Objects Information 1 : Confidence Track 2";
BA_ "SignalType" SG_ 131 ALOI1_CnfdTk1 "ENM";
BA_ "SignalLongName" SG_ 131 ALOI1_CnfdTk1 "Adaptive Lighting Objects Information 1 : Confidence Track 1";
BA_ "SignalLongName" SG_ 131 ALOI1_ARC "Adaptive Lighting Objects Information 1 : Alive Rolling Count";
BA_ "SignalType" SG_ 131 ALOI1_DirTk4 "ENM";
BA_ "SignalLongName" SG_ 131 ALOI1_DirTk4 "Adaptive Lighting Objects Information 1 : Direction Track 4";
BA_ "SignalType" SG_ 131 ALOI1_MeasStsTk2 "ENM";
BA_ "SignalLongName" SG_ 131 ALOI1_MeasStsTk2 "Adaptive Lighting Objects Information 1 : Measurement Status Track 2";
BA_ "SignalType" SG_ 131 ALOI1_MeasStsTk1 "ENM";
BA_ "SignalLongName" SG_ 131 ALOI1_MeasStsTk1 "Adaptive Lighting Objects Information 1 : Measurement Status Track 1";
BA_ "SignalType" SG_ 131 ALOI1_CnfdTk4 "ENM";
BA_ "SignalLongName" SG_ 131 ALOI1_CnfdTk4 "Adaptive Lighting Objects Information 1 : Confidence Track 4";
BA_ "SignalType" SG_ 131 ALOI1_CnfdTk3 "ENM";
BA_ "SignalLongName" SG_ 131 ALOI1_CnfdTk3 "Adaptive Lighting Objects Information 1 : Confidence Track 3";
BA_ "SignalType" SG_ 131 ALOI1_RltvLnTk2 "ENM";
BA_ "SignalLongName" SG_ 131 ALOI1_RltvLnTk2 "Adaptive Lighting Objects Information 1 : Relative Lane Track 2";
BA_ "SignalType" SG_ 131 ALOI1_RltvLnTk1 "ENM";
BA_ "SignalLongName" SG_ 131 ALOI1_RltvLnTk1 "Adaptive Lighting Objects Information 1 : Relative Lane Track 1";
BA_ "SignalType" SG_ 131 ALOI1_MeasStsTk4 "ENM";
BA_ "SignalLongName" SG_ 131 ALOI1_MeasStsTk4 "Adaptive Lighting Objects Information 1 : Measurement Status Track 4";
BA_ "SignalType" SG_ 131 ALOI1_MeasStsTk3 "ENM";
BA_ "SignalLongName" SG_ 131 ALOI1_MeasStsTk3 "Adaptive Lighting Objects Information 1 : Measurement Status Track 3";
BA_ "SignalType" SG_ 131 ALOI1_RngTk2_Inv "ENM";
BA_ "SignalLongName" SG_ 131 ALOI1_RngTk2_Inv "Adaptive Lighting Objects Information 1 : Range Track 2 Invalid";
BA_ "SignalType" SG_ 131 ALOI1_RngTk1_Inv "ENM";
BA_ "SignalLongName" SG_ 131 ALOI1_RngTk1_Inv "Adaptive Lighting Objects Information 1 : Range Track 1 Invalid";
BA_ "SignalType" SG_ 131 ALOI1_AcqTmStm_Inv "ENM";
BA_ "SignalLongName" SG_ 131 ALOI1_AcqTmStm_Inv "Adaptive Lighting Objects Information 1 : Acquisition Time Stamp Invalid";
BA_ "SignalType" SG_ 131 ALOI1_RltvLnTk4 "ENM";
BA_ "SignalLongName" SG_ 131 ALOI1_RltvLnTk4 "Adaptive Lighting Objects Information 1 : Relative Lane Track 4";
BA_ "SignalType" SG_ 131 ALOI1_RltvLnTk3 "ENM";
BA_ "SignalLongName" SG_ 131 ALOI1_RltvLnTk3 "Adaptive Lighting Objects Information 1 : Relative Lane Track 3";
BA_ "SignalType" SG_ 131 ALOI1_RngTk4_Inv "ENM";
BA_ "SignalLongName" SG_ 131 ALOI1_RngTk4_Inv "Adaptive Lighting Objects Information 1 : Range Track 4 Invalid";
BA_ "SignalType" SG_ 131 ALOI1_RngTk3_Inv "ENM";
BA_ "SignalLongName" SG_ 131 ALOI1_RngTk3_Inv "Adaptive Lighting Objects Information 1 : Range Track 3 Invalid";
BA_ "SignalLongName" SG_ 136 ALOI2_PV "Adaptive Lighting Objects Information 2 : Protection Value";
BA_ "SignalLongName" SG_ 136 ALOI2_RngTk5 "Adaptive Lighting Objects Information 2 : Range Track 5";
BA_ "SignalLongName" SG_ 136 ALOI2_RngTk6 "Adaptive Lighting Objects Information 2 : Range Track 6";
BA_ "SignalLongName" SG_ 136 ALOI2_RngTk7 "Adaptive Lighting Objects Information 2 : Range Track 7";
BA_ "SignalLongName" SG_ 136 ALOI2_RngTk8 "Adaptive Lighting Objects Information 2 : Range Track 8";
BA_ "SignalLongName" SG_ 136 ALOI2_AcqTmStm "Adaptive Lighting Objects Information 2 : Acquisition Time Stamp";
BA_ "SignalLongName" SG_ 136 ALOI2_AzmRateTk5 "Adaptive Lighting Objects Information 2 : Azimuth Rate Track 5";
BA_ "SignalLongName" SG_ 136 ALOI2_AzmRateTk6 "Adaptive Lighting Objects Information 2 : Azimuth Rate Track 6";
BA_ "SignalLongName" SG_ 136 ALOI2_AzmRateTk7 "Adaptive Lighting Objects Information 2 : Azimuth Rate Track 7";
BA_ "SignalLongName" SG_ 136 ALOI2_AzmRateTk8 "Adaptive Lighting Objects Information 2 : Azimuth Rate Track 8";
BA_ "SignalLongName" SG_ 136 ALOI2_AzmTk5 "Adaptive Lighting Objects Information 2 : Azimuth Track 5";
BA_ "SignalLongName" SG_ 136 ALOI2_AzmTk6 "Adaptive Lighting Objects Information 2 : Azimuth Track 6";
BA_ "SignalLongName" SG_ 136 ALOI2_AzmTk7 "Adaptive Lighting Objects Information 2 : Azimuth Track 7";
BA_ "SignalLongName" SG_ 136 ALOI2_AzmTk8 "Adaptive Lighting Objects Information 2 : Azimuth Track 8";
BA_ "SignalLongName" SG_ 136 ALOI2_WdthTk5 "Adaptive Lighting Objects Information 2 : Width Track 5";
BA_ "SignalLongName" SG_ 136 ALOI2_WdthTk6 "Adaptive Lighting Objects Information 2 : Width Track 6";
BA_ "SignalLongName" SG_ 136 ALOI2_WdthTk7 "Adaptive Lighting Objects Information 2 : Width Track 7";
BA_ "SignalLongName" SG_ 136 ALOI2_WdthTk8 "Adaptive Lighting Objects Information 2 : Width Track 8";
BA_ "SignalLongName" SG_ 136 ALOI2_RdSigGlrngTk5 "Adaptive Lighting Objects Information 2 : Road Signal Glaring Track 5";
BA_ "SignalLongName" SG_ 136 ALOI2_RdSigGlrngTk6 "Adaptive Lighting Objects Information 2 : Road Signal Glaring Track 6";
BA_ "SignalLongName" SG_ 136 ALOI2_RdSigGlrngTk7 "Adaptive Lighting Objects Information 2 : Road Signal Glaring Track 7";
BA_ "SignalLongName" SG_ 136 ALOI2_IDTk5 "Adaptive Lighting Objects Information 2 : ID Track 5";
BA_ "SignalLongName" SG_ 136 ALOI2_RdSigGlrngTk8 "Adaptive Lighting Objects Information 2 : Road Signal Glaring Track 8";
BA_ "SignalLongName" SG_ 136 ALOI2_IDTk6 "Adaptive Lighting Objects Information 2 : ID Track 6";
BA_ "SignalLongName" SG_ 136 ALOI2_IDTk7 "Adaptive Lighting Objects Information 2 : ID Track 7";
BA_ "SignalLongName" SG_ 136 ALOI2_VertPstnTk5 "Adaptive Lighting Objects Information 2 : Vertical Position Track 5";
BA_ "SignalLongName" SG_ 136 ALOI2_IDTk8 "Adaptive Lighting Objects Information 2 : ID Track 8";
BA_ "SignalLongName" SG_ 136 ALOI2_VertPstnTk6 "Adaptive Lighting Objects Information 2 : Vertical Position Track 6";
BA_ "SignalLongName" SG_ 136 ALOI2_VertPstnTk7 "Adaptive Lighting Objects Information 2 : Vertical Position Track 7";
BA_ "SignalType" SG_ 136 ALOI2_TypTk5 "ENM";
BA_ "SignalLongName" SG_ 136 ALOI2_TypTk5 "Adaptive Lighting Objects Information 2 : Type Track 5";
BA_ "SignalLongName" SG_ 136 ALOI2_VertPstnTk8 "Adaptive Lighting Objects Information 2 : Vertical Position Track 8";
BA_ "SignalType" SG_ 136 ALOI2_TypTk7 "ENM";
BA_ "SignalLongName" SG_ 136 ALOI2_TypTk7 "Adaptive Lighting Objects Information 2 : Type Track 7";
BA_ "SignalType" SG_ 136 ALOI2_TypTk6 "ENM";
BA_ "SignalLongName" SG_ 136 ALOI2_TypTk6 "Adaptive Lighting Objects Information 2 : Type Track 6";
BA_ "SignalType" SG_ 136 ALOI2_DirTk5 "ENM";
BA_ "SignalLongName" SG_ 136 ALOI2_DirTk5 "Adaptive Lighting Objects Information 2 : Direction Track 5";
BA_ "SignalType" SG_ 136 ALOI2_TypTk8 "ENM";
BA_ "SignalLongName" SG_ 136 ALOI2_TypTk8 "Adaptive Lighting Objects Information 2 : Type Track 8";
BA_ "SignalType" SG_ 136 ALOI2_DirTk7 "ENM";
BA_ "SignalLongName" SG_ 136 ALOI2_DirTk7 "Adaptive Lighting Objects Information 2 : Direction Track 7";
BA_ "SignalType" SG_ 136 ALOI2_DirTk6 "ENM";
BA_ "SignalLongName" SG_ 136 ALOI2_DirTk6 "Adaptive Lighting Objects Information 2 : Direction Track 6";
BA_ "SignalType" SG_ 136 ALOI2_CnfdTk6 "ENM";
BA_ "SignalLongName" SG_ 136 ALOI2_CnfdTk6 "Adaptive Lighting Objects Information 2 : Confidence Track 6";
BA_ "SignalType" SG_ 136 ALOI2_CnfdTk5 "ENM";
BA_ "SignalLongName" SG_ 136 ALOI2_CnfdTk5 "Adaptive Lighting Objects Information 2 : Confidence Track 5";
BA_ "SignalLongName" SG_ 136 ALOI2_ARC "Adaptive Lighting Objects Information 2 : Alive Rolling Count";
BA_ "SignalType" SG_ 136 ALOI2_DirTk8 "ENM";
BA_ "SignalLongName" SG_ 136 ALOI2_DirTk8 "Adaptive Lighting Objects Information 2 : Direction Track 8";
BA_ "SignalType" SG_ 136 ALOI2_MeasStsTk6 "ENM";
BA_ "SignalLongName" SG_ 136 ALOI2_MeasStsTk6 "Adaptive Lighting Objects Information 2 : Measurement Status Track 6";
BA_ "SignalType" SG_ 136 ALOI2_MeasStsTk5 "ENM";
BA_ "SignalLongName" SG_ 136 ALOI2_MeasStsTk5 "Adaptive Lighting Objects Information 2 : Measurement Status Track 5";
BA_ "SignalType" SG_ 136 ALOI2_CnfdTk8 "ENM";
BA_ "SignalLongName" SG_ 136 ALOI2_CnfdTk8 "Adaptive Lighting Objects Information 2 : Confidence Track 8";
BA_ "SignalType" SG_ 136 ALOI2_CnfdTk7 "ENM";
BA_ "SignalLongName" SG_ 136 ALOI2_CnfdTk7 "Adaptive Lighting Objects Information 2 : Confidence Track 7";
BA_ "SignalType" SG_ 136 ALOI2_RltvLnTk6 "ENM";
BA_ "SignalLongName" SG_ 136 ALOI2_RltvLnTk6 "Adaptive Lighting Objects Information 2 : Relative Lane Track 6";
BA_ "SignalType" SG_ 136 ALOI2_RltvLnTk5 "ENM";
BA_ "SignalLongName" SG_ 136 ALOI2_RltvLnTk5 "Adaptive Lighting Objects Information 2 : Relative Lane Track 5";
BA_ "SignalType" SG_ 136 ALOI2_MeasStsTk8 "ENM";
BA_ "SignalLongName" SG_ 136 ALOI2_MeasStsTk8 "Adaptive Lighting Objects Information 2 : Measurement Status Track 8";
BA_ "SignalType" SG_ 136 ALOI2_MeasStsTk7 "ENM";
BA_ "SignalLongName" SG_ 136 ALOI2_MeasStsTk7 "Adaptive Lighting Objects Information 2 : Measurement Status Track 7";
BA_ "SignalType" SG_ 136 ALOI2_RngTk6_Inv "ENM";
BA_ "SignalLongName" SG_ 136 ALOI2_RngTk6_Inv "Adaptive Lighting Objects Information 2 : Range Track 6 Invalid";
BA_ "SignalType" SG_ 136 ALOI2_RngTk5_Inv "ENM";
BA_ "SignalLongName" SG_ 136 ALOI2_RngTk5_Inv "Adaptive Lighting Objects Information 2 : Range Track 5 Invalid";
BA_ "SignalType" SG_ 136 ALOI2_AcqTmStm_Inv "ENM";
BA_ "SignalLongName" SG_ 136 ALOI2_AcqTmStm_Inv "Adaptive Lighting Objects Information 2 : Acquisition Time Stamp Invalid";
BA_ "SignalType" SG_ 136 ALOI2_RltvLnTk8 "ENM";
BA_ "SignalLongName" SG_ 136 ALOI2_RltvLnTk8 "Adaptive Lighting Objects Information 2 : Relative Lane Track 8";
BA_ "SignalType" SG_ 136 ALOI2_RltvLnTk7 "ENM";
BA_ "SignalLongName" SG_ 136 ALOI2_RltvLnTk7 "Adaptive Lighting Objects Information 2 : Relative Lane Track 7";
BA_ "SignalType" SG_ 136 ALOI2_RngTk8_Inv "ENM";
BA_ "SignalLongName" SG_ 136 ALOI2_RngTk8_Inv "Adaptive Lighting Objects Information 2 : Range Track 8 Invalid";
BA_ "SignalType" SG_ 136 ALOI2_RngTk7_Inv "ENM";
BA_ "SignalLongName" SG_ 136 ALOI2_RngTk7_Inv "Adaptive Lighting Objects Information 2 : Range Track 7 Invalid";
BA_ "SignalLongName" SG_ 41 ARDG1_FrmTmStm1 "Augmented Reality Data Group 1 : Frame Time Stamp 1";
BA_ "SignalLongName" SG_ 41 ARDG1_ARC "Augmented Reality Data Group 1 : Alive Rolling Count";
BA_ "SignalLongName" SG_ 41 ARDG1_HstLnLtCrv "Augmented Reality Data Group 1 : Host Lane Left Curvature";
BA_ "SignalLongName" SG_ 41 ARDG1_HstLnLtCrvDrvt "Augmented Reality Data Group 1 : Host Lane Left Curvature Derivative";
BA_ "SignalLongName" SG_ 41 ARDG1_HstLnLtHdg "Augmented Reality Data Group 1 : Host Lane Left Heading";
BA_ "SignalLongName" SG_ 41 ARDG1_HstLnLtOfst "Augmented Reality Data Group 1 : Host Lane Left Offset";
BA_ "SignalLongName" SG_ 41 ARDG1_HstLnLtVwRngLngDist "Augmented Reality Data Group 1 : Host Lane Left View Range Longitudinal Distance";
BA_ "SignalType" SG_ 41 ARDG1_HstLnLtTyp "ENM";
BA_ "SignalLongName" SG_ 41 ARDG1_HstLnLtTyp "Augmented Reality Data Group 1 : Host Lane Left Type";
BA_ "SignalType" SG_ 41 ARDG1_HstLnLtQlty "ENM";
BA_ "SignalLongName" SG_ 41 ARDG1_HstLnLtQlty "Augmented Reality Data Group 1 : Host Lane Left Quality";
BA_ "SignalLongName" SG_ 41 ARDG1_HstLnLtVwStrtLngDist "Augmented Reality Data Group 1 : Host Lane Left View Start Longitudinal Distance";
BA_ "SignalLongName" SG_ 41 ARDG1_HstLnLtWdth "Augmented Reality Data Group 1 : Host Lane Left Width";
BA_ "SignalLongName" SG_ 41 ARDG1_HstNxtLnLtCrv "Augmented Reality Data Group 1 : Host Next Lane Left Curvature";
BA_ "SignalLongName" SG_ 41 ARDG1_HstNxtLnLtCrvDrvt "Augmented Reality Data Group 1 : Host Next Lane Left Curvature Derivative";
BA_ "SignalLongName" SG_ 41 ARDG1_HstNxtLnLtHdg "Augmented Reality Data Group 1 : Host Next Lane Left Heading";
BA_ "SignalLongName" SG_ 41 ARDG1_HstNxtLnLtOfst "Augmented Reality Data Group 1 : Host Next Lane Left Offset";
BA_ "SignalLongName" SG_ 41 ARDG1_HstNxtLnLtVwRngLngDist "Augmented Reality Data Group 1 : Host Next Lane Left View Range Longitudinal Distance";
BA_ "SignalType" SG_ 41 ARDG1_HstNxtLnLtTyp "ENM";
BA_ "SignalLongName" SG_ 41 ARDG1_HstNxtLnLtTyp "Augmented Reality Data Group 1 : Host Next Lane Left Type";
BA_ "SignalType" SG_ 41 ARDG1_HstNxtLnLtQlty "ENM";
BA_ "SignalLongName" SG_ 41 ARDG1_HstNxtLnLtQlty "Augmented Reality Data Group 1 : Host Next Lane Left Quality";
BA_ "SignalLongName" SG_ 41 ARDG1_HstNxtLnLtVwStrtLngDist "Augmented Reality Data Group 1 : Host Next Lane Left View Start Longitudinal Distance";
BA_ "SignalLongName" SG_ 41 ARDG1_HstNxtLnLtWdth "Augmented Reality Data Group 1 : Host Next Lane Left Width";
BA_ "SignalLongName" SG_ 41 ARDG1_LtVehAhdPoILatAccel "Augmented Reality Data Group 1 : Left Vehicle Ahead Point of Interest Lateral Acceleration";
BA_ "SignalType" SG_ 41 ARDG1_LtVehAhdMeasSts "ENM";
BA_ "SignalLongName" SG_ 41 ARDG1_LtVehAhdMeasSts "Augmented Reality Data Group 1 : Left Vehicle Ahead Measurement Status";
BA_ "SignalLongName" SG_ 41 ARDG1_LtVehAhdPoILatPstn "Augmented Reality Data Group 1 : Left Vehicle Ahead Point of Interest Lateral Position";
BA_ "SignalLongName" SG_ 41 ARDG1_LtVehAhdPoILatVel "Augmented Reality Data Group 1 : Left Vehicle Ahead Point of Interest Lateral Velocity";
BA_ "SignalLongName" SG_ 41 ARDG1_LtVehAhdPoILngAccel "Augmented Reality Data Group 1 : Left Vehicle Ahead Point of Interest Longitudinal Acceleration";
BA_ "SignalLongName" SG_ 41 ARDG1_LtVehAhdPoILngPstn "Augmented Reality Data Group 1 : Left Vehicle Ahead Point of Interest Longitudinal Position";
BA_ "SignalLongName" SG_ 41 ARDG1_LtVehAhdPoILngVel "Augmented Reality Data Group 1 : Left Vehicle Ahead Point of Interest Longitudinal Velocity";
BA_ "SignalLongName" SG_ 41 ARDG1_LtVehAhdPoIWdth "Augmented Reality Data Group 1 : Left Vehicle Ahead Point of Interest Width";
BA_ "SignalLongName" SG_ 41 ARDG2_ARC "Augmented Reality Data Group 2 : Alive Rolling Count";
BA_ "SignalType" SG_ 41 ARDG2_AutfxOutOfCal "ENM";
BA_ "SignalLongName" SG_ 41 ARDG2_AutfxOutOfCal "Augmented Reality Data Group 2 : Autofix Out of Calibration";
BA_ "SignalLongName" SG_ 41 ARDG2_AutfxHrzn "Augmented Reality Data Group 2 : Autofix Horizon";
BA_ "SignalLongName" SG_ 41 ARDG2_AutfxYaw "Augmented Reality Data Group 2 : Autofix Yaw";
BA_ "SignalLongName" SG_ 41 ARDG2_FrmTmStm2 "Augmented Reality Data Group 2 : Frame Time Stamp 2";
BA_ "SignalLongName" SG_ 41 ARDG2_FrwdCamAlgnLivePtch "Augmented Reality Data Group 2 : Forward Camera Alignment Live Pitch";
BA_ "SignalLongName" SG_ 41 ARDG2_FrwdCamAlgnHrzn "Augmented Reality Data Group 2 : Forward Camera Alignment Horizon";
BA_ "SignalLongName" SG_ 41 ARDG2_FrwdCamAlgnRoll "Augmented Reality Data Group 2 : Forward Camera Alignment Roll";
BA_ "SignalLongName" SG_ 41 ARDG2_FrwdCamAlgnYaw "Augmented Reality Data Group 2 : Forward Camera Alignment Yaw";
BA_ "SignalLongName" SG_ 41 ARDG2_FrwdVsnTmStm "Augmented Reality Data Group 2 : Forward Vision Time Stamp";
BA_ "SignalType" SG_ 41 ARDG2_FrwdCamSysOprtgSts "ENM";
BA_ "SignalLongName" SG_ 41 ARDG2_FrwdCamSysOprtgSts "Augmented Reality Data Group 2 : Forward Camera System Operating Status";
BA_ "SignalType" SG_ 41 ARDG2_HstVehAhdMeasSts "ENM";
BA_ "SignalLongName" SG_ 41 ARDG2_HstVehAhdMeasSts "Augmented Reality Data Group 2 : Host Vehicle Ahead Measurement Status";
BA_ "SignalType" SG_ 41 ARDG2_FrwdVsnUnv "ENM";
BA_ "SignalLongName" SG_ 41 ARDG2_FrwdVsnUnv "Augmented Reality Data Group 2 : Forward Vision Unavailable";
BA_ "SignalType" SG_ 41 ARDG2_FrwdVsnTmStm_Inv "ENM";
BA_ "SignalLongName" SG_ 41 ARDG2_FrwdVsnTmStm_Inv "Augmented Reality Data Group 2 : Forward Vision Time Stamp Invalid";
BA_ "SignalLongName" SG_ 41 ARDG2_HstVehAhdPoILatAccel "Augmented Reality Data Group 2 : Host Vehicle Ahead Point of Interest Lateral Acceleration";
BA_ "SignalLongName" SG_ 41 ARDG2_HstVehAhdPoILatPstn "Augmented Reality Data Group 2 : Host Vehicle Ahead Point of Interest Lateral Position";
BA_ "SignalLongName" SG_ 41 ARDG2_HstVehAhdPoILatVel "Augmented Reality Data Group 2 : Host Vehicle Ahead Point of Interest Lateral Velocity";
BA_ "SignalLongName" SG_ 41 ARDG2_HstVehAhdPoILngAccel "Augmented Reality Data Group 2 : Host Vehicle Ahead Point of Interest Longitudinal Acceleration";
BA_ "SignalLongName" SG_ 41 ARDG2_HstVehAhdPoILngPstn "Augmented Reality Data Group 2 : Host Vehicle Ahead Point of Interest Longitudinal Position";
BA_ "SignalLongName" SG_ 41 ARDG2_HstVehAhdPoILngVel "Augmented Reality Data Group 2 : Host Vehicle Ahead Point of Interest Longitudinal Velocity";
BA_ "SignalLongName" SG_ 41 ARDG2_HstVehAhdPoIWdth "Augmented Reality Data Group 2 : Host Vehicle Ahead Point of Interest Width";
BA_ "SignalLongName" SG_ 42 ARDG3_FrmTmStm3 "Augmented Reality Data Group 3 : Frame Time Stamp 3";
BA_ "SignalLongName" SG_ 42 ARDG3_ARC "Augmented Reality Data Group 3 : Alive Rolling Count";
BA_ "SignalLongName" SG_ 42 ARDG3_HstLnRtCrv "Augmented Reality Data Group 3 : Host Lane Right Curvature";
BA_ "SignalLongName" SG_ 42 ARDG3_HstLnRtCrvDrvt "Augmented Reality Data Group 3 : Host Lane Right Curvature Derivative";
BA_ "SignalLongName" SG_ 42 ARDG3_HstLnRtHdg "Augmented Reality Data Group 3 : Host Lane Right Heading";
BA_ "SignalLongName" SG_ 42 ARDG3_HstLnRtOfst "Augmented Reality Data Group 3 : Host Lane Right Offset";
BA_ "SignalLongName" SG_ 42 ARDG3_HstLnRtVwRngLngDist "Augmented Reality Data Group 3 : Host Lane Right View Range Longitudinal Distance";
BA_ "SignalType" SG_ 42 ARDG3_HstLnRtTyp "ENM";
BA_ "SignalLongName" SG_ 42 ARDG3_HstLnRtTyp "Augmented Reality Data Group 3 : Host Lane Right Type";
BA_ "SignalType" SG_ 42 ARDG3_HstLnRtQlty "ENM";
BA_ "SignalLongName" SG_ 42 ARDG3_HstLnRtQlty "Augmented Reality Data Group 3 : Host Lane Right Quality";
BA_ "SignalLongName" SG_ 42 ARDG3_HstLnRtVwStrtLngDist "Augmented Reality Data Group 3 : Host Lane Right View Start Longitudinal Distance";
BA_ "SignalLongName" SG_ 42 ARDG3_HstLnRtWdth "Augmented Reality Data Group 3 : Host Lane Right Width";
BA_ "SignalLongName" SG_ 42 ARDG3_HstNxtLnRtCrv "Augmented Reality Data Group 3 : Host Next Lane Right Curvature";
BA_ "SignalLongName" SG_ 42 ARDG3_HstNxtLnRtCrvDrvt "Augmented Reality Data Group 3 : Host Next Lane Right Curvature Derivative";
BA_ "SignalLongName" SG_ 42 ARDG3_HstNxtLnRtHdg "Augmented Reality Data Group 3 : Host Next Lane Right Heading";
BA_ "SignalLongName" SG_ 42 ARDG3_HstNxtLnRtOfst "Augmented Reality Data Group 3 : Host Next Lane Right Offset";
BA_ "SignalLongName" SG_ 42 ARDG3_HstNxtLnRtVwRngLngDist "Augmented Reality Data Group 3 : Host Next Lane Right View Range Longitudinal Distance";
BA_ "SignalType" SG_ 42 ARDG3_HstNxtLnRtTyp "ENM";
BA_ "SignalLongName" SG_ 42 ARDG3_HstNxtLnRtTyp "Augmented Reality Data Group 3 : Host Next Lane Right Type";
BA_ "SignalType" SG_ 42 ARDG3_HstNxtLnRtQlty "ENM";
BA_ "SignalLongName" SG_ 42 ARDG3_HstNxtLnRtQlty "Augmented Reality Data Group 3 : Host Next Lane Right Quality";
BA_ "SignalLongName" SG_ 42 ARDG3_HstNxtLnRtVwStrtLngDist "Augmented Reality Data Group 3 : Host Next Lane Right View Start Longitudinal Distance";
BA_ "SignalLongName" SG_ 42 ARDG3_HstNxtLnRtWdth "Augmented Reality Data Group 3 : Host Next Lane Right Width";
BA_ "SignalLongName" SG_ 42 ARDG3_RtVehAhdPoILatAccel "Augmented Reality Data Group 3 : Right Vehicle Ahead Point of Interest Lateral Acceleration";
BA_ "SignalType" SG_ 42 ARDG3_RtVehAhdMeasSts "ENM";
BA_ "SignalLongName" SG_ 42 ARDG3_RtVehAhdMeasSts "Augmented Reality Data Group 3 : Right Vehicle Ahead Measurement Status";
BA_ "SignalLongName" SG_ 42 ARDG3_RtVehAhdPoILatPstn "Augmented Reality Data Group 3 : Right Vehicle Ahead Point of Interest Lateral Position";
BA_ "SignalLongName" SG_ 42 ARDG3_RtVehAhdPoILatVel "Augmented Reality Data Group 3 : Right Vehicle Ahead Point of Interest Lateral Velocity";
BA_ "SignalLongName" SG_ 42 ARDG3_RtVehAhdPoILngAccel "Augmented Reality Data Group 3 : Right Vehicle Ahead Point of Interest Longitudinal Acceleration";
BA_ "SignalLongName" SG_ 42 ARDG3_RtVehAhdPoILngPstn "Augmented Reality Data Group 3 : Right Vehicle Ahead Point of Interest Longitudinal Position";
BA_ "SignalLongName" SG_ 42 ARDG3_RtVehAhdPoILngVel "Augmented Reality Data Group 3 : Right Vehicle Ahead Point of Interest Longitudinal Velocity";
BA_ "SignalLongName" SG_ 42 ARDG3_RtVehAhdPoIWdth "Augmented Reality Data Group 3 : Right Vehicle Ahead Point of Interest Width";
BA_ "SignalLongName" SG_ 526 BkupSysPwrMode_PCSM "Backup System Power Mode Protected Counter Sync Message";
BA_ "SignalLongName" SG_ 525 BSPMP_MAC "Backup System Power Mode Protected : MAC";
BA_ "SignalLongName" SG_ 525 BSPMP_FCnt "Backup System Power Mode Protected : Freshness Counter";
BA_ "SignalType" SG_ 525 BSPMP_SecRunCrnkCmdActvAuth_Inv "ENM";
BA_ "SignalLongName" SG_ 525 BSPMP_SecRunCrnkCmdActvAuth_Inv "Backup System Power Mode Protected : Secondary Run Crank Command Active Invalid Authenticated";
BA_ "SignalType" SG_ 525 BSPMP_SecRunCrnkCmdActvAuth "ENM";
BA_ "SignalLongName" SG_ 525 BSPMP_SecRunCrnkCmdActvAuth "Backup System Power Mode Protected : Secondary Run Crank Command Active Authenticated";
BA_ "SignalType" SG_ 525 BSPMP_SecPwrModePBActvAuth_Inv "ENM";
BA_ "SignalLongName" SG_ 525 BSPMP_SecPwrModePBActvAuth_Inv "Backup System Power Mode Protected : Secondary Power Mode Pushbutton Active Authenticated Invalid";
BA_ "SignalType" SG_ 525 BSPMP_SecPwrModePBActvAuth "ENM";
BA_ "SignalLongName" SG_ 525 BSPMP_SecPwrModePBActvAuth "Backup System Power Mode Protected : Secondary Power Mode Pushbutton Active Authenticated";
BA_ "SignalType" SG_ 525 BSPMP_BkupSysPwrModeAuth_Inv "ENM";
BA_ "SignalLongName" SG_ 525 BSPMP_BkupSysPwrModeAuth_Inv "Backup System Power Mode Protected : Backup System Power Mode Authenticated Invalid";
BA_ "SignalType" SG_ 525 BSPMP_BkupSysPwrModeAuth "ENM";
BA_ "SignalLongName" SG_ 525 BSPMP_BkupSysPwrModeAuth "Backup System Power Mode Protected : Backup System Power Mode Authenticated";
BA_ "SignalLongName" SG_ 525 BSPMP_PV "Backup System Power Mode Protected : Protection Value";
BA_ "SignalLongName" SG_ 525 BSPMP_ARC "Backup System Power Mode Protected : Alive Rolling Count";
BA_ "SignalType" SG_ 525 BSPMP_RmtProgmActvAuth "ENM";
BA_ "SignalLongName" SG_ 525 BSPMP_RmtProgmActvAuth "Backup System Power Mode Protected : Remote Programming Active Authenticated";
BA_ "SignalLongName" SG_ 227 FCODPB11P_FVVOTk10PoI4LgPsAuth "Front Camera Object Detection and Processing Burst 11 Protected : Forward Vision Vehicle Object Track 10 Point of Interest 4th Longitudinal Position Authenticated";
BA_ "SignalLongName" SG_ 227 FCODPB11P_BrstID "Front Camera Object Detection and Processing Burst 11 Protected : Burst ID";
BA_ "SignalLongName" SG_ 227 FCODPB11P_FVVOTk10PoI4LPsAuth "Front Camera Object Detection and Processing Burst 11 Protected : Forward Vision Vehicle Object Track 10 Point of Interest 4th Lateral Position Authenticated";
BA_ "SignalType" SG_ 227 FCODPB11P_FVVOTk10PoI4PsVisAuth "ENM";
BA_ "SignalLongName" SG_ 227 FCODPB11P_FVVOTk10PoI4PsVisAuth "Front Camera Object Detection and Processing Burst 11 Protected : Forward Vision Vehicle Object Track 10 Point of Interest 4th Position Visibility Authenticated";
BA_ "SignalLongName" SG_ 227 FCODPB11P_FVVOTk1PoI4LgPsAuth "Front Camera Object Detection and Processing Burst 11 Protected : Forward Vision Vehicle Object Track 1 Point of Interest 4th Longitudinal Position Authenticated";
BA_ "SignalLongName" SG_ 227 FCODPB11P_FVVOTk1PoI4LPsAuth "Front Camera Object Detection and Processing Burst 11 Protected : Forward Vision Vehicle Object Track 1 Point of Interest 4th Lateral Position Authenticated";
BA_ "SignalType" SG_ 227 FCODPB11P_FVVOTk1PoI4PsVisAuth "ENM";
BA_ "SignalLongName" SG_ 227 FCODPB11P_FVVOTk1PoI4PsVisAuth "Front Camera Object Detection and Processing Burst 11 Protected : Forward Vision Vehicle Object Track 1 Point of Interest 4th Position Visibility Authenticated";
BA_ "SignalLongName" SG_ 227 FCODPB11P_FVVOTk2PoI4LgPsAuth "Front Camera Object Detection and Processing Burst 11 Protected : Forward Vision Vehicle Object Track 2 Point of Interest 4th Longitudinal Position Authenticated";
BA_ "SignalLongName" SG_ 227 FCODPB11P_FVVOTk2PoI4LPsAuth "Front Camera Object Detection and Processing Burst 11 Protected : Forward Vision Vehicle Object Track 2 Point of Interest 4th Lateral Position Authenticated";
BA_ "SignalLongName" SG_ 227 FCODPB11P_FVVOTk3PoI4LgPsAuth "Front Camera Object Detection and Processing Burst 11 Protected : Forward Vision Vehicle Object Track 3 Point of Interest 4th Longitudinal Position Authenticated";
BA_ "SignalType" SG_ 227 FCODPB11P_FVVOTk2PoI4PsVisAuth "ENM";
BA_ "SignalLongName" SG_ 227 FCODPB11P_FVVOTk2PoI4PsVisAuth "Front Camera Object Detection and Processing Burst 11 Protected : Forward Vision Vehicle Object Track 2 Point of Interest 4th Position Visibility Authenticated";
BA_ "SignalLongName" SG_ 227 FCODPB11P_FVVOTk3PoI4LPsAuth "Front Camera Object Detection and Processing Burst 11 Protected : Forward Vision Vehicle Object Track 3 Point of Interest 4th Lateral Position Authenticated";
BA_ "SignalLongName" SG_ 227 FCODPB11P_FVVOTk4PoI4LgPsAuth "Front Camera Object Detection and Processing Burst 11 Protected : Forward Vision Vehicle Object Track 4 Point of Interest 4th Longitudinal Position Authenticated";
BA_ "SignalType" SG_ 227 FCODPB11P_FVVOTk3PoI4PsVisAuth "ENM";
BA_ "SignalLongName" SG_ 227 FCODPB11P_FVVOTk3PoI4PsVisAuth "Front Camera Object Detection and Processing Burst 11 Protected : Forward Vision Vehicle Object Track 3 Point of Interest 4th Position Visibility Authenticated";
BA_ "SignalLongName" SG_ 227 FCODPB11P_FVVOTk4PoI4LPsAuth "Front Camera Object Detection and Processing Burst 11 Protected : Forward Vision Vehicle Object Track 4 Point of Interest 4th Lateral Position Authenticated";
BA_ "SignalLongName" SG_ 227 FCODPB11P_FVVOTk5PoI4LgPsAuth "Front Camera Object Detection and Processing Burst 11 Protected : Forward Vision Vehicle Object Track 5 Point of Interest 4th Longitudinal Position Authenticated";
BA_ "SignalType" SG_ 227 FCODPB11P_FVVOTk4PoI4PsVisAuth "ENM";
BA_ "SignalLongName" SG_ 227 FCODPB11P_FVVOTk4PoI4PsVisAuth "Front Camera Object Detection and Processing Burst 11 Protected : Forward Vision Vehicle Object Track 4 Point of Interest 4th Position Visibility Authenticated";
BA_ "SignalLongName" SG_ 227 FCODPB11P_FVVOTk5PoI4LPsAuth "Front Camera Object Detection and Processing Burst 11 Protected : Forward Vision Vehicle Object Track 5 Point of Interest 4th Lateral Position Authenticated";
BA_ "SignalLongName" SG_ 227 FCODPB11P_FVVOTk6PoI4LgPsAuth "Front Camera Object Detection and Processing Burst 11 Protected : Forward Vision Vehicle Object Track 6 Point of Interest 4th Longitudinal Position Authenticated";
BA_ "SignalType" SG_ 227 FCODPB11P_FVVOTk5PoI4PsVisAuth "ENM";
BA_ "SignalLongName" SG_ 227 FCODPB11P_FVVOTk5PoI4PsVisAuth "Front Camera Object Detection and Processing Burst 11 Protected : Forward Vision Vehicle Object Track 5 Point of Interest 4th Position Visibility Authenticated";
BA_ "SignalLongName" SG_ 227 FCODPB11P_FVVOTk6PoI4LPsAuth "Front Camera Object Detection and Processing Burst 11 Protected : Forward Vision Vehicle Object Track 6 Point of Interest 4th Lateral Position Authenticated";
BA_ "SignalLongName" SG_ 227 FCODPB11P_FVVOTk7PoI4LgPsAuth "Front Camera Object Detection and Processing Burst 11 Protected : Forward Vision Vehicle Object Track 7 Point of Interest 4th Longitudinal Position Authenticated";
BA_ "SignalType" SG_ 227 FCODPB11P_FVVOTk6PoI4PsVisAuth "ENM";
BA_ "SignalLongName" SG_ 227 FCODPB11P_FVVOTk6PoI4PsVisAuth "Front Camera Object Detection and Processing Burst 11 Protected : Forward Vision Vehicle Object Track 6 Point of Interest 4th Position Visibility Authenticated";
BA_ "SignalLongName" SG_ 227 FCODPB11P_FVVOTk7PoI4LPsAuth "Front Camera Object Detection and Processing Burst 11 Protected : Forward Vision Vehicle Object Track 7 Point of Interest 4th Lateral Position Authenticated";
BA_ "SignalLongName" SG_ 227 FCODPB11P_FVVOTk8PoI4LgPsAuth "Front Camera Object Detection and Processing Burst 11 Protected : Forward Vision Vehicle Object Track 8 Point of Interest 4th Longitudinal Position Authenticated";
BA_ "SignalType" SG_ 227 FCODPB11P_FVVOTk7PoI4PsVisAuth "ENM";
BA_ "SignalLongName" SG_ 227 FCODPB11P_FVVOTk7PoI4PsVisAuth "Front Camera Object Detection and Processing Burst 11 Protected : Forward Vision Vehicle Object Track 7 Point of Interest 4th Position Visibility Authenticated";
BA_ "SignalLongName" SG_ 227 FCODPB11P_FVVOTk8PoI4LPsAuth "Front Camera Object Detection and Processing Burst 11 Protected : Forward Vision Vehicle Object Track 8 Point of Interest 4th Lateral Position Authenticated";
BA_ "SignalType" SG_ 227 FCODPB11P_FVVOTk8PoI4PsVisAuth "ENM";
BA_ "SignalLongName" SG_ 227 FCODPB11P_FVVOTk8PoI4PsVisAuth "Front Camera Object Detection and Processing Burst 11 Protected : Forward Vision Vehicle Object Track 8 Point of Interest 4th Position Visibility Authenticated";
BA_ "SignalLongName" SG_ 227 FCODPB11P_FVVOTk9PoI4LgPsAuth "Front Camera Object Detection and Processing Burst 11 Protected : Forward Vision Vehicle Object Track 9 Point of Interest 4th Longitudinal Position Authenticated";
BA_ "SignalLongName" SG_ 227 FCODPB11P_FVVOTk9PoI4LPsAuth "Front Camera Object Detection and Processing Burst 11 Protected : Forward Vision Vehicle Object Track 9 Point of Interest 4th Lateral Position Authenticated";
BA_ "SignalType" SG_ 227 FCODPB11P_FVVOTk9PoI4PsVisAuth "ENM";
BA_ "SignalLongName" SG_ 227 FCODPB11P_FVVOTk9PoI4PsVisAuth "Front Camera Object Detection and Processing Burst 11 Protected : Forward Vision Vehicle Object Track 9 Point of Interest 4th Position Visibility Authenticated";
BA_ "SignalLongName" SG_ 227 FCODPB11P_LnTrPtEndLatDistAuth "Front Camera Object Detection and Processing Burst 11 Protected : Lane Transition Point End Lateral Distance Authenticated";
BA_ "SignalLongName" SG_ 227 FCODPB11P_LnTrPtEndLngDistAuth "Front Camera Object Detection and Processing Burst 11 Protected : Lane Transition Point End Longitudinal Distance Authenticated";
BA_ "SignalLongName" SG_ 227 FCODPB11P_LnTrPtStrtLatDistAuth "Front Camera Object Detection and Processing Burst 11 Protected : Lane Transition Point Start Lateral Distance Authenticated";
BA_ "SignalType" SG_ 227 FCODPB11P_LnTrPtEndTypAuth "ENM";
BA_ "SignalLongName" SG_ 227 FCODPB11P_LnTrPtEndTypAuth "Front Camera Object Detection and Processing Burst 11 Protected : Lane Transition Point End Type Authenticated";
BA_ "SignalLongName" SG_ 227 FCODPB11P_LnTrPtStrtLngDistAuth "Front Camera Object Detection and Processing Burst 11 Protected : Lane Transition Point Start Longitudinal Distance Authenticated";
BA_ "SignalType" SG_ 227 FCODPB11P_LnTrPtStrtTypAuth "ENM";
BA_ "SignalLongName" SG_ 227 FCODPB11P_LnTrPtStrtTypAuth "Front Camera Object Detection and Processing Burst 11 Protected : Lane Transition Point Start Type Authenticated";
BA_ "SignalLongName" SG_ 227 FCODPB11P_RdVertPP10LngDistAuth "Front Camera Object Detection and Processing Burst 11 Protected : Road Vertical Profile Point 10 Longitudinal Distance Authenticated";
BA_ "SignalType" SG_ 227 FCODPB11P_FrwdVsnModeCmdStsAuth "ENM";
BA_ "SignalLongName" SG_ 227 FCODPB11P_FrwdVsnModeCmdStsAuth "Front Camera Object Detection and Processing Burst 11 Protected : Forward Vision Mode Command Status Authenticated";
BA_ "SignalLongName" SG_ 227 FCODPB11P_LnTrPtSyncIdxAuth "Front Camera Object Detection and Processing Burst 11 Protected : Lane Transition Point Sync Index Authenticated";
BA_ "SignalLongName" SG_ 227 FCODPB11P_RdVertPP11LngDistAuth "Front Camera Object Detection and Processing Burst 11 Protected : Road Vertical Profile Point 11 Longitudinal Distance Authenticated";
BA_ "SignalLongName" SG_ 227 FCODPB11P_RdVertPP12LngDistAuth "Front Camera Object Detection and Processing Burst 11 Protected : Road Vertical Profile Point 12 Longitudinal Distance Authenticated";
BA_ "SignalLongName" SG_ 227 FCODPB11P_RdVertPP13LngDistAuth "Front Camera Object Detection and Processing Burst 11 Protected : Road Vertical Profile Point 13 Longitudinal Distance Authenticated";
BA_ "SignalLongName" SG_ 227 FCODPB11P_RdVertPP14LngDistAuth "Front Camera Object Detection and Processing Burst 11 Protected : Road Vertical Profile Point 14 Longitudinal Distance Authenticated";
BA_ "SignalLongName" SG_ 227 FCODPB11P_RdVertPP15LngDistAuth "Front Camera Object Detection and Processing Burst 11 Protected : Road Vertical Profile Point 15 Longitudinal Distance Authenticated";
BA_ "SignalLongName" SG_ 227 FCODPB11P_RdVertPP1LngDistAuth "Front Camera Object Detection and Processing Burst 11 Protected : Road Vertical Profile Point 1 Longitudinal Distance Authenticated";
BA_ "SignalLongName" SG_ 227 FCODPB11P_RdVertPP2LngDistAuth "Front Camera Object Detection and Processing Burst 11 Protected : Road Vertical Profile Point 2 Longitudinal Distance Authenticated";
BA_ "SignalLongName" SG_ 227 FCODPB11P_RdVertPP3LngDistAuth "Front Camera Object Detection and Processing Burst 11 Protected : Road Vertical Profile Point 3 Longitudinal Distance Authenticated";
BA_ "SignalLongName" SG_ 227 FCODPB11P_RdVertPP4LngDistAuth "Front Camera Object Detection and Processing Burst 11 Protected : Road Vertical Profile Point 4 Longitudinal Distance Authenticated";
BA_ "SignalLongName" SG_ 227 FCODPB11P_RdVertPP5LngDistAuth "Front Camera Object Detection and Processing Burst 11 Protected : Road Vertical Profile Point 5 Longitudinal Distance Authenticated";
BA_ "SignalLongName" SG_ 227 FCODPB11P_RdVertPP6LngDistAuth "Front Camera Object Detection and Processing Burst 11 Protected : Road Vertical Profile Point 6 Longitudinal Distance Authenticated";
BA_ "SignalLongName" SG_ 227 FCODPB11P_RdVertPP7LngDistAuth "Front Camera Object Detection and Processing Burst 11 Protected : Road Vertical Profile Point 7 Longitudinal Distance Authenticated";
BA_ "SignalLongName" SG_ 227 FCODPB11P_RdVertPP8LngDistAuth "Front Camera Object Detection and Processing Burst 11 Protected : Road Vertical Profile Point 8 Longitudinal Distance Authenticated";
BA_ "SignalLongName" SG_ 227 FCODPB11P_RdVertPP9LngDistAuth "Front Camera Object Detection and Processing Burst 11 Protected : Road Vertical Profile Point 9 Longitudinal Distance Authenticated";
BA_ "SignalType" SG_ 227 FCODPB11P_ShldrDtnRtofVehAuth "ENM";
BA_ "SignalLongName" SG_ 227 FCODPB11P_ShldrDtnRtofVehAuth "Front Camera Object Detection and Processing Burst 11 Protected : Shoulder Detection Right of Vehicle Authenticated";
BA_ "SignalType" SG_ 227 FCODPB11P_ShldrDtnLtofVehAuth "ENM";
BA_ "SignalLongName" SG_ 227 FCODPB11P_ShldrDtnLtofVehAuth "Front Camera Object Detection and Processing Burst 11 Protected : Shoulder Detection Left of Vehicle Authenticated";
BA_ "SignalLongName" SG_ 236 FCODPB12P_FVTS1AgeAuth "Front Camera Object Detection and Processing Burst 12 Protected : Forward Vision Traffic Sign 1 Age Authenticated";
BA_ "SignalLongName" SG_ 236 FCODPB12P_BrstID "Front Camera Object Detection and Processing Burst 12 Protected : Burst ID";
BA_ "SignalType" SG_ 236 FCODPB12P_FVTS1PsdbyHstVehAuth "ENM";
BA_ "SignalLongName" SG_ 236 FCODPB12P_FVTS1PsdbyHstVehAuth "Front Camera Object Detection and Processing Burst 12 Protected : Forward Vision Traffic Sign 1 Passed by Host Vehicle Authenticated";
BA_ "SignalType" SG_ 236 FCODPB12P_FVTS1PhysTypAuth "ENM";
BA_ "SignalLongName" SG_ 236 FCODPB12P_FVTS1PhysTypAuth "Front Camera Object Detection and Processing Burst 12 Protected : Forward Vision Traffic Sign 1 Physical Type Authenticated";
BA_ "SignalType" SG_ 236 FCODPB12P_FVTS1MeasVldAuth "ENM";
BA_ "SignalLongName" SG_ 236 FCODPB12P_FVTS1MeasVldAuth "Front Camera Object Detection and Processing Burst 12 Protected : Forward Vision Traffic Sign 1 Measurement Valid Authenticated";
BA_ "SignalType" SG_ 236 FCODPB12P_FVTS1FiltTypAuth "ENM";
BA_ "SignalLongName" SG_ 236 FCODPB12P_FVTS1FiltTypAuth "Front Camera Object Detection and Processing Burst 12 Protected : Forward Vision Traffic Sign 1 Filter Type Authenticated";
BA_ "SignalLongName" SG_ 236 FCODPB12P_FVTS2AgeAuth "Front Camera Object Detection and Processing Burst 12 Protected : Forward Vision Traffic Sign 2 Age Authenticated";
BA_ "SignalType" SG_ 236 FCODPB12P_FVTS1ZnDtdAuth "ENM";
BA_ "SignalLongName" SG_ 236 FCODPB12P_FVTS1ZnDtdAuth "Front Camera Object Detection and Processing Burst 12 Protected : Forward Vision Traffic Sign 1 Zone Detected Authenticated";
BA_ "SignalType" SG_ 236 FCODPB12P_FVTS2ZnDtdAuth "ENM";
BA_ "SignalLongName" SG_ 236 FCODPB12P_FVTS2ZnDtdAuth "Front Camera Object Detection and Processing Burst 12 Protected : Forward Vision Traffic Sign 2 Zone Detected Authenticated";
BA_ "SignalType" SG_ 236 FCODPB12P_FVTS2PsdbyHstVehAuth "ENM";
BA_ "SignalLongName" SG_ 236 FCODPB12P_FVTS2PsdbyHstVehAuth "Front Camera Object Detection and Processing Burst 12 Protected : Forward Vision Traffic Sign 2 Passed by Host Vehicle Authenticated";
BA_ "SignalType" SG_ 236 FCODPB12P_FVTS2PhysTypAuth "ENM";
BA_ "SignalLongName" SG_ 236 FCODPB12P_FVTS2PhysTypAuth "Front Camera Object Detection and Processing Burst 12 Protected : Forward Vision Traffic Sign 2 Physical Type Authenticated";
BA_ "SignalType" SG_ 236 FCODPB12P_FVTS2MeasVldAuth "ENM";
BA_ "SignalLongName" SG_ 236 FCODPB12P_FVTS2MeasVldAuth "Front Camera Object Detection and Processing Burst 12 Protected : Forward Vision Traffic Sign 2 Measurement Valid Authenticated";
BA_ "SignalType" SG_ 236 FCODPB12P_FVTS2FiltTypAuth "ENM";
BA_ "SignalLongName" SG_ 236 FCODPB12P_FVTS2FiltTypAuth "Front Camera Object Detection and Processing Burst 12 Protected : Forward Vision Traffic Sign 2 Filter Type Authenticated";
BA_ "SignalLongName" SG_ 236 FCODPB12P_FVTS3AgeAuth "Front Camera Object Detection and Processing Burst 12 Protected : Forward Vision Traffic Sign 3 Age Authenticated";
BA_ "SignalLongName" SG_ 236 FCODPB12P_FVTS4AgeAuth "Front Camera Object Detection and Processing Burst 12 Protected : Forward Vision Traffic Sign 4 Age Authenticated";
BA_ "SignalType" SG_ 236 FCODPB12P_FVTS3ZnDtdAuth "ENM";
BA_ "SignalLongName" SG_ 236 FCODPB12P_FVTS3ZnDtdAuth "Front Camera Object Detection and Processing Burst 12 Protected : Forward Vision Traffic Sign 3 Zone Detected Authenticated";
BA_ "SignalType" SG_ 236 FCODPB12P_FVTS3PsdbyHstVehAuth "ENM";
BA_ "SignalLongName" SG_ 236 FCODPB12P_FVTS3PsdbyHstVehAuth "Front Camera Object Detection and Processing Burst 12 Protected : Forward Vision Traffic Sign 3 Passed by Host Vehicle Authenticated";
BA_ "SignalType" SG_ 236 FCODPB12P_FVTS3PhysTypAuth "ENM";
BA_ "SignalLongName" SG_ 236 FCODPB12P_FVTS3PhysTypAuth "Front Camera Object Detection and Processing Burst 12 Protected : Forward Vision Traffic Sign 3 Physical Type Authenticated";
BA_ "SignalType" SG_ 236 FCODPB12P_FVTS3MeasVldAuth "ENM";
BA_ "SignalLongName" SG_ 236 FCODPB12P_FVTS3MeasVldAuth "Front Camera Object Detection and Processing Burst 12 Protected : Forward Vision Traffic Sign 3 Measurement Valid Authenticated";
BA_ "SignalType" SG_ 236 FCODPB12P_FVTS3FiltTypAuth "ENM";
BA_ "SignalLongName" SG_ 236 FCODPB12P_FVTS3FiltTypAuth "Front Camera Object Detection and Processing Burst 12 Protected : Forward Vision Traffic Sign 3 Filter Type Authenticated";
BA_ "SignalType" SG_ 236 FCODPB12P_FVTS4FiltTypAuth "ENM";
BA_ "SignalLongName" SG_ 236 FCODPB12P_FVTS4FiltTypAuth "Front Camera Object Detection and Processing Burst 12 Protected : Forward Vision Traffic Sign 4 Filter Type Authenticated";
BA_ "SignalLongName" SG_ 236 FCODPB12P_FVTS5AgeAuth "Front Camera Object Detection and Processing Burst 12 Protected : Forward Vision Traffic Sign 5 Age Authenticated";
BA_ "SignalType" SG_ 236 FCODPB12P_FVTS4ZnDtdAuth "ENM";
BA_ "SignalLongName" SG_ 236 FCODPB12P_FVTS4ZnDtdAuth "Front Camera Object Detection and Processing Burst 12 Protected : Forward Vision Traffic Sign 4 Zone Detected Authenticated";
BA_ "SignalType" SG_ 236 FCODPB12P_FVTS4PsdbyHstVehAuth "ENM";
BA_ "SignalLongName" SG_ 236 FCODPB12P_FVTS4PsdbyHstVehAuth "Front Camera Object Detection and Processing Burst 12 Protected : Forward Vision Traffic Sign 4 Passed by Host Vehicle Authenticated";
BA_ "SignalType" SG_ 236 FCODPB12P_FVTS4PhysTypAuth "ENM";
BA_ "SignalLongName" SG_ 236 FCODPB12P_FVTS4PhysTypAuth "Front Camera Object Detection and Processing Burst 12 Protected : Forward Vision Traffic Sign 4 Physical Type Authenticated";
BA_ "SignalType" SG_ 236 FCODPB12P_FVTS4MeasVldAuth "ENM";
BA_ "SignalLongName" SG_ 236 FCODPB12P_FVTS4MeasVldAuth "Front Camera Object Detection and Processing Burst 12 Protected : Forward Vision Traffic Sign 4 Measurement Valid Authenticated";
BA_ "SignalType" SG_ 236 FCODPB12P_FVTS5FiltTypAuth "ENM";
BA_ "SignalLongName" SG_ 236 FCODPB12P_FVTS5FiltTypAuth "Front Camera Object Detection and Processing Burst 12 Protected : Forward Vision Traffic Sign 5 Filter Type Authenticated";
BA_ "SignalLongName" SG_ 236 FCODPB12P_FVTS6AgeAuth "Front Camera Object Detection and Processing Burst 12 Protected : Forward Vision Traffic Sign 6 Age Authenticated";
BA_ "SignalType" SG_ 236 FCODPB12P_FVTS5ZnDtdAuth "ENM";
BA_ "SignalLongName" SG_ 236 FCODPB12P_FVTS5ZnDtdAuth "Front Camera Object Detection and Processing Burst 12 Protected : Forward Vision Traffic Sign 5 Zone Detected Authenticated";
BA_ "SignalType" SG_ 236 FCODPB12P_FVTS5PsdbyHstVehAuth "ENM";
BA_ "SignalLongName" SG_ 236 FCODPB12P_FVTS5PsdbyHstVehAuth "Front Camera Object Detection and Processing Burst 12 Protected : Forward Vision Traffic Sign 5 Passed by Host Vehicle Authenticated";
BA_ "SignalType" SG_ 236 FCODPB12P_FVTS5PhysTypAuth "ENM";
BA_ "SignalLongName" SG_ 236 FCODPB12P_FVTS5PhysTypAuth "Front Camera Object Detection and Processing Burst 12 Protected : Forward Vision Traffic Sign 5 Physical Type Authenticated";
BA_ "SignalType" SG_ 236 FCODPB12P_FVTS5MeasVldAuth "ENM";
BA_ "SignalLongName" SG_ 236 FCODPB12P_FVTS5MeasVldAuth "Front Camera Object Detection and Processing Burst 12 Protected : Forward Vision Traffic Sign 5 Measurement Valid Authenticated";
BA_ "SignalType" SG_ 236 FCODPB12P_FVTS6MeasVldAuth "ENM";
BA_ "SignalLongName" SG_ 236 FCODPB12P_FVTS6MeasVldAuth "Front Camera Object Detection and Processing Burst 12 Protected : Forward Vision Traffic Sign 6 Measurement Valid Authenticated";
BA_ "SignalType" SG_ 236 FCODPB12P_FVTS6FiltTypAuth "ENM";
BA_ "SignalLongName" SG_ 236 FCODPB12P_FVTS6FiltTypAuth "Front Camera Object Detection and Processing Burst 12 Protected : Forward Vision Traffic Sign 6 Filter Type Authenticated";
BA_ "SignalLongName" SG_ 236 FCODPB12P_RdBnkCrv1CrvAuth "Front Camera Object Detection and Processing Burst 12 Protected : Road Bank Curvature 1 Curvature Authenticated";
BA_ "SignalType" SG_ 236 FCODPB12P_RdBnkCrv1CnfdStsAuth "ENM";
BA_ "SignalLongName" SG_ 236 FCODPB12P_RdBnkCrv1CnfdStsAuth "Front Camera Object Detection and Processing Burst 12 Protected : Road Bank Curvature 1 Confidence Status Authenticated";
BA_ "SignalType" SG_ 236 FCODPB12P_FVTS6ZnDtdAuth "ENM";
BA_ "SignalLongName" SG_ 236 FCODPB12P_FVTS6ZnDtdAuth "Front Camera Object Detection and Processing Burst 12 Protected : Forward Vision Traffic Sign 6 Zone Detected Authenticated";
BA_ "SignalType" SG_ 236 FCODPB12P_FVTS6PsdbyHstVehAuth "ENM";
BA_ "SignalLongName" SG_ 236 FCODPB12P_FVTS6PsdbyHstVehAuth "Front Camera Object Detection and Processing Burst 12 Protected : Forward Vision Traffic Sign 6 Passed by Host Vehicle Authenticated";
BA_ "SignalType" SG_ 236 FCODPB12P_FVTS6PhysTypAuth "ENM";
BA_ "SignalLongName" SG_ 236 FCODPB12P_FVTS6PhysTypAuth "Front Camera Object Detection and Processing Burst 12 Protected : Forward Vision Traffic Sign 6 Physical Type Authenticated";
BA_ "SignalLongName" SG_ 236 FCODPB12P_RdBnkCrv1CrvDrvtAuth "Front Camera Object Detection and Processing Burst 12 Protected : Road Bank Curvature 1 Curvature Derivative Authenticated";
BA_ "SignalLongName" SG_ 236 FCODPB12P_RdBnkCrv1HdgAuth "Front Camera Object Detection and Processing Burst 12 Protected : Road Bank Curvature 1 Heading Authenticated";
BA_ "SignalLongName" SG_ 236 FCODPB12P_RdBnkCrv1LatOfstAuth "Front Camera Object Detection and Processing Burst 12 Protected : Road Bank Curvature 1 Lateral Offset Authenticated";
BA_ "SignalLongName" SG_ 236 FCODPB12P_RdBnkCrv1LngOfstAuth "Front Camera Object Detection and Processing Burst 12 Protected : Road Bank Curvature 1 Longitudinal Offset Authenticated";
BA_ "SignalLongName" SG_ 236 FCODPB12P_RdBnkCrv1PsEndAuth "Front Camera Object Detection and Processing Burst 12 Protected : Road Bank Curvature 1 Position End Authenticated";
BA_ "SignalLongName" SG_ 236 FCODPB12P_RdBnkCrv1PsStrtAuth "Front Camera Object Detection and Processing Burst 12 Protected : Road Bank Curvature 1 Position Start Authenticated";
BA_ "SignalLongName" SG_ 236 FCODPB12P_RdBnkCrv2CrvAuth "Front Camera Object Detection and Processing Burst 12 Protected : Road Bank Curvature 2 Curvature Authenticated";
BA_ "SignalType" SG_ 236 FCODPB12P_RdBnkCrv2CnfdStsAuth "ENM";
BA_ "SignalLongName" SG_ 236 FCODPB12P_RdBnkCrv2CnfdStsAuth "Front Camera Object Detection and Processing Burst 12 Protected : Road Bank Curvature 2 Confidence Status Authenticated";
BA_ "SignalLongName" SG_ 236 FCODPB12P_RdBnkCrv2CrvDrvtAuth "Front Camera Object Detection and Processing Burst 12 Protected : Road Bank Curvature 2 Curvature Derivative Authenticated";
BA_ "SignalLongName" SG_ 236 FCODPB12P_RdBnkCrv2HdgAuth "Front Camera Object Detection and Processing Burst 12 Protected : Road Bank Curvature 2 Heading Authenticated";
BA_ "SignalLongName" SG_ 236 FCODPB12P_RdBnkCrv2LatOfstAuth "Front Camera Object Detection and Processing Burst 12 Protected : Road Bank Curvature 2 Lateral Offset Authenticated";
BA_ "SignalLongName" SG_ 236 FCODPB12P_RdBnkCrv2LngOfstAuth "Front Camera Object Detection and Processing Burst 12 Protected : Road Bank Curvature 2 Longitudinal Offset Authenticated";
BA_ "SignalLongName" SG_ 236 FCODPB12P_RdBnkCrv2PsEndAuth "Front Camera Object Detection and Processing Burst 12 Protected : Road Bank Curvature 2 Position End Authenticated";
BA_ "SignalLongName" SG_ 236 FCODPB12P_RdBnkCrv2PsStrtAuth "Front Camera Object Detection and Processing Burst 12 Protected : Road Bank Curvature 2 Position Start Authenticated";
BA_ "SignalLongName" SG_ 236 FCODPB12P_RdBnkCrv3CrvAuth "Front Camera Object Detection and Processing Burst 12 Protected : Road Bank Curvature 3 Curvature Authenticated";
BA_ "SignalType" SG_ 236 FCODPB12P_RdBnkCrv3CnfdStsAuth "ENM";
BA_ "SignalLongName" SG_ 236 FCODPB12P_RdBnkCrv3CnfdStsAuth "Front Camera Object Detection and Processing Burst 12 Protected : Road Bank Curvature 3 Confidence Status Authenticated";
BA_ "SignalLongName" SG_ 236 FCODPB12P_RdBnkCrv3CrvDrvtAuth "Front Camera Object Detection and Processing Burst 12 Protected : Road Bank Curvature 3 Curvature Derivative Authenticated";
BA_ "SignalLongName" SG_ 236 FCODPB12P_RdBnkCrv3HdgAuth "Front Camera Object Detection and Processing Burst 12 Protected : Road Bank Curvature 3 Heading Authenticated";
BA_ "SignalLongName" SG_ 236 FCODPB12P_RdBnkCrv3LatOfstAuth "Front Camera Object Detection and Processing Burst 12 Protected : Road Bank Curvature 3 Lateral Offset Authenticated";
BA_ "SignalLongName" SG_ 236 FCODPB12P_RdBnkCrv3LngOfstAuth "Front Camera Object Detection and Processing Burst 12 Protected : Road Bank Curvature 3 Longitudinal Offset Authenticated";
BA_ "SignalLongName" SG_ 236 FCODPB12P_RdBnkCrv3PsEndAuth "Front Camera Object Detection and Processing Burst 12 Protected : Road Bank Curvature 3 Position End Authenticated";
BA_ "SignalLongName" SG_ 236 FCODPB12P_RdBnkCrv3PsStrtAuth "Front Camera Object Detection and Processing Burst 12 Protected : Road Bank Curvature 3 Position Start Authenticated";
BA_ "SignalLongName" SG_ 236 FCODPB12P_RdVertPP10ElvtnAuth "Front Camera Object Detection and Processing Burst 12 Protected : Road Vertical Profile Point 10 Elevation Authenticated";
BA_ "SignalLongName" SG_ 236 FCODPB12P_RdVertPP11ElvtnAuth "Front Camera Object Detection and Processing Burst 12 Protected : Road Vertical Profile Point 11 Elevation Authenticated";
BA_ "SignalLongName" SG_ 236 FCODPB12P_RdVertPP12ElvtnAuth "Front Camera Object Detection and Processing Burst 12 Protected : Road Vertical Profile Point 12 Elevation Authenticated";
BA_ "SignalLongName" SG_ 236 FCODPB12P_RdVertPP13ElvtnAuth "Front Camera Object Detection and Processing Burst 12 Protected : Road Vertical Profile Point 13 Elevation Authenticated";
BA_ "SignalLongName" SG_ 236 FCODPB12P_RdVertPP14ElvtnAuth "Front Camera Object Detection and Processing Burst 12 Protected : Road Vertical Profile Point 14 Elevation Authenticated";
BA_ "SignalLongName" SG_ 236 FCODPB12P_RdVertPP15ElvtnAuth "Front Camera Object Detection and Processing Burst 12 Protected : Road Vertical Profile Point 15 Elevation Authenticated";
BA_ "SignalLongName" SG_ 236 FCODPB12P_RdVertPP1ElvtnAuth "Front Camera Object Detection and Processing Burst 12 Protected : Road Vertical Profile Point 1 Elevation Authenticated";
BA_ "SignalLongName" SG_ 236 FCODPB12P_RdVertPP2ElvtnAuth "Front Camera Object Detection and Processing Burst 12 Protected : Road Vertical Profile Point 2 Elevation Authenticated";
BA_ "SignalLongName" SG_ 236 FCODPB12P_RdVertPP3ElvtnAuth "Front Camera Object Detection and Processing Burst 12 Protected : Road Vertical Profile Point 3 Elevation Authenticated";
BA_ "SignalLongName" SG_ 236 FCODPB12P_RdVertPP4ElvtnAuth "Front Camera Object Detection and Processing Burst 12 Protected : Road Vertical Profile Point 4 Elevation Authenticated";
BA_ "SignalLongName" SG_ 236 FCODPB12P_RdVertPP5ElvtnAuth "Front Camera Object Detection and Processing Burst 12 Protected : Road Vertical Profile Point 5 Elevation Authenticated";
BA_ "SignalLongName" SG_ 236 FCODPB12P_RdVertPP6ElvtnAuth "Front Camera Object Detection and Processing Burst 12 Protected : Road Vertical Profile Point 6 Elevation Authenticated";
BA_ "SignalLongName" SG_ 236 FCODPB12P_RdVertPP7ElvtnAuth "Front Camera Object Detection and Processing Burst 12 Protected : Road Vertical Profile Point 7 Elevation Authenticated";
BA_ "SignalLongName" SG_ 236 FCODPB12P_RdVertPP8ElvtnAuth "Front Camera Object Detection and Processing Burst 12 Protected : Road Vertical Profile Point 8 Elevation Authenticated";
BA_ "SignalLongName" SG_ 236 FCODPB12P_RdVertPP9ElvtnAuth "Front Camera Object Detection and Processing Burst 12 Protected : Road Vertical Profile Point 9 Elevation Authenticated";
BA_ "SignalLongName" SG_ 237 FCODPB13P_FVTS10AgeAuth "Front Camera Object Detection and Processing Burst 13 Protected : Forward Vision Traffic Sign 10 Age Authenticated";
BA_ "SignalLongName" SG_ 237 FCODPB13P_BrstID "Front Camera Object Detection and Processing Burst 13 Protected : Burst ID";
BA_ "SignalType" SG_ 237 FCODPB13P_FVTS10PsdbyHstVehAuth "ENM";
BA_ "SignalLongName" SG_ 237 FCODPB13P_FVTS10PsdbyHstVehAuth "Front Camera Object Detection and Processing Burst 13 Protected : Forward Vision Traffic Sign 10 Passed by Host Vehicle Authenticated";
BA_ "SignalType" SG_ 237 FCODPB13P_FVTS10PhysTypAuth "ENM";
BA_ "SignalLongName" SG_ 237 FCODPB13P_FVTS10PhysTypAuth "Front Camera Object Detection and Processing Burst 13 Protected : Forward Vision Traffic Sign 10 Physical Type Authenticated";
BA_ "SignalType" SG_ 237 FCODPB13P_FVTS10MeasVldAuth "ENM";
BA_ "SignalLongName" SG_ 237 FCODPB13P_FVTS10MeasVldAuth "Front Camera Object Detection and Processing Burst 13 Protected : Forward Vision Traffic Sign 10 Measurement Valid Authenticated";
BA_ "SignalType" SG_ 237 FCODPB13P_FVTS10FiltTypAuth "ENM";
BA_ "SignalLongName" SG_ 237 FCODPB13P_FVTS10FiltTypAuth "Front Camera Object Detection and Processing Burst 13 Protected : Forward Vision Traffic Sign 10 Filter Type Authenticated";
BA_ "SignalLongName" SG_ 237 FCODPB13P_FVTS7AgeAuth "Front Camera Object Detection and Processing Burst 13 Protected : Forward Vision Traffic Sign 7 Age Authenticated";
BA_ "SignalType" SG_ 237 FCODPB13P_FVTS10ZnDtdAuth "ENM";
BA_ "SignalLongName" SG_ 237 FCODPB13P_FVTS10ZnDtdAuth "Front Camera Object Detection and Processing Burst 13 Protected : Forward Vision Traffic Sign 10 Zone Detected Authenticated";
BA_ "SignalType" SG_ 237 FCODPB13P_FVTS7ZnDtdAuth "ENM";
BA_ "SignalLongName" SG_ 237 FCODPB13P_FVTS7ZnDtdAuth "Front Camera Object Detection and Processing Burst 13 Protected : Forward Vision Traffic Sign 7 Zone Detected Authenticated";
BA_ "SignalType" SG_ 237 FCODPB13P_FVTS7PsdbyHstVehAuth "ENM";
BA_ "SignalLongName" SG_ 237 FCODPB13P_FVTS7PsdbyHstVehAuth "Front Camera Object Detection and Processing Burst 13 Protected : Forward Vision Traffic Sign 7 Passed by Host Vehicle Authenticated";
BA_ "SignalType" SG_ 237 FCODPB13P_FVTS7PhysTypAuth "ENM";
BA_ "SignalLongName" SG_ 237 FCODPB13P_FVTS7PhysTypAuth "Front Camera Object Detection and Processing Burst 13 Protected : Forward Vision Traffic Sign 7 Physical Type Authenticated";
BA_ "SignalType" SG_ 237 FCODPB13P_FVTS7MeasVldAuth "ENM";
BA_ "SignalLongName" SG_ 237 FCODPB13P_FVTS7MeasVldAuth "Front Camera Object Detection and Processing Burst 13 Protected : Forward Vision Traffic Sign 7 Measurement Valid Authenticated";
BA_ "SignalType" SG_ 237 FCODPB13P_FVTS7FiltTypAuth "ENM";
BA_ "SignalLongName" SG_ 237 FCODPB13P_FVTS7FiltTypAuth "Front Camera Object Detection and Processing Burst 13 Protected : Forward Vision Traffic Sign 7 Filter Type Authenticated";
BA_ "SignalLongName" SG_ 237 FCODPB13P_FVTS8AgeAuth "Front Camera Object Detection and Processing Burst 13 Protected : Forward Vision Traffic Sign 8 Age Authenticated";
BA_ "SignalLongName" SG_ 237 FCODPB13P_FVTS9AgeAuth "Front Camera Object Detection and Processing Burst 13 Protected : Forward Vision Traffic Sign 9 Age Authenticated";
BA_ "SignalType" SG_ 237 FCODPB13P_FVTS8ZnDtdAuth "ENM";
BA_ "SignalLongName" SG_ 237 FCODPB13P_FVTS8ZnDtdAuth "Front Camera Object Detection and Processing Burst 13 Protected : Forward Vision Traffic Sign 8 Zone Detected Authenticated";
BA_ "SignalType" SG_ 237 FCODPB13P_FVTS8PsdbyHstVehAuth "ENM";
BA_ "SignalLongName" SG_ 237 FCODPB13P_FVTS8PsdbyHstVehAuth "Front Camera Object Detection and Processing Burst 13 Protected : Forward Vision Traffic Sign 8 Passed by Host Vehicle Authenticated";
BA_ "SignalType" SG_ 237 FCODPB13P_FVTS8PhysTypAuth "ENM";
BA_ "SignalLongName" SG_ 237 FCODPB13P_FVTS8PhysTypAuth "Front Camera Object Detection and Processing Burst 13 Protected : Forward Vision Traffic Sign 8 Physical Type Authenticated";
BA_ "SignalType" SG_ 237 FCODPB13P_FVTS8MeasVldAuth "ENM";
BA_ "SignalLongName" SG_ 237 FCODPB13P_FVTS8MeasVldAuth "Front Camera Object Detection and Processing Burst 13 Protected : Forward Vision Traffic Sign 8 Measurement Valid Authenticated";
BA_ "SignalType" SG_ 237 FCODPB13P_FVTS8FiltTypAuth "ENM";
BA_ "SignalLongName" SG_ 237 FCODPB13P_FVTS8FiltTypAuth "Front Camera Object Detection and Processing Burst 13 Protected : Forward Vision Traffic Sign 8 Filter Type Authenticated";
BA_ "SignalType" SG_ 237 FCODPB13P_FVTS9FiltTypAuth "ENM";
BA_ "SignalLongName" SG_ 237 FCODPB13P_FVTS9FiltTypAuth "Front Camera Object Detection and Processing Burst 13 Protected : Forward Vision Traffic Sign 9 Filter Type Authenticated";
BA_ "SignalType" SG_ 237 FCODPB13P_FVTSTk10CnfdStsAuth "ENM";
BA_ "SignalLongName" SG_ 237 FCODPB13P_FVTSTk10CnfdStsAuth "Front Camera Object Detection and Processing Burst 13 Protected : Forward Vision Traffic Sign Track 10 Confidence Status Authenticated";
BA_ "SignalType" SG_ 237 FCODPB13P_FVTS9ZnDtdAuth "ENM";
BA_ "SignalLongName" SG_ 237 FCODPB13P_FVTS9ZnDtdAuth "Front Camera Object Detection and Processing Burst 13 Protected : Forward Vision Traffic Sign 9 Zone Detected Authenticated";
BA_ "SignalType" SG_ 237 FCODPB13P_FVTS9PsdbyHstVehAuth "ENM";
BA_ "SignalLongName" SG_ 237 FCODPB13P_FVTS9PsdbyHstVehAuth "Front Camera Object Detection and Processing Burst 13 Protected : Forward Vision Traffic Sign 9 Passed by Host Vehicle Authenticated";
BA_ "SignalType" SG_ 237 FCODPB13P_FVTS9PhysTypAuth "ENM";
BA_ "SignalLongName" SG_ 237 FCODPB13P_FVTS9PhysTypAuth "Front Camera Object Detection and Processing Burst 13 Protected : Forward Vision Traffic Sign 9 Physical Type Authenticated";
BA_ "SignalType" SG_ 237 FCODPB13P_FVTS9MeasVldAuth "ENM";
BA_ "SignalLongName" SG_ 237 FCODPB13P_FVTS9MeasVldAuth "Front Camera Object Detection and Processing Burst 13 Protected : Forward Vision Traffic Sign 9 Measurement Valid Authenticated";
BA_ "SignalLongName" SG_ 237 FCODPB13P_FVTSTk10LatPsAuth "Front Camera Object Detection and Processing Burst 13 Protected : Forward Vision Traffic Sign Track 10 Lateral Position Authenticated";
BA_ "SignalLongName" SG_ 237 FCODPB13P_FVTSTk10IDAuth "Front Camera Object Detection and Processing Burst 13 Protected : Forward Vision Traffic Sign Track 10 ID Authenticated";
BA_ "SignalLongName" SG_ 237 FCODPB13P_FVTSTk10LngPsAuth "Front Camera Object Detection and Processing Burst 13 Protected : Forward Vision Traffic Sign Track 10 Longitudinal Position Authenticated";
BA_ "SignalType" SG_ 237 FCODPB13P_FVTSTk10SupTypAuth "ENM";
BA_ "SignalLongName" SG_ 237 FCODPB13P_FVTSTk10SupTypAuth "Front Camera Object Detection and Processing Burst 13 Protected : Forward Vision Traffic Sign Track 10 Supplemental Type Authenticated";
BA_ "SignalType" SG_ 237 FCODPB13P_FVTSTk10MeasStsAuth "ENM";
BA_ "SignalLongName" SG_ 237 FCODPB13P_FVTSTk10MeasStsAuth "Front Camera Object Detection and Processing Burst 13 Protected : Forward Vision Traffic Sign Track 10 Measurement Status Authenticated";
BA_ "SignalType" SG_ 237 FCODPB13P_FVTSTk10TypAuth "ENM";
BA_ "SignalLongName" SG_ 237 FCODPB13P_FVTSTk10TypAuth "Front Camera Object Detection and Processing Burst 13 Protected : Forward Vision Traffic Sign Track 10 Type Authenticated";
BA_ "SignalLongName" SG_ 237 FCODPB13P_FVTSTk10VertPsAuth "Front Camera Object Detection and Processing Burst 13 Protected : Forward Vision Traffic Sign Track 10 Vertical Position Authenticated";
BA_ "SignalType" SG_ 237 FCODPB13P_FVTSTk10TypCnfdAuth "ENM";
BA_ "SignalLongName" SG_ 237 FCODPB13P_FVTSTk10TypCnfdAuth "Front Camera Object Detection and Processing Burst 13 Protected : Forward Vision Traffic Sign Track 10 Type Confidence Authenticated";
BA_ "SignalLongName" SG_ 237 FCODPB13P_FVTSTk1IDAuth "Front Camera Object Detection and Processing Burst 13 Protected : Forward Vision Traffic Sign Track 1 ID Authenticated";
BA_ "SignalType" SG_ 237 FCODPB13P_FVTSTk1CnfdStsAuth "ENM";
BA_ "SignalLongName" SG_ 237 FCODPB13P_FVTSTk1CnfdStsAuth "Front Camera Object Detection and Processing Burst 13 Protected : Forward Vision Traffic Sign Track 1 Confidence Status Authenticated";
BA_ "SignalLongName" SG_ 237 FCODPB13P_FVTSTk1LatPsAuth "Front Camera Object Detection and Processing Burst 13 Protected : Forward Vision Traffic Sign Track 1 Lateral Position Authenticated";
BA_ "SignalLongName" SG_ 237 FCODPB13P_FVTSTk1LngPsAuth "Front Camera Object Detection and Processing Burst 13 Protected : Forward Vision Traffic Sign Track 1 Longitudinal Position Authenticated";
BA_ "SignalType" SG_ 237 FCODPB13P_FVTSTk1MeasStsAuth "ENM";
BA_ "SignalLongName" SG_ 237 FCODPB13P_FVTSTk1MeasStsAuth "Front Camera Object Detection and Processing Burst 13 Protected : Forward Vision Traffic Sign Track 1 Measurement Status Authenticated";
BA_ "SignalType" SG_ 237 FCODPB13P_FVTSTk1TypAuth "ENM";
BA_ "SignalLongName" SG_ 237 FCODPB13P_FVTSTk1TypAuth "Front Camera Object Detection and Processing Burst 13 Protected : Forward Vision Traffic Sign Track 1 Type Authenticated";
BA_ "SignalType" SG_ 237 FCODPB13P_FVTSTk1SupTypAuth "ENM";
BA_ "SignalLongName" SG_ 237 FCODPB13P_FVTSTk1SupTypAuth "Front Camera Object Detection and Processing Burst 13 Protected : Forward Vision Traffic Sign Track 1 Supplemental Type Authenticated";
BA_ "SignalType" SG_ 237 FCODPB13P_FVTSTk1TypCnfdAuth "ENM";
BA_ "SignalLongName" SG_ 237 FCODPB13P_FVTSTk1TypCnfdAuth "Front Camera Object Detection and Processing Burst 13 Protected : Forward Vision Traffic Sign Track 1 Type Confidence Authenticated";
BA_ "SignalLongName" SG_ 237 FCODPB13P_FVTSTk1VertPsAuth "Front Camera Object Detection and Processing Burst 13 Protected : Forward Vision Traffic Sign Track 1 Vertical Position Authenticated";
BA_ "SignalLongName" SG_ 237 FCODPB13P_FVTSTk2IDAuth "Front Camera Object Detection and Processing Burst 13 Protected : Forward Vision Traffic Sign Track 2 ID Authenticated";
BA_ "SignalType" SG_ 237 FCODPB13P_FVTSTk2CnfdStsAuth "ENM";
BA_ "SignalLongName" SG_ 237 FCODPB13P_FVTSTk2CnfdStsAuth "Front Camera Object Detection and Processing Burst 13 Protected : Forward Vision Traffic Sign Track 2 Confidence Status Authenticated";
BA_ "SignalLongName" SG_ 237 FCODPB13P_FVTSTk2LatPsAuth "Front Camera Object Detection and Processing Burst 13 Protected : Forward Vision Traffic Sign Track 2 Lateral Position Authenticated";
BA_ "SignalLongName" SG_ 237 FCODPB13P_FVTSTk2LngPsAuth "Front Camera Object Detection and Processing Burst 13 Protected : Forward Vision Traffic Sign Track 2 Longitudinal Position Authenticated";
BA_ "SignalType" SG_ 237 FCODPB13P_FVTSTk2SupTypAuth "ENM";
BA_ "SignalLongName" SG_ 237 FCODPB13P_FVTSTk2SupTypAuth "Front Camera Object Detection and Processing Burst 13 Protected : Forward Vision Traffic Sign Track 2 Supplemental Type Authenticated";
BA_ "SignalType" SG_ 237 FCODPB13P_FVTSTk2MeasStsAuth "ENM";
BA_ "SignalLongName" SG_ 237 FCODPB13P_FVTSTk2MeasStsAuth "Front Camera Object Detection and Processing Burst 13 Protected : Forward Vision Traffic Sign Track 2 Measurement Status Authenticated";
BA_ "SignalType" SG_ 237 FCODPB13P_FVTSTk2TypAuth "ENM";
BA_ "SignalLongName" SG_ 237 FCODPB13P_FVTSTk2TypAuth "Front Camera Object Detection and Processing Burst 13 Protected : Forward Vision Traffic Sign Track 2 Type Authenticated";
BA_ "SignalLongName" SG_ 237 FCODPB13P_FVTSTk2VertPsAuth "Front Camera Object Detection and Processing Burst 13 Protected : Forward Vision Traffic Sign Track 2 Vertical Position Authenticated";
BA_ "SignalType" SG_ 237 FCODPB13P_FVTSTk2TypCnfdAuth "ENM";
BA_ "SignalLongName" SG_ 237 FCODPB13P_FVTSTk2TypCnfdAuth "Front Camera Object Detection and Processing Burst 13 Protected : Forward Vision Traffic Sign Track 2 Type Confidence Authenticated";
BA_ "SignalLongName" SG_ 237 FCODPB13P_FVTSTk3IDAuth "Front Camera Object Detection and Processing Burst 13 Protected : Forward Vision Traffic Sign Track 3 ID Authenticated";
BA_ "SignalType" SG_ 237 FCODPB13P_FVTSTk3CnfdStsAuth "ENM";
BA_ "SignalLongName" SG_ 237 FCODPB13P_FVTSTk3CnfdStsAuth "Front Camera Object Detection and Processing Burst 13 Protected : Forward Vision Traffic Sign Track 3 Confidence Status Authenticated";
BA_ "SignalLongName" SG_ 237 FCODPB13P_FVTSTk3LatPsAuth "Front Camera Object Detection and Processing Burst 13 Protected : Forward Vision Traffic Sign Track 3 Lateral Position Authenticated";
BA_ "SignalLongName" SG_ 237 FCODPB13P_FVTSTk3LngPsAuth "Front Camera Object Detection and Processing Burst 13 Protected : Forward Vision Traffic Sign Track 3 Longitudinal Position Authenticated";
BA_ "SignalType" SG_ 237 FCODPB13P_FVTSTk3SupTypAuth "ENM";
BA_ "SignalLongName" SG_ 237 FCODPB13P_FVTSTk3SupTypAuth "Front Camera Object Detection and Processing Burst 13 Protected : Forward Vision Traffic Sign Track 3 Supplemental Type Authenticated";
BA_ "SignalType" SG_ 237 FCODPB13P_FVTSTk3MeasStsAuth "ENM";
BA_ "SignalLongName" SG_ 237 FCODPB13P_FVTSTk3MeasStsAuth "Front Camera Object Detection and Processing Burst 13 Protected : Forward Vision Traffic Sign Track 3 Measurement Status Authenticated";
BA_ "SignalType" SG_ 237 FCODPB13P_FVTSTk3TypAuth "ENM";
BA_ "SignalLongName" SG_ 237 FCODPB13P_FVTSTk3TypAuth "Front Camera Object Detection and Processing Burst 13 Protected : Forward Vision Traffic Sign Track 3 Type Authenticated";
BA_ "SignalLongName" SG_ 237 FCODPB13P_FVTSTk3VertPsAuth "Front Camera Object Detection and Processing Burst 13 Protected : Forward Vision Traffic Sign Track 3 Vertical Position Authenticated";
BA_ "SignalType" SG_ 237 FCODPB13P_FVTSTk3TypCnfdAuth "ENM";
BA_ "SignalLongName" SG_ 237 FCODPB13P_FVTSTk3TypCnfdAuth "Front Camera Object Detection and Processing Burst 13 Protected : Forward Vision Traffic Sign Track 3 Type Confidence Authenticated";
BA_ "SignalLongName" SG_ 237 FCODPB13P_FVTSTk4IDAuth "Front Camera Object Detection and Processing Burst 13 Protected : Forward Vision Traffic Sign Track 4 ID Authenticated";
BA_ "SignalType" SG_ 237 FCODPB13P_FVTSTk4CnfdStsAuth "ENM";
BA_ "SignalLongName" SG_ 237 FCODPB13P_FVTSTk4CnfdStsAuth "Front Camera Object Detection and Processing Burst 13 Protected : Forward Vision Traffic Sign Track 4 Confidence Status Authenticated";
BA_ "SignalLongName" SG_ 237 FCODPB13P_FVTSTk4LatPsAuth "Front Camera Object Detection and Processing Burst 13 Protected : Forward Vision Traffic Sign Track 4 Lateral Position Authenticated";
BA_ "SignalLongName" SG_ 237 FCODPB13P_FVTSTk4LngPsAuth "Front Camera Object Detection and Processing Burst 13 Protected : Forward Vision Traffic Sign Track 4 Longitudinal Position Authenticated";
BA_ "SignalType" SG_ 237 FCODPB13P_FVTSTk4MeasStsAuth "ENM";
BA_ "SignalLongName" SG_ 237 FCODPB13P_FVTSTk4MeasStsAuth "Front Camera Object Detection and Processing Burst 13 Protected : Forward Vision Traffic Sign Track 4 Measurement Status Authenticated";
BA_ "SignalType" SG_ 237 FCODPB13P_FVTSTk4TypAuth "ENM";
BA_ "SignalLongName" SG_ 237 FCODPB13P_FVTSTk4TypAuth "Front Camera Object Detection and Processing Burst 13 Protected : Forward Vision Traffic Sign Track 4 Type Authenticated";
BA_ "SignalType" SG_ 237 FCODPB13P_FVTSTk4SupTypAuth "ENM";
BA_ "SignalLongName" SG_ 237 FCODPB13P_FVTSTk4SupTypAuth "Front Camera Object Detection and Processing Burst 13 Protected : Forward Vision Traffic Sign Track 4 Supplemental Type Authenticated";
BA_ "SignalLongName" SG_ 237 FCODPB13P_FVTSTk4VertPsAuth "Front Camera Object Detection and Processing Burst 13 Protected : Forward Vision Traffic Sign Track 4 Vertical Position Authenticated";
BA_ "SignalType" SG_ 237 FCODPB13P_FVTSTk4TypCnfdAuth "ENM";
BA_ "SignalLongName" SG_ 237 FCODPB13P_FVTSTk4TypCnfdAuth "Front Camera Object Detection and Processing Burst 13 Protected : Forward Vision Traffic Sign Track 4 Type Confidence Authenticated";
BA_ "SignalType" SG_ 237 FCODPB13P_FVTSTk5CnfdStsAuth "ENM";
BA_ "SignalLongName" SG_ 237 FCODPB13P_FVTSTk5CnfdStsAuth "Front Camera Object Detection and Processing Burst 13 Protected : Forward Vision Traffic Sign Track 5 Confidence Status Authenticated";
BA_ "SignalLongName" SG_ 237 FCODPB13P_FVTSTk5LatPsAuth "Front Camera Object Detection and Processing Burst 13 Protected : Forward Vision Traffic Sign Track 5 Lateral Position Authenticated";
BA_ "SignalLongName" SG_ 237 FCODPB13P_FVTSTk5IDAuth "Front Camera Object Detection and Processing Burst 13 Protected : Forward Vision Traffic Sign Track 5 ID Authenticated";
BA_ "SignalLongName" SG_ 237 FCODPB13P_FVTSTk5LngPsAuth "Front Camera Object Detection and Processing Burst 13 Protected : Forward Vision Traffic Sign Track 5 Longitudinal Position Authenticated";
BA_ "SignalType" SG_ 237 FCODPB13P_FVTSTk5SupTypAuth "ENM";
BA_ "SignalLongName" SG_ 237 FCODPB13P_FVTSTk5SupTypAuth "Front Camera Object Detection and Processing Burst 13 Protected : Forward Vision Traffic Sign Track 5 Supplemental Type Authenticated";
BA_ "SignalType" SG_ 237 FCODPB13P_FVTSTk5MeasStsAuth "ENM";
BA_ "SignalLongName" SG_ 237 FCODPB13P_FVTSTk5MeasStsAuth "Front Camera Object Detection and Processing Burst 13 Protected : Forward Vision Traffic Sign Track 5 Measurement Status Authenticated";
BA_ "SignalType" SG_ 237 FCODPB13P_FVTSTk5TypAuth "ENM";
BA_ "SignalLongName" SG_ 237 FCODPB13P_FVTSTk5TypAuth "Front Camera Object Detection and Processing Burst 13 Protected : Forward Vision Traffic Sign Track 5 Type Authenticated";
BA_ "SignalLongName" SG_ 237 FCODPB13P_FVTSTk5VertPsAuth "Front Camera Object Detection and Processing Burst 13 Protected : Forward Vision Traffic Sign Track 5 Vertical Position Authenticated";
BA_ "SignalType" SG_ 237 FCODPB13P_FVTSTk5TypCnfdAuth "ENM";
BA_ "SignalLongName" SG_ 237 FCODPB13P_FVTSTk5TypCnfdAuth "Front Camera Object Detection and Processing Burst 13 Protected : Forward Vision Traffic Sign Track 5 Type Confidence Authenticated";
BA_ "SignalLongName" SG_ 237 FCODPB13P_FVTSTk6IDAuth "Front Camera Object Detection and Processing Burst 13 Protected : Forward Vision Traffic Sign Track 6 ID Authenticated";
BA_ "SignalType" SG_ 237 FCODPB13P_FVTSTk6CnfdStsAuth "ENM";
BA_ "SignalLongName" SG_ 237 FCODPB13P_FVTSTk6CnfdStsAuth "Front Camera Object Detection and Processing Burst 13 Protected : Forward Vision Traffic Sign Track 6 Confidence Status Authenticated";
BA_ "SignalLongName" SG_ 237 FCODPB13P_FVTSTk6LatPsAuth "Front Camera Object Detection and Processing Burst 13 Protected : Forward Vision Traffic Sign Track 6 Lateral Position Authenticated";
BA_ "SignalLongName" SG_ 237 FCODPB13P_FVTSTk6LngPsAuth "Front Camera Object Detection and Processing Burst 13 Protected : Forward Vision Traffic Sign Track 6 Longitudinal Position Authenticated";
BA_ "SignalType" SG_ 237 FCODPB13P_FVTSTk6SupTypAuth "ENM";
BA_ "SignalLongName" SG_ 237 FCODPB13P_FVTSTk6SupTypAuth "Front Camera Object Detection and Processing Burst 13 Protected : Forward Vision Traffic Sign Track 6 Supplemental Type Authenticated";
BA_ "SignalType" SG_ 237 FCODPB13P_FVTSTk6MeasStsAuth "ENM";
BA_ "SignalLongName" SG_ 237 FCODPB13P_FVTSTk6MeasStsAuth "Front Camera Object Detection and Processing Burst 13 Protected : Forward Vision Traffic Sign Track 6 Measurement Status Authenticated";
BA_ "SignalType" SG_ 237 FCODPB13P_FVTSTk6TypCnfdAuth "ENM";
BA_ "SignalLongName" SG_ 237 FCODPB13P_FVTSTk6TypCnfdAuth "Front Camera Object Detection and Processing Burst 13 Protected : Forward Vision Traffic Sign Track 6 Type Confidence Authenticated";
BA_ "SignalType" SG_ 237 FCODPB13P_FVTSTk6TypAuth "ENM";
BA_ "SignalLongName" SG_ 237 FCODPB13P_FVTSTk6TypAuth "Front Camera Object Detection and Processing Burst 13 Protected : Forward Vision Traffic Sign Track 6 Type Authenticated";
BA_ "SignalLongName" SG_ 237 FCODPB13P_FVTSTk6VertPsAuth "Front Camera Object Detection and Processing Burst 13 Protected : Forward Vision Traffic Sign Track 6 Vertical Position Authenticated";
BA_ "SignalLongName" SG_ 237 FCODPB13P_FVTSTk7IDAuth "Front Camera Object Detection and Processing Burst 13 Protected : Forward Vision Traffic Sign Track 7 ID Authenticated";
BA_ "SignalType" SG_ 237 FCODPB13P_FVTSTk7CnfdStsAuth "ENM";
BA_ "SignalLongName" SG_ 237 FCODPB13P_FVTSTk7CnfdStsAuth "Front Camera Object Detection and Processing Burst 13 Protected : Forward Vision Traffic Sign Track 7 Confidence Status Authenticated";
BA_ "SignalLongName" SG_ 237 FCODPB13P_FVTSTk7LatPsAuth "Front Camera Object Detection and Processing Burst 13 Protected : Forward Vision Traffic Sign Track 7 Lateral Position Authenticated";
BA_ "SignalLongName" SG_ 237 FCODPB13P_FVTSTk7LngPsAuth "Front Camera Object Detection and Processing Burst 13 Protected : Forward Vision Traffic Sign Track 7 Longitudinal Position Authenticated";
BA_ "SignalType" SG_ 237 FCODPB13P_FVTSTk7SupTypAuth "ENM";
BA_ "SignalLongName" SG_ 237 FCODPB13P_FVTSTk7SupTypAuth "Front Camera Object Detection and Processing Burst 13 Protected : Forward Vision Traffic Sign Track 7 Supplemental Type Authenticated";
BA_ "SignalType" SG_ 237 FCODPB13P_FVTSTk7MeasStsAuth "ENM";
BA_ "SignalLongName" SG_ 237 FCODPB13P_FVTSTk7MeasStsAuth "Front Camera Object Detection and Processing Burst 13 Protected : Forward Vision Traffic Sign Track 7 Measurement Status Authenticated";
BA_ "SignalType" SG_ 237 FCODPB13P_FVTSTk7TypAuth "ENM";
BA_ "SignalLongName" SG_ 237 FCODPB13P_FVTSTk7TypAuth "Front Camera Object Detection and Processing Burst 13 Protected : Forward Vision Traffic Sign Track 7 Type Authenticated";
BA_ "SignalLongName" SG_ 237 FCODPB13P_FVTSTk7VertPsAuth "Front Camera Object Detection and Processing Burst 13 Protected : Forward Vision Traffic Sign Track 7 Vertical Position Authenticated";
BA_ "SignalType" SG_ 237 FCODPB13P_FVTSTk7TypCnfdAuth "ENM";
BA_ "SignalLongName" SG_ 237 FCODPB13P_FVTSTk7TypCnfdAuth "Front Camera Object Detection and Processing Burst 13 Protected : Forward Vision Traffic Sign Track 7 Type Confidence Authenticated";
VAL_ 1125 FrwdVsnBlkgSts 0 "UNKNOWN" 1 "NOT BLOCKED" 2 "FULL BLOCKAGE" 3 "PARTIAL BLOCKAGE" 4 "RESERVED3" 5 "RESERVED4" 6 "RESERVED5" 7 "RESERVED6" ;
VAL_ 1125 FrwdVsnAdvWthrSts 0 "CLEAR WEATHER" 1 "LIGHT FOG" 2 "MEDIUM FOG" 3 "HEAVY FOG" 4 "LIGHT SNOW" 5 "MEDIUM SNOW" 6 "HEAVY SNOW" 7 "LIGHT RAIN" 8 "MEDIUM RAIN" 9 "HEAVY RAIN" ;
VAL_ 1125 GlrFrHiBmSts 0 "OFF" 1 "AHBA" 2 "GFHB" ;
VAL_ 1125 FrwdVsnRdTyp 0 "TOWN" 1 "COUNTRY ROAD" 2 "MOTORWAY" 3 "RESERVED1" 4 "RESERVED2" 5 "RESERVED3" 6 "RESERVED 4" 7 "UNDEFINED" ;
VAL_ 1125 FrwdVsnEnvIllum 0 "UNKNOWN" 1 "LIT ENVIRONMENT DURING NIGHT" 2 "UNLIT ENVIRONMENT DURING NIGHT" 3 "DAYLIGHT" ;
VAL_ 1127 AutoHgBmActReq 0 "FALSE" 1 "TRUE" ;
VAL_ 131 ALOI1_TypTk1 0 "UNKNOWN" 1 "4 WHEEL VEHICLE" 2 "LARGE VEHICLE" 3 "MOTORCYCLE/BICYCLE" 4 "PEDESTRIAN" 5 "FIXED OVERHEAD OBJECT" 6 "FIXED ROADSIDE OBJECT" 7 "NO OBJECT PRESENT" 8 "PEDESTRIAN STANDING OUTSIDE DANGER ZONE" 9 "PEDESTRIAN MOVING OUT OF DANGER ZONE" 10 "PEDESTRIAN MOVING INTO DANGER ZONE" 11 "CHILD CLOSE TO DANGER ZONE" 12 "CLUSTER OBJECT" ;
VAL_ 131 ALOI1_TypTk3 0 "UNKNOWN" 1 "4 WHEEL VEHICLE" 2 "LARGE VEHICLE" 3 "MOTORCYCLE/BICYCLE" 4 "PEDESTRIAN" 5 "FIXED OVERHEAD OBJECT" 6 "FIXED ROADSIDE OBJECT" 7 "NO OBJECT PRESENT" 8 "PEDESTRIAN STANDING OUTSIDE DANGER ZONE" 9 "PEDESTRIAN MOVING OUT OF DANGER ZONE" 10 "PEDESTRIAN MOVING INTO DANGER ZONE" 11 "CHILD CLOSE TO DANGER ZONE" 12 "CLUSTER OBJECT" ;
VAL_ 131 ALOI1_TypTk2 0 "UNKNOWN" 1 "4 WHEEL VEHICLE" 2 "LARGE VEHICLE" 3 "MOTORCYCLE/BICYCLE" 4 "PEDESTRIAN" 5 "FIXED OVERHEAD OBJECT" 6 "FIXED ROADSIDE OBJECT" 7 "NO OBJECT PRESENT" 8 "PEDESTRIAN STANDING OUTSIDE DANGER ZONE" 9 "PEDESTRIAN MOVING OUT OF DANGER ZONE" 10 "PEDESTRIAN MOVING INTO DANGER ZONE" 11 "CHILD CLOSE TO DANGER ZONE" 12 "CLUSTER OBJECT" ;
VAL_ 131 ALOI1_DirTk1 0 "Following" 1 "Oncoming" 2 "Following Goup" 3 "Oncoming Group" 4 "Unknown" ;
VAL_ 131 ALOI1_TypTk4 0 "UNKNOWN" 1 "4 WHEEL VEHICLE" 2 "LARGE VEHICLE" 3 "MOTORCYCLE/BICYCLE" 4 "PEDESTRIAN" 5 "FIXED OVERHEAD OBJECT" 6 "FIXED ROADSIDE OBJECT" 7 "NO OBJECT PRESENT" 8 "PEDESTRIAN STANDING OUTSIDE DANGER ZONE" 9 "PEDESTRIAN MOVING OUT OF DANGER ZONE" 10 "PEDESTRIAN MOVING INTO DANGER ZONE" 11 "CHILD CLOSE TO DANGER ZONE" 12 "CLUSTER OBJECT" ;
VAL_ 131 ALOI1_DirTk3 0 "Following" 1 "Oncoming" 2 "Following Goup" 3 "Oncoming Group" 4 "Unknown" ;
VAL_ 131 ALOI1_DirTk2 0 "Following" 1 "Oncoming" 2 "Following Goup" 3 "Oncoming Group" 4 "Unknown" ;
VAL_ 131 ALOI1_CnfdTk2 0 "Highly Speculative" 1 "Speculative" 2 "Confident" 3 "Highly Confident" ;
VAL_ 131 ALOI1_CnfdTk1 0 "Highly Speculative" 1 "Speculative" 2 "Confident" 3 "Highly Confident" ;
VAL_ 131 ALOI1_DirTk4 0 "Following" 1 "Oncoming" 2 "Following Goup" 3 "Oncoming Group" 4 "Unknown" ;
VAL_ 131 ALOI1_MeasStsTk2 0 "No Object" 1 "New Object" 2 "Latent Track Not Detected This Cycle" 3 "Measured This Cycle" ;
VAL_ 131 ALOI1_MeasStsTk1 0 "No Object" 1 "New Object" 2 "Latent Track Not Detected This Cycle" 3 "Measured This Cycle" ;
VAL_ 131 ALOI1_CnfdTk4 0 "Highly Speculative" 1 "Speculative" 2 "Confident" 3 "Highly Confident" ;
VAL_ 131 ALOI1_CnfdTk3 0 "Highly Speculative" 1 "Speculative" 2 "Confident" 3 "Highly Confident" ;
VAL_ 131 ALOI1_RltvLnTk2 0 "Unknown" 1 "Host Lane" 2 "Right Lane" 3 "Left Lane" ;
VAL_ 131 ALOI1_RltvLnTk1 0 "Unknown" 1 "Host Lane" 2 "Right Lane" 3 "Left Lane" ;
VAL_ 131 ALOI1_MeasStsTk4 0 "No Object" 1 "New Object" 2 "Latent Track Not Detected This Cycle" 3 "Measured This Cycle" ;
VAL_ 131 ALOI1_MeasStsTk3 0 "No Object" 1 "New Object" 2 "Latent Track Not Detected This Cycle" 3 "Measured This Cycle" ;
VAL_ 131 ALOI1_RngTk2_Inv 0 "FALSE" 1 "TRUE" ;
VAL_ 131 ALOI1_RngTk1_Inv 0 "FALSE" 1 "TRUE" ;
VAL_ 131 ALOI1_AcqTmStm_Inv 0 "FALSE" 1 "TRUE" ;
VAL_ 131 ALOI1_RltvLnTk4 0 "Unknown" 1 "Host Lane" 2 "Right Lane" 3 "Left Lane" ;
VAL_ 131 ALOI1_RltvLnTk3 0 "Unknown" 1 "Host Lane" 2 "Right Lane" 3 "Left Lane" ;
VAL_ 131 ALOI1_RngTk4_Inv 0 "FALSE" 1 "TRUE" ;
VAL_ 131 ALOI1_RngTk3_Inv 0 "FALSE" 1 "TRUE" ;
VAL_ 136 ALOI2_TypTk5 0 "UNKNOWN" 1 "4 WHEEL VEHICLE" 2 "LARGE VEHICLE" 3 "MOTORCYCLE/BICYCLE" 4 "PEDESTRIAN" 5 "FIXED OVERHEAD OBJECT" 6 "FIXED ROADSIDE OBJECT" 7 "NO OBJECT PRESENT" 8 "PEDESTRIAN STANDING OUTSIDE DANGER ZONE" 9 "PEDESTRIAN MOVING OUT OF DANGER ZONE" 10 "PEDESTRIAN MOVING INTO DANGER ZONE" 11 "CHILD CLOSE TO DANGER ZONE" 12 "CLUSTER OBJECT" ;
VAL_ 136 ALOI2_TypTk7 0 "UNKNOWN" 1 "4 WHEEL VEHICLE" 2 "LARGE VEHICLE" 3 "MOTORCYCLE/BICYCLE" 4 "PEDESTRIAN" 5 "FIXED OVERHEAD OBJECT" 6 "FIXED ROADSIDE OBJECT" 7 "NO OBJECT PRESENT" 8 "PEDESTRIAN STANDING OUTSIDE DANGER ZONE" 9 "PEDESTRIAN MOVING OUT OF DANGER ZONE" 10 "PEDESTRIAN MOVING INTO DANGER ZONE" 11 "CHILD CLOSE TO DANGER ZONE" 12 "CLUSTER OBJECT" ;
VAL_ 136 ALOI2_TypTk6 0 "UNKNOWN" 1 "4 WHEEL VEHICLE" 2 "LARGE VEHICLE" 3 "MOTORCYCLE/BICYCLE" 4 "PEDESTRIAN" 5 "FIXED OVERHEAD OBJECT" 6 "FIXED ROADSIDE OBJECT" 7 "NO OBJECT PRESENT" 8 "PEDESTRIAN STANDING OUTSIDE DANGER ZONE" 9 "PEDESTRIAN MOVING OUT OF DANGER ZONE" 10 "PEDESTRIAN MOVING INTO DANGER ZONE" 11 "CHILD CLOSE TO DANGER ZONE" 12 "CLUSTER OBJECT" ;
VAL_ 136 ALOI2_DirTk5 0 "Following" 1 "Oncoming" 2 "Following Goup" 3 "Oncoming Group" 4 "Unknown" ;
VAL_ 136 ALOI2_TypTk8 0 "UNKNOWN" 1 "4 WHEEL VEHICLE" 2 "LARGE VEHICLE" 3 "MOTORCYCLE/BICYCLE" 4 "PEDESTRIAN" 5 "FIXED OVERHEAD OBJECT" 6 "FIXED ROADSIDE OBJECT" 7 "NO OBJECT PRESENT" 8 "PEDESTRIAN STANDING OUTSIDE DANGER ZONE" 9 "PEDESTRIAN MOVING OUT OF DANGER ZONE" 10 "PEDESTRIAN MOVING INTO DANGER ZONE" 11 "CHILD CLOSE TO DANGER ZONE" 12 "CLUSTER OBJECT" ;
VAL_ 136 ALOI2_DirTk7 0 "Following" 1 "Oncoming" 2 "Following Goup" 3 "Oncoming Group" 4 "Unknown" ;
VAL_ 136 ALOI2_DirTk6 0 "Following" 1 "Oncoming" 2 "Following Goup" 3 "Oncoming Group" 4 "Unknown" ;
VAL_ 136 ALOI2_CnfdTk6 0 "Highly Speculative" 1 "Speculative" 2 "Confident" 3 "Highly Confident" ;
VAL_ 136 ALOI2_CnfdTk5 0 "Highly Speculative" 1 "Speculative" 2 "Confident" 3 "Highly Confident" ;
VAL_ 136 ALOI2_DirTk8 0 "Following" 1 "Oncoming" 2 "Following Goup" 3 "Oncoming Group" 4 "Unknown" ;
VAL_ 136 ALOI2_MeasStsTk6 0 "No Object" 1 "New Object" 2 "Latent Track Not Detected This Cycle" 3 "Measured This Cycle" ;
VAL_ 136 ALOI2_MeasStsTk5 0 "No Object" 1 "New Object" 2 "Latent Track Not Detected This Cycle" 3 "Measured This Cycle" ;
VAL_ 136 ALOI2_CnfdTk8 0 "Highly Speculative" 1 "Speculative" 2 "Confident" 3 "Highly Confident" ;
VAL_ 136 ALOI2_CnfdTk7 0 "Highly Speculative" 1 "Speculative" 2 "Confident" 3 "Highly Confident" ;
VAL_ 136 ALOI2_RltvLnTk6 0 "Unknown" 1 "Host Lane" 2 "Right Lane" 3 "Left Lane" ;
VAL_ 136 ALOI2_RltvLnTk5 0 "Unknown" 1 "Host Lane" 2 "Right Lane" 3 "Left Lane" ;
VAL_ 136 ALOI2_MeasStsTk8 0 "No Object" 1 "New Object" 2 "Latent Track Not Detected This Cycle" 3 "Measured This Cycle" ;
VAL_ 136 ALOI2_MeasStsTk7 0 "No Object" 1 "New Object" 2 "Latent Track Not Detected This Cycle" 3 "Measured This Cycle" ;
VAL_ 136 ALOI2_RngTk6_Inv 0 "FALSE" 1 "TRUE" ;
VAL_ 136 ALOI2_RngTk5_Inv 0 "FALSE" 1 "TRUE" ;
VAL_ 136 ALOI2_AcqTmStm_Inv 0 "FALSE" 1 "TRUE" ;
VAL_ 136 ALOI2_RltvLnTk8 0 "Unknown" 1 "Host Lane" 2 "Right Lane" 3 "Left Lane" ;
VAL_ 136 ALOI2_RltvLnTk7 0 "Unknown" 1 "Host Lane" 2 "Right Lane" 3 "Left Lane" ;
VAL_ 136 ALOI2_RngTk8_Inv 0 "FALSE" 1 "TRUE" ;
VAL_ 136 ALOI2_RngTk7_Inv 0 "FALSE" 1 "TRUE" ;
VAL_ 41 ARDG1_HstLnLtTyp 0 "Undecided" 1 "Solid" 2 "Dashed" 3 "Road Edge" 4 "Double Line" 5 "Botts Dots" 6 "Virtual" 7 "Triple Line" ;
VAL_ 41 ARDG1_HstLnLtQlty 0 "Very Low Quality" 1 "Low Quality" 2 "Prediction" 3 "High Quality" ;
VAL_ 41 ARDG1_HstNxtLnLtTyp 0 "Undecided" 1 "Solid" 2 "Dashed" 3 "Road Edge" 4 "Double Line" 5 "Botts Dots" 6 "Virtual" 7 "Triple Line" ;
VAL_ 41 ARDG1_HstNxtLnLtQlty 0 "Very Low Quality" 1 "Low Quality" 2 "Prediction" 3 "High Quality" ;
VAL_ 41 ARDG1_LtVehAhdMeasSts 0 "No Object" 1 "New Object" 2 "Latent Track Not Detected this Cycle" 3 "Measured this Cycle" ;
VAL_ 41 ARDG2_AutfxOutOfCal 0 "Unknown" 1 "Yaw" 2 "Horizon" 3 "Both" ;
VAL_ 41 ARDG2_FrwdCamSysOprtgSts 0 "Unknown" 1 "Initializing" 2 "Inactive" 3 "Active" 4 "Programing" 5 "Reserved 1" 6 "Reserved 2" 7 "Failed" ;
VAL_ 41 ARDG2_HstVehAhdMeasSts 0 "No Object" 1 "New Object" 2 "Latent Track Not Detected this Cycle" 3 "Measured this Cycle" ;
VAL_ 41 ARDG2_FrwdVsnUnv 0 "FALSE" 1 "TRUE" ;
VAL_ 41 ARDG2_FrwdVsnTmStm_Inv 0 "FALSE" 1 "TRUE" ;
VAL_ 42 ARDG3_HstLnRtTyp 0 "Undecided" 1 "Solid" 2 "Dashed" 3 "Road Edge" 4 "Double Line" 5 "Botts Dots" 6 "Virtual" 7 "Triple Line" ;
VAL_ 42 ARDG3_HstLnRtQlty 0 "Very Low Quality" 1 "Low Quality" 2 "Prediction" 3 "High Quality" ;
VAL_ 42 ARDG3_HstNxtLnRtTyp 0 "Undecided" 1 "Solid" 2 "Dashed" 3 "Road Edge" 4 "Double Line" 5 "Botts Dots" 6 "Virtual" 7 "Triple Line" ;
VAL_ 42 ARDG3_HstNxtLnRtQlty 0 "Very Low Quality" 1 "Low Quality" 2 "Prediction" 3 "High Quality" ;
VAL_ 42 ARDG3_RtVehAhdMeasSts 0 "No Object" 1 "New Object" 2 "Latent Track Not Detected this Cycle" 3 "Measured this Cycle" ;
VAL_ 525 BSPMP_SecRunCrnkCmdActvAuth_Inv 0 "FALSE" 1 "TRUE" ;
VAL_ 525 BSPMP_SecRunCrnkCmdActvAuth 0 "FALSE" 1 "TRUE" ;
VAL_ 525 BSPMP_SecPwrModePBActvAuth_Inv 0 "FALSE" 1 "TRUE" ;
VAL_ 525 BSPMP_SecPwrModePBActvAuth 0 "FALSE" 1 "TRUE" ;
VAL_ 525 BSPMP_BkupSysPwrModeAuth_Inv 0 "FALSE" 1 "TRUE" ;
VAL_ 525 BSPMP_BkupSysPwrModeAuth 0 "Off" 1 "Accessory" 2 "Run" 3 "Start Request" 4 "Propulsion" ;
VAL_ 525 BSPMP_RmtProgmActvAuth 0 "FALSE" 1 "TRUE" ;
VAL_ 227 FCODPB11P_FVVOTk10PoI4PsVisAuth 0 "Unknown" 1 "Visible" 2 "Projected" ;
VAL_ 227 FCODPB11P_FVVOTk1PoI4PsVisAuth 0 "Unknown" 1 "Visible" 2 "Projected" ;
VAL_ 227 FCODPB11P_FVVOTk2PoI4PsVisAuth 0 "Unknown" 1 "Visible" 2 "Projected" ;
VAL_ 227 FCODPB11P_FVVOTk3PoI4PsVisAuth 0 "Unknown" 1 "Visible" 2 "Projected" ;
VAL_ 227 FCODPB11P_FVVOTk4PoI4PsVisAuth 0 "Unknown" 1 "Visible" 2 "Projected" ;
VAL_ 227 FCODPB11P_FVVOTk5PoI4PsVisAuth 0 "Unknown" 1 "Visible" 2 "Projected" ;
VAL_ 227 FCODPB11P_FVVOTk6PoI4PsVisAuth 0 "Unknown" 1 "Visible" 2 "Projected" ;
VAL_ 227 FCODPB11P_FVVOTk7PoI4PsVisAuth 0 "Unknown" 1 "Visible" 2 "Projected" ;
VAL_ 227 FCODPB11P_FVVOTk8PoI4PsVisAuth 0 "Unknown" 1 "Visible" 2 "Projected" ;
VAL_ 227 FCODPB11P_FVVOTk9PoI4PsVisAuth 0 "Unknown" 1 "Visible" 2 "Projected" ;
VAL_ 227 FCODPB11P_LnTrPtEndTypAuth 0 "Unknown" 1 "Merge End" 2 "Split End" ;
VAL_ 227 FCODPB11P_LnTrPtStrtTypAuth 0 "Unknown" 1 "Merge Start" 2 "Split Start" ;
VAL_ 227 FCODPB11P_FrwdVsnModeCmdStsAuth 0 "Not Reporting Object Data" 1 "Reporting Object Data" ;
VAL_ 227 FCODPB11P_ShldrDtnRtofVehAuth 0 "Shoulder Not Detected" 1 "Shoulder Detected" 2 "Reserved" 3 "Not Valid" ;
VAL_ 227 FCODPB11P_ShldrDtnLtofVehAuth 0 "Shoulder Not Detected" 1 "Shoulder Detected" 2 "Reserved" 3 "Not Valid" ;
VAL_ 236 FCODPB12P_FVTS1PsdbyHstVehAuth 0 "FALSE" 1 "TRUE" ;
VAL_ 236 FCODPB12P_FVTS1PhysTypAuth 0 "Static" 1 "Variable" 2 "Temporary" ;
VAL_ 236 FCODPB12P_FVTS1MeasVldAuth 0 "FALSE" 1 "TRUE" ;
VAL_ 236 FCODPB12P_FVTS1FiltTypAuth 0 "Not Filtered" 1 "Irrelevant To Host Driver" 2 "On Vehicle/Truck" 3 "Embedded" ;
VAL_ 236 FCODPB12P_FVTS1ZnDtdAuth 0 "FALSE" 1 "TRUE" ;
VAL_ 236 FCODPB12P_FVTS2ZnDtdAuth 0 "FALSE" 1 "TRUE" ;
VAL_ 236 FCODPB12P_FVTS2PsdbyHstVehAuth 0 "FALSE" 1 "TRUE" ;
VAL_ 236 FCODPB12P_FVTS2PhysTypAuth 0 "Static" 1 "Variable" 2 "Temporary" ;
VAL_ 236 FCODPB12P_FVTS2MeasVldAuth 0 "FALSE" 1 "TRUE" ;
VAL_ 236 FCODPB12P_FVTS2FiltTypAuth 0 "Not Filtered" 1 "Irrelevant To Host Driver" 2 "On Vehicle/Truck" 3 "Embedded" ;
VAL_ 236 FCODPB12P_FVTS3ZnDtdAuth 0 "FALSE" 1 "TRUE" ;
VAL_ 236 FCODPB12P_FVTS3PsdbyHstVehAuth 0 "FALSE" 1 "TRUE" ;
VAL_ 236 FCODPB12P_FVTS3PhysTypAuth 0 "Static" 1 "Variable" 2 "Temporary" ;
VAL_ 236 FCODPB12P_FVTS3MeasVldAuth 0 "FALSE" 1 "TRUE" ;
VAL_ 236 FCODPB12P_FVTS3FiltTypAuth 0 "Not Filtered" 1 "Irrelevant To Host Driver" 2 "On Vehicle/Truck" 3 "Embedded" ;
VAL_ 236 FCODPB12P_FVTS4FiltTypAuth 0 "Not Filtered" 1 "Irrelevant To Host Driver" 2 "On Vehicle/Truck" 3 "Embedded" ;
VAL_ 236 FCODPB12P_FVTS4ZnDtdAuth 0 "FALSE" 1 "TRUE" ;
VAL_ 236 FCODPB12P_FVTS4PsdbyHstVehAuth 0 "FALSE" 1 "TRUE" ;
VAL_ 236 FCODPB12P_FVTS4PhysTypAuth 0 "Static" 1 "Variable" 2 "Temporary" ;
VAL_ 236 FCODPB12P_FVTS4MeasVldAuth 0 "FALSE" 1 "TRUE" ;
VAL_ 236 FCODPB12P_FVTS5FiltTypAuth 0 "Not Filtered" 1 "Irrelevant To Host Driver" 2 "On Vehicle/Truck" 3 "Embedded" ;
VAL_ 236 FCODPB12P_FVTS5ZnDtdAuth 0 "FALSE" 1 "TRUE" ;
VAL_ 236 FCODPB12P_FVTS5PsdbyHstVehAuth 0 "FALSE" 1 "TRUE" ;
VAL_ 236 FCODPB12P_FVTS5PhysTypAuth 0 "Static" 1 "Variable" 2 "Temporary" ;
VAL_ 236 FCODPB12P_FVTS5MeasVldAuth 0 "FALSE" 1 "TRUE" ;
VAL_ 236 FCODPB12P_FVTS6MeasVldAuth 0 "FALSE" 1 "TRUE" ;
VAL_ 236 FCODPB12P_FVTS6FiltTypAuth 0 "Not Filtered" 1 "Irrelevant To Host Driver" 2 "On Vehicle/Truck" 3 "Embedded" ;
VAL_ 236 FCODPB12P_RdBnkCrv1CnfdStsAuth 0 "Highly Speculative" 1 "Speculative" 2 "Confident" 3 "Highly Confident" ;
VAL_ 236 FCODPB12P_FVTS6ZnDtdAuth 0 "FALSE" 1 "TRUE" ;
VAL_ 236 FCODPB12P_FVTS6PsdbyHstVehAuth 0 "FALSE" 1 "TRUE" ;
VAL_ 236 FCODPB12P_FVTS6PhysTypAuth 0 "Static" 1 "Variable" 2 "Temporary" ;
VAL_ 236 FCODPB12P_RdBnkCrv2CnfdStsAuth 0 "Highly Speculative" 1 "Speculative" 2 "Confident" 3 "Highly Confident" ;
VAL_ 236 FCODPB12P_RdBnkCrv3CnfdStsAuth 0 "Highly Speculative" 1 "Speculative" 2 "Confident" 3 "Highly Confident" ;
VAL_ 237 FCODPB13P_FVTS10PsdbyHstVehAuth 0 "FALSE" 1 "TRUE" ;
VAL_ 237 FCODPB13P_FVTS10PhysTypAuth 0 "Static" 1 "Variable" 2 "Temporary" ;
VAL_ 237 FCODPB13P_FVTS10MeasVldAuth 0 "FALSE" 1 "TRUE" ;
VAL_ 237 FCODPB13P_FVTS10FiltTypAuth 0 "Not Filtered" 1 "Irrelevant To Host Driver" 2 "On Vehicle/Truck" 3 "Embedded" ;
VAL_ 237 FCODPB13P_FVTS10ZnDtdAuth 0 "FALSE" 1 "TRUE" ;
VAL_ 237 FCODPB13P_FVTS7ZnDtdAuth 0 "FALSE" 1 "TRUE" ;
VAL_ 237 FCODPB13P_FVTS7PsdbyHstVehAuth 0 "FALSE" 1 "TRUE" ;
VAL_ 237 FCODPB13P_FVTS7PhysTypAuth 0 "Static" 1 "Variable" 2 "Temporary" ;
VAL_ 237 FCODPB13P_FVTS7MeasVldAuth 0 "FALSE" 1 "TRUE" ;
VAL_ 237 FCODPB13P_FVTS7FiltTypAuth 0 "Not Filtered" 1 "Irrelevant To Host Driver" 2 "On Vehicle/Truck" 3 "Embedded" ;
VAL_ 237 FCODPB13P_FVTS8ZnDtdAuth 0 "FALSE" 1 "TRUE" ;
VAL_ 237 FCODPB13P_FVTS8PsdbyHstVehAuth 0 "FALSE" 1 "TRUE" ;
VAL_ 237 FCODPB13P_FVTS8PhysTypAuth 0 "Static" 1 "Variable" 2 "Temporary" ;
VAL_ 237 FCODPB13P_FVTS8MeasVldAuth 0 "FALSE" 1 "TRUE" ;
VAL_ 237 FCODPB13P_FVTS8FiltTypAuth 0 "Not Filtered" 1 "Irrelevant To Host Driver" 2 "On Vehicle/Truck" 3 "Embedded" ;
VAL_ 237 FCODPB13P_FVTS9FiltTypAuth 0 "Not Filtered" 1 "Irrelevant To Host Driver" 2 "On Vehicle/Truck" 3 "Embedded" ;
VAL_ 237 FCODPB13P_FVTSTk10CnfdStsAuth 0 "Highly Speculative" 1 "Speculative" 2 "Confident" 3 "Highly Confident" ;
VAL_ 237 FCODPB13P_FVTS9ZnDtdAuth 0 "FALSE" 1 "TRUE" ;
VAL_ 237 FCODPB13P_FVTS9PsdbyHstVehAuth 0 "FALSE" 1 "TRUE" ;
VAL_ 237 FCODPB13P_FVTS9PhysTypAuth 0 "Static" 1 "Variable" 2 "Temporary" ;
VAL_ 237 FCODPB13P_FVTS9MeasVldAuth 0 "FALSE" 1 "TRUE" ;
VAL_ 237 FCODPB13P_FVTSTk10SupTypAuth 0 "None" 1 "Rain" 2 "Snow" 3 "Trailer" 4 "Time" 5 "Arrow Left" 6 "Arrow Right" 7 "Bend Arrow Left" 8 "Bend Arrow Right" 9 "Truck" 10 "Distance Arrow" 11 "Weight" 12 "Distance In" 13 "Tractor" 14 "Snow Rain" 15 "School" 16 "Rain Cloud" 17 "Fog" 18 "Hazardous" 19 "Material" 20 "Night" 21 "Supp Sign Generic" 22 "Rappel" 23 "Tractor Passable" 24 "Wet Conditions" 25 "Motorcycle" 26 "Bus" 27 "Camper" 28 "Car" 29 "Tank" 30 "Hazard Spot" 31 "Traffic Jam" 32 "Train" 33 "Tram/Street Car" 34 "Noise Prevention" 35 "Residents Only" 36 "Invalid Supp" 37 "School When Flashing" 38 "End of Speed Limit" 39 "Where Workers Present" ;
VAL_ 237 FCODPB13P_FVTSTk10MeasStsAuth 0 "No Object" 1 "New Object" 2 "Latent Track Not Detected this Cycle" 3 "Measured this Cycle" ;
VAL_ 237 FCODPB13P_FVTSTk10TypAuth 0 "No Sign Detected" 1 "End of Speed Limit" 2 "End of All Restrictions" 3 "Begin of Motorway" 4 "End of Motorway" 5 "Begin of Expressway" 6 "End of Expressway" 7 "Begin of Play Street Zone" 8 "End of Play Street Zone" 9 "Begin of Passing Restriction" 10 "End of Passing Restriction" 11 "No Entry" 12 "Begin of City Limits" 13 "End of City Limits" 14 "Yield" 15 "Crosswalk" 16 "Round About" 17 "Stop Sign" 18 "Yield to Oncoming Traffic" 19 "Pedestrian Zone" 20 "No Stopping Sign" 21 "No Parking Sign" 22 "Begin of No Parking Zone" 23 "End of No Parking Zone" 24 "Invalid Sign" 25 "Unknown Sign" 26 "Speed Limit 5" 27 "Speed Limit 10" 28 "Speed Limit 15" 29 "Speed Limit 20" 30 "Speed Limit 25" 31 "Speed Limit 30" 32 "Speed Limit 35" 33 "Speed Limit 40" 34 "Speed Limit 45" 35 "Speed Limit 50" 36 "Speed Limit 55" 37 "Speed Limit 60" 38 "Speed Limit 65" 39 "Speed Limit 70" 40 "Speed Limit 75" 41 "Speed Limit 80" 42 "Speed Limit 85" 43 "Speed Limit 90" 44 "Speed Limit 95" 45 "Speed Limit 100" 46 "Speed Limit 105" 47 "Speed Limit 110" 48 "Speed Limit 115" 49 "Speed Limit 120" 50 "Speed Limit 125" 51 "Speed Limit 130" 52 "Speed Limit 135" 53 "Speed Limit 140" 54 "Speed Limit 145" 55 "Speed Limit 150" 56 "Attention Sign Construction" 57 "Attention Sign Crosswalk" 58 "Attention Sign Round About" 59 "Attention Sign Children" 60 "Attention Sign Animals Crossing" 61 "Attention Sign General" 62 "Attention Sign Cross-way" 63 "Attention Sign Sharp Turn Left" 64 "Attention Sign Sharp Turn Right" 65 "Attention Sign Winding Road" 66 "Attention Sign Up-Grade" 67 "Attention Sign Down-Grade" 68 "Attention Sign Narrow Road Left" 69 "Attention Sign Narrow Road Right" 70 "Attention Sign Narrow Road Left & Right" 71 "Attention Sign Slippery Raod" 72 "Restricted Access for All Vehicles" 73 "Restricted Access for Cars" 74 "Restricted Access for Cars & Motorcycles" 75 "Restricted Access for Campers" ;
VAL_ 237 FCODPB13P_FVTSTk10TypCnfdAuth 0 "Highly Speculative" 1 "Speculative" 2 "Confident" 3 "Highly Confident" ;
VAL_ 237 FCODPB13P_FVTSTk1CnfdStsAuth 0 "Highly Speculative" 1 "Speculative" 2 "Confident" 3 "Highly Confident" ;
VAL_ 237 FCODPB13P_FVTSTk1MeasStsAuth 0 "No Object" 1 "New Object" 2 "Latent Track Not Detected this Cycle" 3 "Measured this Cycle" ;
VAL_ 237 FCODPB13P_FVTSTk1TypAuth 0 "No Sign Detected" 1 "End of Speed Limit" 2 "End of All Restrictions" 3 "Begin of Motorway" 4 "End of Motorway" 5 "Begin of Expressway" 6 "End of Expressway" 7 "Begin of Play Street Zone" 8 "End of Play Street Zone" 9 "Begin of Passing Restriction" 10 "End of Passing Restriction" 11 "No Entry" 12 "Begin of City Limits" 13 "End of City Limits" 14 "Yield" 15 "Crosswalk" 16 "Round About" 17 "Stop Sign" 18 "Yield to Oncoming Traffic" 19 "Pedestrian Zone" 20 "No Stopping Sign" 21 "No Parking Sign" 22 "Begin of No Parking Zone" 23 "End of No Parking Zone" 24 "Invalid Sign" 25 "Unknown Sign" 26 "Speed Limit 5" 27 "Speed Limit 10" 28 "Speed Limit 15" 29 "Speed Limit 20" 30 "Speed Limit 25" 31 "Speed Limit 30" 32 "Speed Limit 35" 33 "Speed Limit 40" 34 "Speed Limit 45" 35 "Speed Limit 50" 36 "Speed Limit 55" 37 "Speed Limit 60" 38 "Speed Limit 65" 39 "Speed Limit 70" 40 "Speed Limit 75" 41 "Speed Limit 80" 42 "Speed Limit 85" 43 "Speed Limit 90" 44 "Speed Limit 95" 45 "Speed Limit 100" 46 "Speed Limit 105" 47 "Speed Limit 110" 48 "Speed Limit 115" 49 "Speed Limit 120" 50 "Speed Limit 125" 51 "Speed Limit 130" 52 "Speed Limit 135" 53 "Speed Limit 140" 54 "Speed Limit 145" 55 "Speed Limit 150" 56 "Attention Sign Construction" 57 "Attention Sign Crosswalk" 58 "Attention Sign Round About" 59 "Attention Sign Children" 60 "Attention Sign Animals Crossing" 61 "Attention Sign General" 62 "Attention Sign Cross-way" 63 "Attention Sign Sharp Turn Left" 64 "Attention Sign Sharp Turn Right" 65 "Attention Sign Winding Road" 66 "Attention Sign Up-Grade" 67 "Attention Sign Down-Grade" 68 "Attention Sign Narrow Road Left" 69 "Attention Sign Narrow Road Right" 70 "Attention Sign Narrow Road Left & Right" 71 "Attention Sign Slippery Raod" 72 "Restricted Access for All Vehicles" 73 "Restricted Access for Cars" 74 "Restricted Access for Cars & Motorcycles" 75 "Restricted Access for Campers" ;
VAL_ 237 FCODPB13P_FVTSTk1SupTypAuth 0 "None" 1 "Rain" 2 "Snow" 3 "Trailer" 4 "Time" 5 "Arrow Left" 6 "Arrow Right" 7 "Bend Arrow Left" 8 "Bend Arrow Right" 9 "Truck" 10 "Distance Arrow" 11 "Weight" 12 "Distance In" 13 "Tractor" 14 "Snow Rain" 15 "School" 16 "Rain Cloud" 17 "Fog" 18 "Hazardous" 19 "Material" 20 "Night" 21 "Supp Sign Generic" 22 "Rappel" 23 "Tractor Passable" 24 "Wet Conditions" 25 "Motorcycle" 26 "Bus" 27 "Camper" 28 "Car" 29 "Tank" 30 "Hazard Spot" 31 "Traffic Jam" 32 "Train" 33 "Tram/Street Car" 34 "Noise Prevention" 35 "Residents Only" 36 "Invalid Supp" 37 "School When Flashing" 38 "End of Speed Limit" 39 "Where Workers Present" ;
VAL_ 237 FCODPB13P_FVTSTk1TypCnfdAuth 0 "Highly Speculative" 1 "Speculative" 2 "Confident" 3 "Highly Confident" ;
VAL_ 237 FCODPB13P_FVTSTk2CnfdStsAuth 0 "Highly Speculative" 1 "Speculative" 2 "Confident" 3 "Highly Confident" ;
VAL_ 237 FCODPB13P_FVTSTk2SupTypAuth 0 "None" 1 "Rain" 2 "Snow" 3 "Trailer" 4 "Time" 5 "Arrow Left" 6 "Arrow Right" 7 "Bend Arrow Left" 8 "Bend Arrow Right" 9 "Truck" 10 "Distance Arrow" 11 "Weight" 12 "Distance In" 13 "Tractor" 14 "Snow Rain" 15 "School" 16 "Rain Cloud" 17 "Fog" 18 "Hazardous" 19 "Material" 20 "Night" 21 "Supp Sign Generic" 22 "Rappel" 23 "Tractor Passable" 24 "Wet Conditions" 25 "Motorcycle" 26 "Bus" 27 "Camper" 28 "Car" 29 "Tank" 30 "Hazard Spot" 31 "Traffic Jam" 32 "Train" 33 "Tram/Street Car" 34 "Noise Prevention" 35 "Residents Only" 36 "Invalid Supp" 37 "School When Flashing" 38 "End of Speed Limit" 39 "Where Workers Present" ;
VAL_ 237 FCODPB13P_FVTSTk2MeasStsAuth 0 "No Object" 1 "New Object" 2 "Latent Track Not Detected this Cycle" 3 "Measured this Cycle" ;
VAL_ 237 FCODPB13P_FVTSTk2TypAuth 0 "No Sign Detected" 1 "End of Speed Limit" 2 "End of All Restrictions" 3 "Begin of Motorway" 4 "End of Motorway" 5 "Begin of Expressway" 6 "End of Expressway" 7 "Begin of Play Street Zone" 8 "End of Play Street Zone" 9 "Begin of Passing Restriction" 10 "End of Passing Restriction" 11 "No Entry" 12 "Begin of City Limits" 13 "End of City Limits" 14 "Yield" 15 "Crosswalk" 16 "Round About" 17 "Stop Sign" 18 "Yield to Oncoming Traffic" 19 "Pedestrian Zone" 20 "No Stopping Sign" 21 "No Parking Sign" 22 "Begin of No Parking Zone" 23 "End of No Parking Zone" 24 "Invalid Sign" 25 "Unknown Sign" 26 "Speed Limit 5" 27 "Speed Limit 10" 28 "Speed Limit 15" 29 "Speed Limit 20" 30 "Speed Limit 25" 31 "Speed Limit 30" 32 "Speed Limit 35" 33 "Speed Limit 40" 34 "Speed Limit 45" 35 "Speed Limit 50" 36 "Speed Limit 55" 37 "Speed Limit 60" 38 "Speed Limit 65" 39 "Speed Limit 70" 40 "Speed Limit 75" 41 "Speed Limit 80" 42 "Speed Limit 85" 43 "Speed Limit 90" 44 "Speed Limit 95" 45 "Speed Limit 100" 46 "Speed Limit 105" 47 "Speed Limit 110" 48 "Speed Limit 115" 49 "Speed Limit 120" 50 "Speed Limit 125" 51 "Speed Limit 130" 52 "Speed Limit 135" 53 "Speed Limit 140" 54 "Speed Limit 145" 55 "Speed Limit 150" 56 "Attention Sign Construction" 57 "Attention Sign Crosswalk" 58 "Attention Sign Round About" 59 "Attention Sign Children" 60 "Attention Sign Animals Crossing" 61 "Attention Sign General" 62 "Attention Sign Cross-way" 63 "Attention Sign Sharp Turn Left" 64 "Attention Sign Sharp Turn Right" 65 "Attention Sign Winding Road" 66 "Attention Sign Up-Grade" 67 "Attention Sign Down-Grade" 68 "Attention Sign Narrow Road Left" 69 "Attention Sign Narrow Road Right" 70 "Attention Sign Narrow Road Left & Right" 71 "Attention Sign Slippery Raod" 72 "Restricted Access for All Vehicles" 73 "Restricted Access for Cars" 74 "Restricted Access for Cars & Motorcycles" 75 "Restricted Access for Campers" ;
VAL_ 237 FCODPB13P_FVTSTk2TypCnfdAuth 0 "Highly Speculative" 1 "Speculative" 2 "Confident" 3 "Highly Confident" ;
VAL_ 237 FCODPB13P_FVTSTk3CnfdStsAuth 0 "Highly Speculative" 1 "Speculative" 2 "Confident" 3 "Highly Confident" ;
VAL_ 237 FCODPB13P_FVTSTk3SupTypAuth 0 "None" 1 "Rain" 2 "Snow" 3 "Trailer" 4 "Time" 5 "Arrow Left" 6 "Arrow Right" 7 "Bend Arrow Left" 8 "Bend Arrow Right" 9 "Truck" 10 "Distance Arrow" 11 "Weight" 12 "Distance In" 13 "Tractor" 14 "Snow Rain" 15 "School" 16 "Rain Cloud" 17 "Fog" 18 "Hazardous" 19 "Material" 20 "Night" 21 "Supp Sign Generic" 22 "Rappel" 23 "Tractor Passable" 24 "Wet Conditions" 25 "Motorcycle" 26 "Bus" 27 "Camper" 28 "Car" 29 "Tank" 30 "Hazard Spot" 31 "Traffic Jam" 32 "Train" 33 "Tram/Street Car" 34 "Noise Prevention" 35 "Residents Only" 36 "Invalid Supp" 37 "School When Flashing" 38 "End of Speed Limit" 39 "Where Workers Present" ;
VAL_ 237 FCODPB13P_FVTSTk3MeasStsAuth 0 "No Object" 1 "New Object" 2 "Latent Track Not Detected this Cycle" 3 "Measured this Cycle" ;
VAL_ 237 FCODPB13P_FVTSTk3TypAuth 0 "No Sign Detected" 1 "End of Speed Limit" 2 "End of All Restrictions" 3 "Begin of Motorway" 4 "End of Motorway" 5 "Begin of Expressway" 6 "End of Expressway" 7 "Begin of Play Street Zone" 8 "End of Play Street Zone" 9 "Begin of Passing Restriction" 10 "End of Passing Restriction" 11 "No Entry" 12 "Begin of City Limits" 13 "End of City Limits" 14 "Yield" 15 "Crosswalk" 16 "Round About" 17 "Stop Sign" 18 "Yield to Oncoming Traffic" 19 "Pedestrian Zone" 20 "No Stopping Sign" 21 "No Parking Sign" 22 "Begin of No Parking Zone" 23 "End of No Parking Zone" 24 "Invalid Sign" 25 "Unknown Sign" 26 "Speed Limit 5" 27 "Speed Limit 10" 28 "Speed Limit 15" 29 "Speed Limit 20" 30 "Speed Limit 25" 31 "Speed Limit 30" 32 "Speed Limit 35" 33 "Speed Limit 40" 34 "Speed Limit 45" 35 "Speed Limit 50" 36 "Speed Limit 55" 37 "Speed Limit 60" 38 "Speed Limit 65" 39 "Speed Limit 70" 40 "Speed Limit 75" 41 "Speed Limit 80" 42 "Speed Limit 85" 43 "Speed Limit 90" 44 "Speed Limit 95" 45 "Speed Limit 100" 46 "Speed Limit 105" 47 "Speed Limit 110" 48 "Speed Limit 115" 49 "Speed Limit 120" 50 "Speed Limit 125" 51 "Speed Limit 130" 52 "Speed Limit 135" 53 "Speed Limit 140" 54 "Speed Limit 145" 55 "Speed Limit 150" 56 "Attention Sign Construction" 57 "Attention Sign Crosswalk" 58 "Attention Sign Round About" 59 "Attention Sign Children" 60 "Attention Sign Animals Crossing" 61 "Attention Sign General" 62 "Attention Sign Cross-way" 63 "Attention Sign Sharp Turn Left" 64 "Attention Sign Sharp Turn Right" 65 "Attention Sign Winding Road" 66 "Attention Sign Up-Grade" 67 "Attention Sign Down-Grade" 68 "Attention Sign Narrow Road Left" 69 "Attention Sign Narrow Road Right" 70 "Attention Sign Narrow Road Left & Right" 71 "Attention Sign Slippery Raod" 72 "Restricted Access for All Vehicles" 73 "Restricted Access for Cars" 74 "Restricted Access for Cars & Motorcycles" 75 "Restricted Access for Campers" ;
VAL_ 237 FCODPB13P_FVTSTk3TypCnfdAuth 0 "Highly Speculative" 1 "Speculative" 2 "Confident" 3 "Highly Confident" ;
VAL_ 237 FCODPB13P_FVTSTk4CnfdStsAuth 0 "Highly Speculative" 1 "Speculative" 2 "Confident" 3 "Highly Confident" ;
VAL_ 237 FCODPB13P_FVTSTk4MeasStsAuth 0 "No Object" 1 "New Object" 2 "Latent Track Not Detected this Cycle" 3 "Measured this Cycle" ;
VAL_ 237 FCODPB13P_FVTSTk4TypAuth 0 "No Sign Detected" 1 "End of Speed Limit" 2 "End of All Restrictions" 3 "Begin of Motorway" 4 "End of Motorway" 5 "Begin of Expressway" 6 "End of Expressway" 7 "Begin of Play Street Zone" 8 "End of Play Street Zone" 9 "Begin of Passing Restriction" 10 "End of Passing Restriction" 11 "No Entry" 12 "Begin of City Limits" 13 "End of City Limits" 14 "Yield" 15 "Crosswalk" 16 "Round About" 17 "Stop Sign" 18 "Yield to Oncoming Traffic" 19 "Pedestrian Zone" 20 "No Stopping Sign" 21 "No Parking Sign" 22 "Begin of No Parking Zone" 23 "End of No Parking Zone" 24 "Invalid Sign" 25 "Unknown Sign" 26 "Speed Limit 5" 27 "Speed Limit 10" 28 "Speed Limit 15" 29 "Speed Limit 20" 30 "Speed Limit 25" 31 "Speed Limit 30" 32 "Speed Limit 35" 33 "Speed Limit 40" 34 "Speed Limit 45" 35 "Speed Limit 50" 36 "Speed Limit 55" 37 "Speed Limit 60" 38 "Speed Limit 65" 39 "Speed Limit 70" 40 "Speed Limit 75" 41 "Speed Limit 80" 42 "Speed Limit 85" 43 "Speed Limit 90" 44 "Speed Limit 95" 45 "Speed Limit 100" 46 "Speed Limit 105" 47 "Speed Limit 110" 48 "Speed Limit 115" 49 "Speed Limit 120" 50 "Speed Limit 125" 51 "Speed Limit 130" 52 "Speed Limit 135" 53 "Speed Limit 140" 54 "Speed Limit 145" 55 "Speed Limit 150" 56 "Attention Sign Construction" 57 "Attention Sign Crosswalk" 58 "Attention Sign Round About" 59 "Attention Sign Children" 60 "Attention Sign Animals Crossing" 61 "Attention Sign General" 62 "Attention Sign Cross-way" 63 "Attention Sign Sharp Turn Left" 64 "Attention Sign Sharp Turn Right" 65 "Attention Sign Winding Road" 66 "Attention Sign Up-Grade" 67 "Attention Sign Down-Grade" 68 "Attention Sign Narrow Road Left" 69 "Attention Sign Narrow Road Right" 70 "Attention Sign Narrow Road Left & Right" 71 "Attention Sign Slippery Raod" 72 "Restricted Access for All Vehicles" 73 "Restricted Access for Cars" 74 "Restricted Access for Cars & Motorcycles" 75 "Restricted Access for Campers" ;
VAL_ 237 FCODPB13P_FVTSTk4SupTypAuth 0 "None" 1 "Rain" 2 "Snow" 3 "Trailer" 4 "Time" 5 "Arrow Left" 6 "Arrow Right" 7 "Bend Arrow Left" 8 "Bend Arrow Right" 9 "Truck" 10 "Distance Arrow" 11 "Weight" 12 "Distance In" 13 "Tractor" 14 "Snow Rain" 15 "School" 16 "Rain Cloud" 17 "Fog" 18 "Hazardous" 19 "Material" 20 "Night" 21 "Supp Sign Generic" 22 "Rappel" 23 "Tractor Passable" 24 "Wet Conditions" 25 "Motorcycle" 26 "Bus" 27 "Camper" 28 "Car" 29 "Tank" 30 "Hazard Spot" 31 "Traffic Jam" 32 "Train" 33 "Tram/Street Car" 34 "Noise Prevention" 35 "Residents Only" 36 "Invalid Supp" 37 "School When Flashing" 38 "End of Speed Limit" 39 "Where Workers Present" ;
VAL_ 237 FCODPB13P_FVTSTk4TypCnfdAuth 0 "Highly Speculative" 1 "Speculative" 2 "Confident" 3 "Highly Confident" ;
VAL_ 237 FCODPB13P_FVTSTk5CnfdStsAuth 0 "Highly Speculative" 1 "Speculative" 2 "Confident" 3 "Highly Confident" ;
VAL_ 237 FCODPB13P_FVTSTk5SupTypAuth 0 "None" 1 "Rain" 2 "Snow" 3 "Trailer" 4 "Time" 5 "Arrow Left" 6 "Arrow Right" 7 "Bend Arrow Left" 8 "Bend Arrow Right" 9 "Truck" 10 "Distance Arrow" 11 "Weight" 12 "Distance In" 13 "Tractor" 14 "Snow Rain" 15 "School" 16 "Rain Cloud" 17 "Fog" 18 "Hazardous" 19 "Material" 20 "Night" 21 "Supp Sign Generic" 22 "Rappel" 23 "Tractor Passable" 24 "Wet Conditions" 25 "Motorcycle" 26 "Bus" 27 "Camper" 28 "Car" 29 "Tank" 30 "Hazard Spot" 31 "Traffic Jam" 32 "Train" 33 "Tram/Street Car" 34 "Noise Prevention" 35 "Residents Only" 36 "Invalid Supp" 37 "School When Flashing" 38 "End of Speed Limit" 39 "Where Workers Present" ;
VAL_ 237 FCODPB13P_FVTSTk5MeasStsAuth 0 "No Object" 1 "New Object" 2 "Latent Track Not Detected this Cycle" 3 "Measured this Cycle" ;
VAL_ 237 FCODPB13P_FVTSTk5TypAuth 0 "No Sign Detected" 1 "End of Speed Limit" 2 "End of All Restrictions" 3 "Begin of Motorway" 4 "End of Motorway" 5 "Begin of Expressway" 6 "End of Expressway" 7 "Begin of Play Street Zone" 8 "End of Play Street Zone" 9 "Begin of Passing Restriction" 10 "End of Passing Restriction" 11 "No Entry" 12 "Begin of City Limits" 13 "End of City Limits" 14 "Yield" 15 "Crosswalk" 16 "Round About" 17 "Stop Sign" 18 "Yield to Oncoming Traffic" 19 "Pedestrian Zone" 20 "No Stopping Sign" 21 "No Parking Sign" 22 "Begin of No Parking Zone" 23 "End of No Parking Zone" 24 "Invalid Sign" 25 "Unknown Sign" 26 "Speed Limit 5" 27 "Speed Limit 10" 28 "Speed Limit 15" 29 "Speed Limit 20" 30 "Speed Limit 25" 31 "Speed Limit 30" 32 "Speed Limit 35" 33 "Speed Limit 40" 34 "Speed Limit 45" 35 "Speed Limit 50" 36 "Speed Limit 55" 37 "Speed Limit 60" 38 "Speed Limit 65" 39 "Speed Limit 70" 40 "Speed Limit 75" 41 "Speed Limit 80" 42 "Speed Limit 85" 43 "Speed Limit 90" 44 "Speed Limit 95" 45 "Speed Limit 100" 46 "Speed Limit 105" 47 "Speed Limit 110" 48 "Speed Limit 115" 49 "Speed Limit 120" 50 "Speed Limit 125" 51 "Speed Limit 130" 52 "Speed Limit 135" 53 "Speed Limit 140" 54 "Speed Limit 145" 55 "Speed Limit 150" 56 "Attention Sign Construction" 57 "Attention Sign Crosswalk" 58 "Attention Sign Round About" 59 "Attention Sign Children" 60 "Attention Sign Animals Crossing" 61 "Attention Sign General" 62 "Attention Sign Cross-way" 63 "Attention Sign Sharp Turn Left" 64 "Attention Sign Sharp Turn Right" 65 "Attention Sign Winding Road" 66 "Attention Sign Up-Grade" 67 "Attention Sign Down-Grade" 68 "Attention Sign Narrow Road Left" 69 "Attention Sign Narrow Road Right" 70 "Attention Sign Narrow Road Left & Right" 71 "Attention Sign Slippery Raod" 72 "Restricted Access for All Vehicles" 73 "Restricted Access for Cars" 74 "Restricted Access for Cars & Motorcycles" 75 "Restricted Access for Campers" ;
VAL_ 237 FCODPB13P_FVTSTk5TypCnfdAuth 0 "Highly Speculative" 1 "Speculative" 2 "Confident" 3 "Highly Confident" ;
VAL_ 237 FCODPB13P_FVTSTk6CnfdStsAuth 0 "Highly Speculative" 1 "Speculative" 2 "Confident" 3 "Highly Confident" ;
VAL_ 237 FCODPB13P_FVTSTk6SupTypAuth 0 "None" 1 "Rain" 2 "Snow" 3 "Trailer" 4 "Time" 5 "Arrow Left" 6 "Arrow Right" 7 "Bend Arrow Left" 8 "Bend Arrow Right" 9 "Truck" 10 "Distance Arrow" 11 "Weight" 12 "Distance In" 13 "Tractor" 14 "Snow Rain" 15 "School" 16 "Rain Cloud" 17 "Fog" 18 "Hazardous" 19 "Material" 20 "Night" 21 "Supp Sign Generic" 22 "Rappel" 23 "Tractor Passable" 24 "Wet Conditions" 25 "Motorcycle" 26 "Bus" 27 "Camper" 28 "Car" 29 "Tank" 30 "Hazard Spot" 31 "Traffic Jam" 32 "Train" 33 "Tram/Street Car" 34 "Noise Prevention" 35 "Residents Only" 36 "Invalid Supp" 37 "School When Flashing" 38 "End of Speed Limit" 39 "Where Workers Present" ;
VAL_ 237 FCODPB13P_FVTSTk6MeasStsAuth 0 "No Object" 1 "New Object" 2 "Latent Track Not Detected this Cycle" 3 "Measured this Cycle" ;
VAL_ 237 FCODPB13P_FVTSTk6TypCnfdAuth 0 "Highly Speculative" 1 "Speculative" 2 "Confident" 3 "Highly Confident" ;
VAL_ 237 FCODPB13P_FVTSTk6TypAuth 0 "No Sign Detected" 1 "End of Speed Limit" 2 "End of All Restrictions" 3 "Begin of Motorway" 4 "End of Motorway" 5 "Begin of Expressway" 6 "End of Expressway" 7 "Begin of Play Street Zone" 8 "End of Play Street Zone" 9 "Begin of Passing Restriction" 10 "End of Passing Restriction" 11 "No Entry" 12 "Begin of City Limits" 13 "End of City Limits" 14 "Yield" 15 "Crosswalk" 16 "Round About" 17 "Stop Sign" 18 "Yield to Oncoming Traffic" 19 "Pedestrian Zone" 20 "No Stopping Sign" 21 "No Parking Sign" 22 "Begin of No Parking Zone" 23 "End of No Parking Zone" 24 "Invalid Sign" 25 "Unknown Sign" 26 "Speed Limit 5" 27 "Speed Limit 10" 28 "Speed Limit 15" 29 "Speed Limit 20" 30 "Speed Limit 25" 31 "Speed Limit 30" 32 "Speed Limit 35" 33 "Speed Limit 40" 34 "Speed Limit 45" 35 "Speed Limit 50" 36 "Speed Limit 55" 37 "Speed Limit 60" 38 "Speed Limit 65" 39 "Speed Limit 70" 40 "Speed Limit 75" 41 "Speed Limit 80" 42 "Speed Limit 85" 43 "Speed Limit 90" 44 "Speed Limit 95" 45 "Speed Limit 100" 46 "Speed Limit 105" 47 "Speed Limit 110" 48 "Speed Limit 115" 49 "Speed Limit 120" 50 "Speed Limit 125" 51 "Speed Limit 130" 52 "Speed Limit 135" 53 "Speed Limit 140" 54 "Speed Limit 145" 55 "Speed Limit 150" 56 "Attention Sign Construction" 57 "Attention Sign Crosswalk" 58 "Attention Sign Round About" 59 "Attention Sign Children" 60 "Attention Sign Animals Crossing" 61 "Attention Sign General" 62 "Attention Sign Cross-way" 63 "Attention Sign Sharp Turn Left" 64 "Attention Sign Sharp Turn Right" 65 "Attention Sign Winding Road" 66 "Attention Sign Up-Grade" 67 "Attention Sign Down-Grade" 68 "Attention Sign Narrow Road Left" 69 "Attention Sign Narrow Road Right" 70 "Attention Sign Narrow Road Left & Right" 71 "Attention Sign Slippery Raod" 72 "Restricted Access for All Vehicles" 73 "Restricted Access for Cars" 74 "Restricted Access for Cars & Motorcycles" 75 "Restricted Access for Campers" ;
VAL_ 237 FCODPB13P_FVTSTk7CnfdStsAuth 0 "Highly Speculative" 1 "Speculative" 2 "Confident" 3 "Highly Confident" ;
VAL_ 237 FCODPB13P_FVTSTk7SupTypAuth 0 "None" 1 "Rain" 2 "Snow" 3 "Trailer" 4 "Time" 5 "Arrow Left" 6 "Arrow Right" 7 "Bend Arrow Left" 8 "Bend Arrow Right" 9 "Truck" 10 "Distance Arrow" 11 "Weight" 12 "Distance In" 13 "Tractor" 14 "Snow Rain" 15 "School" 16 "Rain Cloud" 17 "Fog" 18 "Hazardous" 19 "Material" 20 "Night" 21 "Supp Sign Generic" 22 "Rappel" 23 "Tractor Passable" 24 "Wet Conditions" 25 "Motorcycle" 26 "Bus" 27 "Camper" 28 "Car" 29 "Tank" 30 "Hazard Spot" 31 "Traffic Jam" 32 "Train" 33 "Tram/Street Car" 34 "Noise Prevention" 35 "Residents Only" 36 "Invalid Supp" 37 "School When Flashing" 38 "End of Speed Limit" 39 "Where Workers Present" ;
VAL_ 237 FCODPB13P_FVTSTk7MeasStsAuth 0 "No Object" 1 "New Object" 2 "Latent Track Not Detected this Cycle" 3 "Measured this Cycle" ;
VAL_ 237 FCODPB13P_FVTSTk7TypAuth 0 "No Sign Detected" 1 "End of Speed Limit" 2 "End of All Restrictions" 3 "Begin of Motorway" 4 "End of Motorway" 5 "Begin of Expressway" 6 "End of Expressway" 7 "Begin of Play Street Zone" 8 "End of Play Street Zone" 9 "Begin of Passing Restriction" 10 "End of Passing Restriction" 11 "No Entry" 12 "Begin of City Limits" 13 "End of City Limits" 14 "Yield" 15 "Crosswalk" 16 "Round About" 17 "Stop Sign" 18 "Yield to Oncoming Traffic" 19 "Pedestrian Zone" 20 "No Stopping Sign" 21 "No Parking Sign" 22 "Begin of No Parking Zone" 23 "End of No Parking Zone" 24 "Invalid Sign" 25 "Unknown Sign" 26 "Speed Limit 5" 27 "Speed Limit 10" 28 "Speed Limit 15" 29 "Speed Limit 20" 30 "Speed Limit 25" 31 "Speed Limit 30" 32 "Speed Limit 35" 33 "Speed Limit 40" 34 "Speed Limit 45" 35 "Speed Limit 50" 36 "Speed Limit 55" 37 "Speed Limit 60" 38 "Speed Limit 65" 39 "Speed Limit 70" 40 "Speed Limit 75" 41 "Speed Limit 80" 42 "Speed Limit 85" 43 "Speed Limit 90" 44 "Speed Limit 95" 45 "Speed Limit 100" 46 "Speed Limit 105" 47 "Speed Limit 110" 48 "Speed Limit 115" 49 "Speed Limit 120" 50 "Speed Limit 125" 51 "Speed Limit 130" 52 "Speed Limit 135" 53 "Speed Limit 140" 54 "Speed Limit 145" 55 "Speed Limit 150" 56 "Attention Sign Construction" 57 "Attention Sign Crosswalk" 58 "Attention Sign Round About" 59 "Attention Sign Children" 60 "Attention Sign Animals Crossing" 61 "Attention Sign General" 62 "Attention Sign Cross-way" 63 "Attention Sign Sharp Turn Left" 64 "Attention Sign Sharp Turn Right" 65 "Attention Sign Winding Road" 66 "Attention Sign Up-Grade" 67 "Attention Sign Down-Grade" 68 "Attention Sign Narrow Road Left" 69 "Attention Sign Narrow Road Right" 70 "Attention Sign Narrow Road Left & Right" 71 "Attention Sign Slippery Raod" 72 "Restricted Access for All Vehicles" 73 "Restricted Access for Cars" 74 "Restricted Access for Cars & Motorcycles" 75 "Restricted Access for Campers" ;
VAL_ 237 FCODPB13P_FVTSTk7TypCnfdAuth 0 "Highly Speculative" 1 "Speculative" 2 "Confident" 3 "Highly Confident" ;
